VERSION ""

NS_ :

BS_:

BU_: IVI ZCU_F

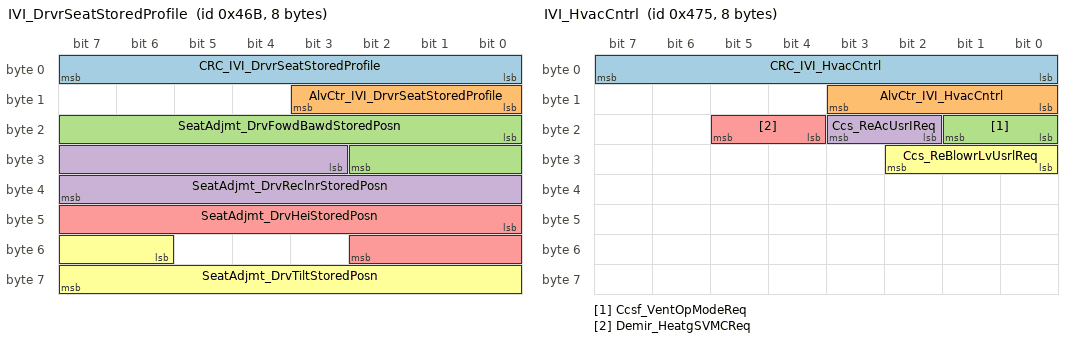
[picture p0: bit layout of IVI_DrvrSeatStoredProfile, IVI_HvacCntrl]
BO_ 1131 IVI_DrvrSeatStoredProfile: 8 IVI
 SG_ CRC_IVI_DrvrSeatStoredProfile : 0|8@1+ (1,0) [0|255] ""  ZCU_F
 SG_ AlvCtr_IVI_DrvrSeatStoredProfile : 8|4@1+ (1,0) [0|14] ""  ZCU_F
 SG_ SeatAdjmt_DrvFowdBawdStoredPosn : 16|11@1+ (1,0) [0|1400] "Count"  ZCU_F
 SG_ SeatAdjmt_DrvReclnrStoredPosn : 27|13@1+ (1,0) [0|5000] "Count"  ZCU_F
 SG_ SeatAdjmt_DrvHeiStoredPosn : 40|11@1+ (1,0) [0|1600] "Count"  ZCU_F
 SG_ SeatAdjmt_DrvTiltStoredPosn : 54|10@1+ (1,0) [0|1000] "Count"  ZCU_F

BO_ 1140 TBOX_DrvrId_Info: 16 ZCU_F
 SG_ DriverId_Byte1 : 0|8@1+ (1,0) [0|255] ""  IVI
 SG_ DriverId_Byte2 : 8|8@1+ (1,0) [0|255] ""  IVI
 SG_ DriverId_Byte3 : 16|8@1+ (1,0) [0|255] ""  IVI
 SG_ DriverId_Byte4 : 24|8@1+ (1,0) [0|255] ""  IVI
 SG_ DriverId_Byte5 : 32|8@1+ (1,0) [0|255] ""  IVI
 SG_ DriverId_Byte6 : 40|8@1+ (1,0) [0|255] ""  IVI
 SG_ DriverId_Byte7 : 48|8@1+ (1,0) [0|255] ""  IVI
 SG_ DriverId_Byte8 : 56|8@1+ (1,0) [0|255] ""  IVI
 SG_ DriverId_Byte9 : 64|8@1+ (1,0) [0|255] ""  IVI
 SG_ DriverId_Byte10 : 72|8@1+ (1,0) [0|255] ""  IVI
 SG_ DriverId_Byte11 : 80|8@1+ (1,0) [0|255] ""  IVI
 SG_ DriverId_Byte12 : 88|8@1+ (1,0) [0|255] ""  IVI
 SG_ DriverId_Byte13 : 96|8@1+ (1,0) [0|255] ""  IVI
 SG_ DriverId_Byte14 : 104|8@1+ (1,0) [0|255] ""  IVI
 SG_ DriverId_Byte15 : 112|8@1+ (1,0) [0|255] ""  IVI
 SG_ DriverId_Byte16 : 120|8@1+ (1,0) [0|255] ""  IVI

BO_ 1141 IVI_HvacCntrl: 8 IVI
 SG_ CRC_IVI_HvacCntrl : 0|8@1+ (1,0) [0|255] ""  ZCU_F
 SG_ AlvCtr_IVI_HvacCntrl : 8|4@1+ (1,0) [0|14] ""  ZCU_F
 SG_ Ccsf_VentOpModeReq : 16|2@1+ (1,0) [0|3] ""  ZCU_F
 SG_ Ccs_ReAcUsrIReq : 18|2@1+ (1,0) [0|3] ""  ZCU_F
 SG_ Demir_HeatgSVMCReq : 20|2@1+ (1,0) [0|3] ""  ZCU_F
 SG_ Ccs_ReBlowrLvUsrlReq : 24|3@1+ (1,0) [0|7] ""  ZCU_F

BO_ 1147 IVI_HvacSwt_Req: 8 IVI
 SG_ Ccs_AcMinTUsrBtn : 0|2@1+ (1,0) [0|3] ""  ZCU_F
 SG_ Ccs_AcMaxTUsrBtn : 2|2@1+ (1,0) [0|3] ""  ZCU_F
 SG_ Ccs_RclOnOffReq : 4|2@1+ (1,0) [0|3] ""  ZCU_F
 SG_ Ccs_FrntAcUsrReq : 6|2@1+ (1,0) [0|3] ""  ZCU_F
 SG_ Ccs_ReLeTUsrSetReq : 8|4@1+ (1,16) [16|28] "°C"  ZCU_F
 SG_ Ccs_ReRiTUsrISetVal : 12|4@1+ (1,16) [16|28] "°C"  ZCU_F
 SG_ Ccs_SyncTReq : 16|2@1+ (1,0) [0|3] ""  ZCU_F
 SG_ Ccs_AcEcoModeBtnUsrReq : 18|2@1+ (1,0) [0|3] ""  ZCU_F
 SG_ Ccs_FrntAcAutoModUsrReq : 20|2@1+ (1,0) [0|3] ""  ZCU_F
 SG_ Ccs_IoniserUsrReq : 22|2@1+ (1,0) [0|3] ""  ZCU_F
 SG_ Ccs_FrgrncAcvnUsrReq : 24|2@1+ (1,0) [0|3] ""  ZCU_F
 SG_ Ccs_DemistDefrstUsrReq : 26|2@1+ (1,0) [0|3] ""  ZCU_F
 SG_ Ccs_FrntLeTUsrSetVal : 28|4@1+ (1,16) [16|28] "°C"  ZCU_F
 SG_ Ccs_FrgrncIntenUsrReq : 32|4@1+ (10,0) [0|100] ""  ZCU_F
 SG_ Ccs_FrntBlowrLvlUsrReq : 40|3@1+ (1,0) [0|7] ""  ZCU_F
 SG_ Ccs_AirModeSelnUsrReq : 43|3@1+ (1,0) [0|7] ""  ZCU_F
 SG_ Ccs_FrntRiTUsrSetVal : 48|4@1+ (1,16) [16|28] "°C"  ZCU_F
 SG_ Ccs_ClimPrsetUsrReq : 52|3@1+ (1,0) [0|7] ""  ZCU_F
 SG_ Ccs_FrgrncSlenUsrReq : 56|3@1+ (1,0) [0|7] ""  ZCU_F
 SG_ Ccs_ClimPrflSelnUsrReq : 59|3@1+ (1,0) [0|7] ""  ZCU_F

BO_ 1157 IVI_UsrBodyCntrl_Req: 32 IVI
 SG_ CRC_IVI_UsrBodyCntrl_Req : 0|16@1+ (1,0) [0|65535] ""  ZCU_F
 SG_ AlvCtr_IVI_UsrBodyCntrl_Req : 16|8@1+ (1,0) [0|255] ""  ZCU_F
 SG_ ChrgrPort_ChrgPortLckUnlckUsrReq : 24|2@1+ (1,0) [0|3] ""  ZCU_F
 SG_ Demir_FoldUnfoldSVMCReq : 26|2@1+ (1,0) [0|3] ""  ZCU_F
 SG_ Demir_FoldUnfoldUsrReq : 28|2@1+ (1,0) [0|3] ""  ZCU_F
 SG_ Demir_HeatgSVMC_Ena : 30|2@1+ (1,0) [0|3] ""  ZCU_F
 SG_ Acttg_TailGateUsrAgReq : 32|7@1+ (1,0) [0|100] "%"  ZCU_F
 SG_ Acttg_TailGateUsrReq : 40|2@1+ (1,0) [0|3] ""  ZCU_F
 SG_ Ssadl_AutoSpdLockVal : 42|6@1+ (1,0) [0|50] "kmph"  ZCU_F
 SG_ Ssadl_AutoSpdLockOnOffTypSts : 48|2@1+ (1,0) [0|3] ""  ZCU_F
 SG_ Relamp_ReFogLiReq : 50|2@1+ (1,0) [0|3] ""  ZCU_F
 SG_ Hdlamp_LampReq : 52|2@1+ (1,0) [0|3] ""  ZCU_F
 SG_ Hdlamp_AutoModeCfgReq : 54|2@1+ (1,0) [0|3] ""  ZCU_F
 SG_ Hdlamp_FollowMeCfg : 56|3@1+ (1,0) [0|7] ""  ZCU_F
 SG_ Wipr_FrntWiprReq : 59|3@1+ (1,0) [0|7] ""  ZCU_F
 SG_ Wipr_FrntOperParkReq : 62|2@1+ (1,0) [0|3] ""  ZCU_F
 SG_ Wipr_FrntWiprSrvPosReq : 64|2@1+ (1,0) [0|3] ""  ZCU_F

BO_ 1163 IVI_UsrChassisCntrl_Req: 32 IVI
 SG_ CRC_IVI_UsrChassisCntrl_Req : 0|16@1+ (1,0) [0|65535] ""  ZCU_F
 SG_ AlvCtr_IVI_UsrChassisCntrl_Req : 16|8@1+ (1,0) [0|255] ""  ZCU_F
 SG_ Hdc_SwtSts : 24|2@1+ (1,0) [0|3] ""  ZCU_F
 SG_ EscTcs_SwtSts : 26|2@1+ (1,0) [0|3] ""  ZCU_F
 SG_ IVI_IngrsModeCmd : 28|2@1+ (1,0) [0|3] ""  ZCU_F
 SG_ AVH_Swt_Sts : 30|2@1+ (1,0) [0|3] ""  ZCU_F
 SG_ IVI_SuspHeiAdjReq : 32|3@1+ (1,0) [0|7] ""  ZCU_F
 SG_ IVI_SrvModCmd : 35|2@1+ (1,0) [0|3] ""  ZCU_F

BO_ 1173 IVI_UsrSeatAdjComfrt_Req: 8 IVI
 SG_ CRC_IVI_UsrSeatAdjComfrt_Req : 0|8@1+ (1,0) [0|255] ""  ZCU_F
 SG_ AlvCtr_IVI_UsrSeatAdjComfrt_Req : 8|4@1+ (1,0) [0|14] ""  ZCU_F
 SG_ SeatAdjmt_DrvFowdBawdReq : 16|2@1+ (1,0) [0|3] ""  ZCU_F
 SG_ SeatAdjmt_DrvHeiUpDwnReq : 18|2@1+ (1,0) [0|3] ""  ZCU_F
 SG_ SeatAdjmt_DrvLumInOutReq : 20|2@1+ (1,0) [0|3] ""  ZCU_F
 SG_ SeatAdjmt_DrvLumUpDwnReq : 22|2@1+ (1,0) [0|3] ""  ZCU_F
 SG_ SeatAdjmt_DrvReclUpDownReq : 24|2@1+ (1,0) [0|3] ""  ZCU_F
 SG_ SeatCfmt_DrvMassgIntenSelnReq : 26|3@1+ (1,0) [0|7] ""  ZCU_F
 SG_ SeatCfmt_DrvMassgPatSelnReq : 29|3@1+ (1,0) [0|7] ""  ZCU_F
 SG_ SeatAdjmt_PassFowdBawdReq : 32|2@1+ (1,0) [0|3] ""  ZCU_F
 SG_ SeatAdjmt_PassHeiUpDwnReq : 34|2@1+ (1,0) [0|3] ""  ZCU_F
 SG_ SeatAdjmt_PassLumInOutReq : 36|2@1+ (1,0) [0|3] ""  ZCU_F
 SG_ SeatAdjmt_PassLumUpDwnReq : 38|2@1+ (1,0) [0|3] ""  ZCU_F
 SG_ SeatAdjmt_PassReclUpDownReq : 40|2@1+ (1,0) [0|3] ""  ZCU_F
 SG_ SeatAdjmt_PassTiltUpDwnReq : 42|2@1+ (1,0) [0|3] ""  ZCU_F
 SG_ SeatAdjmt_DrvTiltUpDwnReq : 44|2@1+ (1,0) [0|3] ""  ZCU_F
 SG_ SeatCfmt_PassMassgIntenSelnReq : 48|3@1+ (1,0) [0|7] ""  ZCU_F
 SG_ SeatCfmt_PassMassgPatSelnReq : 51|3@1+ (1,0) [0|7] ""  ZCU_F
 SG_ SeatCfmt_ReLeVentnSpdReq : 56|3@1+ (1,0) [0|7] ""  ZCU_F
 SG_ SeatCfmt_ReRiVentnSpdReq : 59|3@1+ (1,0) [0|7] ""  ZCU_F

BO_ 1179 IVI_Vehicle_Mode_Ctrl: 32 IVI
 SG_ CRC_IVI_Vehicle_Mode_Ctrl : 0|16@1+ (1,0) [0|65535] ""  ZCU_F
 SG_ AlvCtr_IVI_Vehicle_Mode_Ctrl : 16|8@1+ (1,0) [0|255] ""  ZCU_F
 SG_ Klss_UsrVehPwrDnReq : 24|2@1+ (1,0) [0|3] ""  ZCU_F
 SG_ HMI_KeepAlive : 26|2@1+ (1,0) [0|3] ""  ZCU_F
 SG_ Lvm_LongParkMode_Req : 28|2@1+ (1,0) [0|3] ""  ZCU_F
 SG_ Lvm_StorageMode_Req : 30|2@1+ (1,0) [0|3] ""  ZCU_F
 SG_ Drvmc_Mode_Req : 32|3@1+ (1,0) [0|7] ""  ZCU_F
 SG_ Eshift_TagtGear_Req : 35|3@1+ (1,0) [0|7] ""  ZCU_F

BO_ 1411 TBOX_Warning: 32 ZCU_F
 SG_ CRC_TBOX_Warning : 0|16@1+ (1,0) [0|65535] ""  IVI
 SG_ AlvCtr_TBOX_Warning : 16|8@1+ (1,0) [0|255] ""  IVI
 SG_ Kle_NfcCcCardVldtn_St_Warn : 24|2@1+ (1,0) [0|3] ""  IVI

BO_ 1412 VCU_Warning: 32 ZCU_F
 SG_ CRC_VCU_Warning : 0|16@1+ (1,0) [0|65535] ""  IVI
 SG_ AlvCtr_VCU_Warning : 16|8@1+ (1,0) [0|255] ""  IVI
 SG_ Acchg_ChgGunUnlckWarn : 24|2@1+ (1,0) [0|3] ""  IVI
 SG_ Hvsco_HV_SysWarn : 26|2@1+ (1,0) [0|3] ""  IVI
 SG_ Thmgt_CooltOverTWarn : 28|2@1+ (1,0) [0|3] ""  IVI
 SG_ Eshift_PsdBrkToEngeGear : 30|2@1+ (1,0) [0|3] ""  IVI
 SG_ Awd_WhlDrvModeWarn : 32|2@1+ (1,0) [0|3] ""  IVI
 SG_ Drvmc_DrvModeChngRestrWarn : 34|2@1+ (1,0) [0|3] ""  IVI
 SG_ Eshift_HvDcnctNoGearChngWarn : 36|2@1+ (1,0) [0|3] ""  IVI
 SG_ Eshift_GearChng_EPBEngeWarn : 38|2@1+ (1,0) [0|3] ""  IVI
 SG_ Thmgt_CooltLvlLoWarn : 40|2@1+ (1,0) [0|3] ""  IVI
 SG_ Eshift_StopVehToMoveFowdDir : 42|2@1+ (1,0) [0|3] ""  IVI
 SG_ Hvsft_HvsftSts : 44|2@1+ (1,0) [0|3] ""  IVI
 SG_ VCU_LimphmWarn : 46|2@1+ (1,0) [0|3] ""  IVI
 SG_ Eshift_EppFaiWarn : 48|2@1+ (1,0) [0|3] ""  IVI
 SG_ Thmgt_Therm_FltWarn : 50|2@1+ (1,0) [0|3] ""  IVI
 SG_ Acchr_ChgAuthWarn : 52|2@1+ (1,0) [0|3] ""  IVI
 SG_ Eshift_ACT_GearWarn : 54|2@1+ (1,0) [0|3] ""  IVI
 SG_ Eshift_TagtGearVldtnWarn : 56|2@1+ (1,0) [0|3] ""  IVI
 SG_ Hvsft_HvilErrWarn : 58|2@1+ (1,0) [0|3] ""  IVI
 SG_ Eshift_StopVehToMoveRvsDir : 60|2@1+ (1,0) [0|3] ""  IVI
 SG_ VCU_HV_Sys_FltLvl1Warn : 62|2@1+ (1,0) [0|3] ""  IVI
 SG_ VCU_HV_Sys_FltLvl2Warn : 64|2@1+ (1,0) [0|3] ""  IVI
 SG_ VCU_HV_Sys_FltLvl3Warn : 66|2@1+ (1,0) [0|3] ""  IVI
 SG_ Cregb_CoastRgnWarn : 68|2@1+ (1,0) [0|3] ""  IVI

BO_ 1413 ZCUF_Warning: 32 ZCU_F
 SG_ CRC_ZCUF_Warning : 0|16@1+ (1,0) [0|65535] ""  IVI
 SG_ AlvCtr_ZCUF_Warning : 16|8@1+ (1,0) [0|255] ""  IVI
 SG_ CenLock_LockUnlckSts_Warn : 24|2@1+ (1,0) [0|3] ""  IVI
 SG_ Wipr_FrntRiFaild_Warn : 26|2@1+ (1,0) [0|3] ""  IVI
 SG_ SwtCtl_PassSeatHeatingSwFlt_Warn : 28|2@1+ (1,0) [0|3] ""  IVI
 SG_ SwtCtl_VolSwtFlt_Warn : 30|2@1+ (1,0) [0|3] ""  IVI
 SG_ Wipr_FrntLeFaild_Warn : 32|2@1+ (1,0) [0|3] ""  IVI
 SG_ SwttCtl_DrvrStHeatngSwtFlt_Wrn : 34|2@1+ (1,0) [0|3] ""  IVI
 SG_ Relamp_RevLmpWarn : 36|2@1+ (1,0) [0|3] ""  IVI
 SG_ RLML_FogLmp_Warn : 38|2@1+ (1,0) [0|3] ""  IVI
 SG_ SwtCtl_ChdLockSwtFault_Warn : 40|2@1+ (1,0) [0|3] ""  IVI
 SG_ SwttCtl_ReclrnModOnOffSwtFlt_Wrn : 42|2@1+ (1,0) [0|3] ""  IVI
 SG_ RLMR_FogLmp_Warn : 44|2@1+ (1,0) [0|3] ""  IVI
 SG_ Relamp_Chmsl_Warn : 46|2@1+ (1,0) [0|3] ""  IVI
 SG_ SwtCtl_HzrdSwtFlt_Warn : 48|2@1+ (1,0) [0|3] ""  IVI
 SG_ Ssadl_DoorAct_Warn : 50|2@1+ (1,0) [0|3] ""  IVI
 SG_ Ssadl_DoorAjar_Warn : 52|2@1+ (1,0) [0|3] ""  IVI
 SG_ Ccs_SrvWarn : 54|2@1+ (1,0) [0|3] ""  IVI

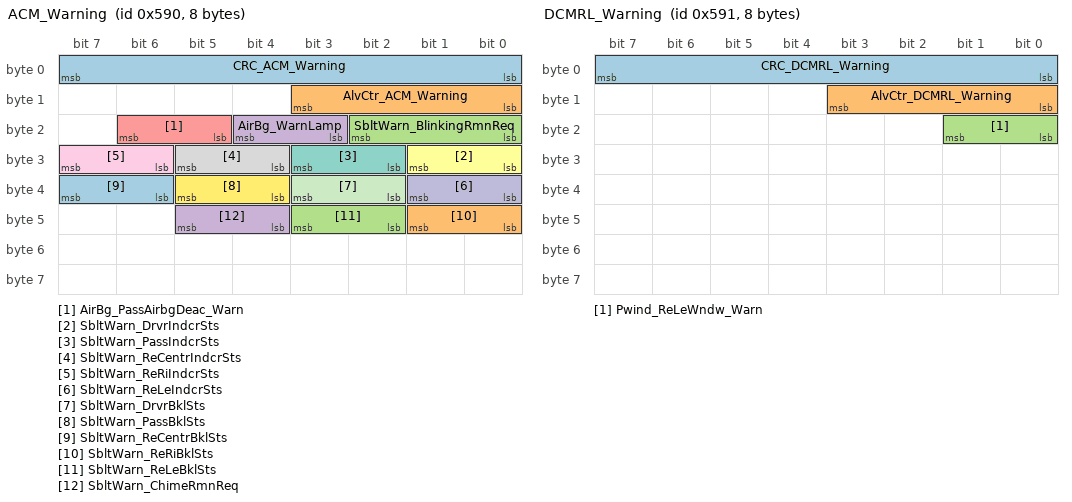
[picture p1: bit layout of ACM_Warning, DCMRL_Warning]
BO_ 1424 ACM_Warning: 8 ZCU_F
 SG_ CRC_ACM_Warning : 0|8@1+ (1,0) [0|255] ""  IVI
 SG_ AlvCtr_ACM_Warning : 8|4@1+ (1,0) [0|14] ""  IVI
 SG_ SbltWarn_BlinkingRmnReq : 16|3@1+ (1,0) [0|7] ""  IVI
 SG_ AirBg_WarnLamp : 19|2@1+ (1,0) [0|3] ""  IVI
 SG_ AirBg_PassAirbgDeac_Warn : 21|2@1+ (1,0) [0|3] ""  IVI
 SG_ SbltWarn_DrvrIndcrSts : 24|2@1+ (1,0) [0|3] ""  IVI
 SG_ SbltWarn_PassIndcrSts : 26|2@1+ (1,0) [0|3] ""  IVI
 SG_ SbltWarn_ReCentrIndcrSts : 28|2@1+ (1,0) [0|3] ""  IVI
 SG_ SbltWarn_ReRiIndcrSts : 30|2@1+ (1,0) [0|3] ""  IVI
 SG_ SbltWarn_ReLeIndcrSts : 32|2@1+ (1,0) [0|3] ""  IVI
 SG_ SbltWarn_DrvrBklSts : 34|2@1+ (1,0) [0|3] ""  IVI
 SG_ SbltWarn_PassBklSts : 36|2@1+ (1,0) [0|3] ""  IVI
 SG_ SbltWarn_ReCentrBklSts : 38|2@1+ (1,0) [0|3] ""  IVI
 SG_ SbltWarn_ReRiBklSts : 40|2@1+ (1,0) [0|3] ""  IVI
 SG_ SbltWarn_ReLeBklSts : 42|2@1+ (1,0) [0|3] ""  IVI
 SG_ SbltWarn_ChimeRmnReq : 44|2@1+ (1,0) [0|3] ""  IVI

BO_ 1425 DCMRL_Warning: 8 ZCU_F
 SG_ CRC_DCMRL_Warning : 0|8@1+ (1,0) [0|255] ""  IVI
 SG_ AlvCtr_DCMRL_Warning : 8|4@1+ (1,0) [0|14] ""  IVI
 SG_ Pwind_ReLeWndw_Warn : 16|2@1+ (1,0) [0|3] ""  IVI

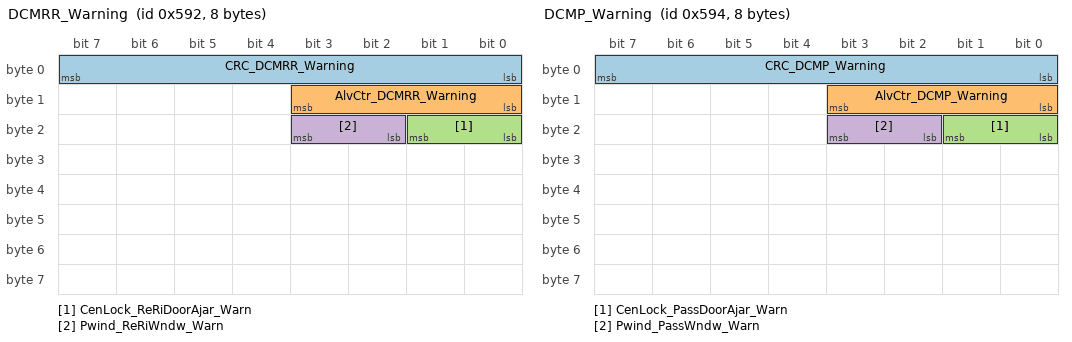
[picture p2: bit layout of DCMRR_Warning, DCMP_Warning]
BO_ 1426 DCMRR_Warning: 8 ZCU_F
 SG_ CRC_DCMRR_Warning : 0|8@1+ (1,0) [0|255] ""  IVI
 SG_ AlvCtr_DCMRR_Warning : 8|4@1+ (1,0) [0|14] ""  IVI
 SG_ CenLock_ReRiDoorAjar_Warn : 16|2@1+ (1,0) [0|3] ""  IVI
 SG_ Pwind_ReRiWndw_Warn : 18|2@1+ (1,0) [0|3] ""  IVI

BO_ 1427 ASU_Warning: 32 ZCU_F
 SG_ CRC_ASU_Warning : 0|16@1+ (1,0) [0|65535] ""  IVI
 SG_ AlvCtr_ASU_Warning : 16|8@1+ (1,0) [0|255] ""  IVI
 SG_ AirSuspUnit_Warn : 24|2@1+ (1,0) [0|3] ""  IVI
 SG_ AirSuspUnit_SrvModeNotActvdWarn : 26|2@1+ (1,0) [0|3] ""  IVI

BO_ 1428 DCMP_Warning: 8 ZCU_F
 SG_ CRC_DCMP_Warning : 0|8@1+ (1,0) [0|255] ""  IVI
 SG_ AlvCtr_DCMP_Warning : 8|4@1+ (1,0) [0|14] ""  IVI
 SG_ CenLock_PassDoorAjar_Warn : 16|2@1+ (1,0) [0|3] ""  IVI
 SG_ Pwind_PassWndw_Warn : 18|2@1+ (1,0) [0|3] ""  IVI

BO_ 1429 BMS_Warning: 32 ZCU_F
 SG_ CRC_BMS_Warning : 0|16@1+ (1,0) [0|65535] ""  IVI
 SG_ AlvCtr_BMS_Warning : 16|8@1+ (1,0) [0|255] ""  IVI
 SG_ Bms_CellUDifErrWarn : 24|2@1+ (1,0) [0|3] ""  IVI
 SG_ Bms_CooltInletTSnsrFltWarn : 26|2@1+ (1,0) [0|3] ""  IVI
 SG_ Bms_CooltOutlTSnsrFltWarn : 28|2@1+ (1,0) [0|3] ""  IVI
 SG_ Bms_DCFCNegRlyErrWarn : 30|2@1+ (1,0) [0|3] ""  IVI
 SG_ Bms_DCFCPosRlyErrWarn : 32|2@1+ (1,0) [0|3] ""  IVI
 SG_ Bms_CtctrDcnctRsnWarn : 34|2@1+ (1,0) [0|3] ""  IVI
 SG_ Bms_ErrLevWarn : 36|2@1+ (1,0) [0|3] ""  IVI
 SG_ Bms_FuseStsErrWarn : 38|2@1+ (1,0) [0|3] ""  IVI
 SG_ Bms_HvilErrWarn : 40|2@1+ (1,0) [0|3] ""  IVI
 SG_ Bms_LoBatWarn : 42|2@1+ (1,0) [0|3] ""  IVI
 SG_ Bms_MainPosRlyErrWarn : 44|2@1+ (1,0) [0|3] ""  IVI
 SG_ Bms_PackHvErrWarn : 46|2@1+ (1,0) [0|3] ""  IVI
 SG_ Bms_PackInsuErrWarn : 48|2@1+ (1,0) [0|3] ""  IVI
 SG_ Bms_PackLvErrWarn : 50|2@1+ (1,0) [0|3] ""  IVI
 SG_ Bms_PackOvcurErrWarn : 52|2@1+ (1,0) [0|3] ""  IVI
 SG_ Bms_PackTStsWarn : 54|2@1+ (1,0) [0|3] ""  IVI
 SG_ Bms_PreChRlyErrWarn : 56|2@1+ (1,0) [0|3] ""  IVI
 SG_ Bms_CellOverTErrWarn : 58|2@1+ (1,0) [0|3] ""  IVI
 SG_ Bms_CellUnderTErrWarn : 60|2@1+ (1,0) [0|3] ""  IVI
 SG_ Bms_RvsIDetChgFltWarn : 62|2@1+ (1,0) [0|3] ""  IVI
 SG_ Bms_ScIFltWarn : 64|2@1+ (1,0) [0|3] ""  IVI
 SG_ Bms_SocChngFastFltWarn : 66|2@1+ (1,0) [0|3] ""  IVI
 SG_ Bms_SrvDueDetnWarn : 68|2@1+ (1,0) [0|3] ""  IVI
 SG_ Bms_ThermRunawayWarn : 70|2@1+ (1,0) [0|3] ""  IVI
 SG_ Bms_TotNegRlyErrWarn : 72|2@1+ (1,0) [0|3] ""  IVI
 SG_ Bms_BatBalErrWarn : 74|2@1+ (1,0) [0|3] ""  IVI
 SG_ Bms_BatReplWarn : 76|2@1+ (1,0) [0|3] ""  IVI
 SG_ Bms_CellHvErrWarn : 78|2@1+ (1,0) [0|3] ""  IVI
 SG_ Bms_CellLvErrWarn : 80|2@1+ (1,0) [0|3] ""  IVI

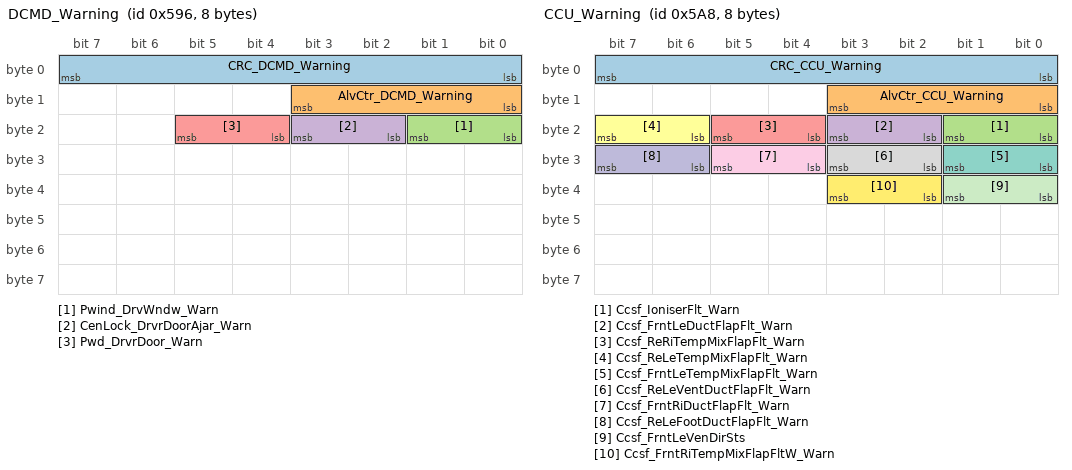
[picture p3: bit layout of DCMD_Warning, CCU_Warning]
BO_ 1430 DCMD_Warning: 8 ZCU_F
 SG_ CRC_DCMD_Warning : 0|8@1+ (1,0) [0|255] ""  IVI
 SG_ AlvCtr_DCMD_Warning : 8|4@1+ (1,0) [0|14] ""  IVI
 SG_ Pwind_DrvWndw_Warn : 16|2@1+ (1,0) [0|3] ""  IVI
 SG_ CenLock_DrvrDoorAjar_Warn : 18|2@1+ (1,0) [0|3] ""  IVI
 SG_ Pwd_DrvrDoor_Warn : 20|2@1+ (1,0) [0|3] ""  IVI

BO_ 1432 EBCM_Warning: 32 ZCU_F
 SG_ CRC_EBCM_Warning : 0|16@1+ (1,0) [0|65535] ""  IVI
 SG_ AlvCtr_EBCM_Warning : 16|8@1+ (1,0) [0|255] ""  IVI
 SG_ Ecpbk_SwtFlt : 24|2@1+ (1,0) [0|3] ""  IVI
 SG_ Ecpbk_InclndVehParkWarn : 26|2@1+ (1,0) [0|3] ""  IVI
 SG_ Ecpbk_BrkFNotEnWarn : 28|2@1+ (1,0) [0|3] ""  IVI
 SG_ Brb_RgnWarn : 30|2@1+ (1,0) [0|3] ""  IVI
 SG_ Ecpbk_NotAppldDoorOpenWarn : 32|2@1+ (1,0) [0|3] ""  IVI
 SG_ Ecpbk_RollrBenchModeWarn : 34|2@1+ (1,0) [0|3] ""  IVI
 SG_ Ecpbk_AutoRelsWarn : 36|2@1+ (1,0) [0|3] ""  IVI
 SG_ Ecpbk_RlsdMntnModeWarn : 38|2@1+ (1,0) [0|3] ""  IVI
 SG_ Ecpbk_RlsdTwModeWarn : 40|2@1+ (1,0) [0|3] ""  IVI
 SG_ Ecpbk_AutoAppldWarn : 42|2@1+ (1,0) [0|3] ""  IVI
 SG_ Drvac_HillStrtAssiFltWarn : 44|2@1+ (1,0) [0|3] ""  IVI
 SG_ Ebd_SysWarn : 46|2@1+ (1,0) [0|3] ""  IVI
 SG_ Drvac_CorneringBrkCtlFltWarn : 48|2@1+ (1,0) [0|3] ""  IVI
 SG_ Drvac_HdcWarn : 50|2@1+ (1,0) [0|3] ""  IVI
 SG_ Drvac_FldLvlIndcrBrkFldWarn : 52|2@1+ (1,0) [0|3] ""  IVI
 SG_ Drvac_TcsWarn : 54|2@1+ (1,0) [0|3] ""  IVI
 SG_ Ecpbk_PsdBrkPedlToRelsEpbWarn : 56|2@1+ (1,0) [0|3] ""  IVI
 SG_ Ecpbk_WarnLampSt : 58|2@1+ (1,0) [0|3] ""  IVI
 SG_ Ecpbk_ParkBrkFltWarn : 60|2@1+ (1,0) [0|3] ""  IVI
 SG_ Ecpbk_DegradedModeToBeRlsdWarn : 62|2@1+ (1,0) [0|3] ""  IVI
 SG_ Ecpbk_DegradedModeRlsdWarn : 64|2@1+ (1,0) [0|3] ""  IVI
 SG_ Abs_FltWarn : 66|2@1+ (1,0) [0|3] ""  IVI

BO_ 1434 OBC_Warning: 32 ZCU_F
 SG_ CRC_OBC_Warning : 0|16@1+ (1,0) [0|65535] ""  IVI
 SG_ AlvCtr_OBC_Warning : 16|8@1+ (1,0) [0|255] ""  IVI
 SG_ Acchg_ObcErrWarn : 24|2@1+ (1,0) [0|3] ""  IVI

BO_ 1436 EPS_RWA1_Warning: 32 ZCU_F
 SG_ CRC_EPS_RWA1_Warning : 0|16@1+ (1,0) [0|65535] ""  IVI
 SG_ AlvCtr_EPS_RWA1_Warning : 16|8@1+ (1,0) [0|255] ""  IVI
 SG_ Stbwr_RdndtModeWarn : 24|2@1+ (1,0) [0|3] ""  IVI

BO_ 1437 EPS_SFA1_Warning: 32 ZCU_F
 SG_ CRC_EPS_SFA1_Warning : 0|16@1+ (1,0) [0|65535] ""  IVI
 SG_ AlvCtr_EPS_SFA1_Warning : 16|8@1+ (1,0) [0|255] ""  IVI
 SG_ Stbwr_HptcWarnSts : 24|2@1+ (1,0) [0|3] ""  IVI
 SG_ Stbwr_SfaCluWarnLamp : 26|2@1+ (1,0) [0|3] ""  IVI
 SG_ Stbwr_SteerAlgnmtWarn : 28|2@1+ (1,0) [0|3] ""  IVI

BO_ 1438 EPS_RWA2_Warning: 32 ZCU_F
 SG_ CRC_EPS_RWA2_Warning : 0|16@1+ (1,0) [0|65535] ""  IVI
 SG_ AlvCtr_EPS_RWA2_Warning : 16|8@1+ (1,0) [0|255] ""  IVI
 SG_ Stbwr_RdndtModeWarn_R : 24|2@1+ (1,0) [0|3] ""  IVI

BO_ 1439 EPS_SFA2_Warning: 32 ZCU_F
 SG_ CRC_EPS_SFA2_Warning : 0|16@1+ (1,0) [0|65535] ""  IVI
 SG_ AlvCtr_EPS_SFA2_Warning : 16|8@1+ (1,0) [0|255] ""  IVI
 SG_ Stbwr_HptcWarnSts_R : 24|2@1+ (1,0) [0|3] ""  IVI
 SG_ Stbwr_SfaCluWarnLamp_R : 26|2@1+ (1,0) [0|3] ""  IVI
 SG_ Stbwr_SteerAlgnmtWarn_R : 28|2@1+ (1,0) [0|3] ""  IVI

BO_ 1445 HDLML_Warning: 32 ZCU_F
 SG_ CRC_HDLML_Warning : 0|16@1+ (1,0) [0|65535] ""  IVI
 SG_ AlvCtr_HDLML_Warning : 16|8@1+ (1,0) [0|255] ""  IVI
 SG_ Hdlamp_LeLoBeamLampWarn : 24|2@1+ (1,0) [0|3] ""  IVI
 SG_ Hdlamp_LeHiBeamLampWarn : 26|2@1+ (1,0) [0|3] ""  IVI

BO_ 1446 HDLMR_Warning: 32 ZCU_F
 SG_ CRC_HDLMR_Warning : 0|16@1+ (1,0) [0|65535] ""  IVI
 SG_ AlvCtr_HDLMR_Warning : 16|8@1+ (1,0) [0|255] ""  IVI
 SG_ Hdlamp_RiLoBeamLampWarn : 24|2@1+ (1,0) [0|3] ""  IVI
 SG_ Hdlamp_RiHiBeamLamp_Warn : 26|2@1+ (1,0) [0|3] ""  IVI

BO_ 1447 SBM_Warning: 32 ZCU_F
 SG_ CRC_Sbm_Warning : 0|16@1+ (1,0) [0|65535] ""  IVI
 SG_ AlvCtr_SBM_Warning : 16|8@1+ (1,0) [0|255] ""  IVI
 SG_ Sbm_CriticalSoCAlert_Warn : 24|2@1+ (1,0) [0|3] ""  IVI
 SG_ Sbm_HealthStWarn : 26|2@1+ (1,0) [0|3] ""  IVI
 SG_ Sbm_LvBatTSnsrFltSts_Warn : 28|2@1+ (1,0) [0|3] ""  IVI

BO_ 1448 CCU_Warning: 8 ZCU_F
 SG_ CRC_CCU_Warning : 0|8@1+ (1,0) [0|255] ""  IVI
 SG_ AlvCtr_CCU_Warning : 8|4@1+ (1,0) [0|14] ""  IVI
 SG_ Ccsf_IoniserFlt_Warn : 16|2@1+ (1,0) [0|3] ""  IVI
 SG_ Ccsf_FrntLeDuctFlapFlt_Warn : 18|2@1+ (1,0) [0|3] ""  IVI
 SG_ Ccsf_ReRiTempMixFlapFlt_Warn : 20|2@1+ (1,0) [0|3] ""  IVI
 SG_ Ccsf_ReLeTempMixFlapFlt_Warn : 22|2@1+ (1,0) [0|3] ""  IVI
 SG_ Ccsf_FrntLeTempMixFlapFlt_Warn : 24|2@1+ (1,0) [0|3] ""  IVI
 SG_ Ccsf_ReLeVentDuctFlapFlt_Warn : 26|2@1+ (1,0) [0|3] ""  IVI
 SG_ Ccsf_FrntRiDuctFlapFlt_Warn : 28|2@1+ (1,0) [0|3] ""  IVI
 SG_ Ccsf_ReLeFootDuctFlapFlt_Warn : 30|2@1+ (1,0) [0|3] ""  IVI
 SG_ Ccsf_FrntLeVenDirSts : 32|2@1+ (1,0) [0|3] ""  IVI
 SG_ Ccsf_FrntRiTempMixFlapFltW_Warn : 34|2@1+ (1,0) [0|3] ""  IVI

BO_ 1452 MCU_F_Warning: 32 ZCU_F
 SG_ CRC_MCU_F_Warning : 0|16@1+ (1,0) [0|65535] ""  IVI
 SG_ AlvCtr_MCU_F_Warning : 16|8@1+ (1,0) [0|255] ""  IVI
 SG_ Eds_FrntDeratWarn : 24|2@1+ (1,0) [0|3] ""  IVI
 SG_ Eds_FrntErWarn : 26|2@1+ (1,0) [0|3] ""  IVI
 SG_ Eds_FrntParkLockErrWarn : 28|2@1+ (1,0) [0|3] ""  IVI

BO_ 1453 MCU_R_Warning: 32 ZCU_F
 SG_ CRC_MCU_R_Warning : 0|16@1+ (1,0) [0|65535] ""  IVI
 SG_ AlvCtr_MCU_R_Warning : 16|8@1+ (1,0) [0|255] ""  IVI
 SG_ Eds_ReParkLockErrWarn : 24|2@1+ (1,0) [0|3] ""  IVI
 SG_ Eds_ReErrWarn : 26|2@1+ (1,0) [0|3] ""  IVI
 SG_ Eds_ReDeratWarn : 28|2@1+ (1,0) [0|3] ""  IVI

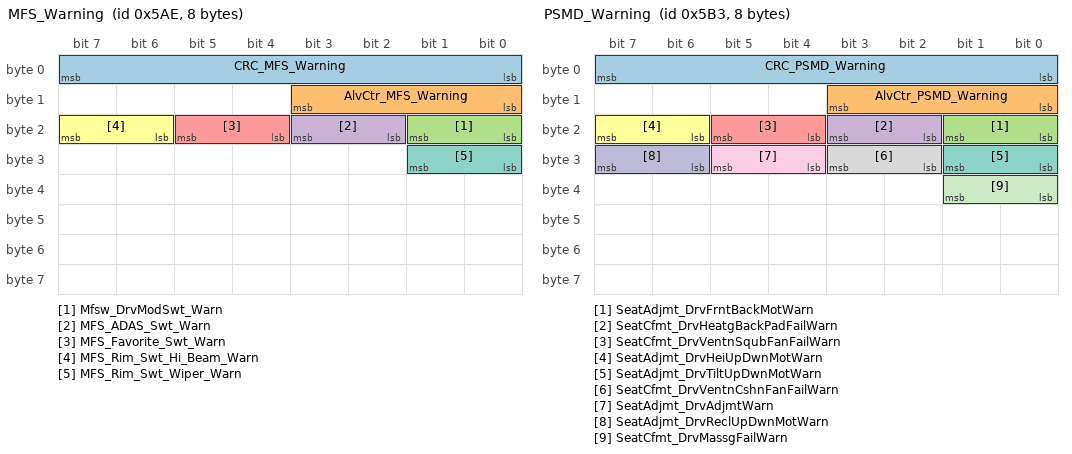
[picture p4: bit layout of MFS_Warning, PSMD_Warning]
BO_ 1454 MFS_Warning: 8 ZCU_F
 SG_ CRC_MFS_Warning : 0|8@1+ (1,0) [0|255] ""  IVI
 SG_ AlvCtr_MFS_Warning : 8|4@1+ (1,0) [0|14] ""  IVI
 SG_ Mfsw_DrvModSwt_Warn : 16|2@1+ (1,0) [0|3] ""  IVI
 SG_ MFS_ADAS_Swt_Warn : 18|2@1+ (1,0) [0|3] ""  IVI
 SG_ MFS_Favorite_Swt_Warn : 20|2@1+ (1,0) [0|3] ""  IVI
 SG_ MFS_Rim_Swt_Hi_Beam_Warn : 22|2@1+ (1,0) [0|3] ""  IVI
 SG_ MFS_Rim_Swt_Wiper_Warn : 24|2@1+ (1,0) [0|3] ""  IVI

BO_ 1457 DCDC_Warning: 32 ZCU_F
 SG_ CRC_DCDC_Warning : 0|16@1+ (1,0) [0|65535] ""  IVI
 SG_ AlvCtr_DCDC_Warning : 16|8@1+ (1,0) [0|255] ""  IVI
 SG_ Hvsco_DcdcOperWarn : 24|2@1+ (1,0) [0|3] ""  IVI

BO_ 1459 PSMD_Warning: 8 ZCU_F
 SG_ CRC_PSMD_Warning : 0|8@1+ (1,0) [0|255] ""  IVI
 SG_ AlvCtr_PSMD_Warning : 8|4@1+ (1,0) [0|14] ""  IVI
 SG_ SeatAdjmt_DrvFrntBackMotWarn : 16|2@1+ (1,0) [0|3] ""  IVI
 SG_ SeatCfmt_DrvHeatgBackPadFailWarn : 18|2@1+ (1,0) [0|3] ""  IVI
 SG_ SeatCfmt_DrvVentnSqubFanFailWarn : 20|2@1+ (1,0) [0|3] ""  IVI
 SG_ SeatAdjmt_DrvHeiUpDwnMotWarn : 22|2@1+ (1,0) [0|3] ""  IVI
 SG_ SeatAdjmt_DrvTiltUpDwnMotWarn : 24|2@1+ (1,0) [0|3] ""  IVI
 SG_ SeatCfmt_DrvVentnCshnFanFailWarn : 26|2@1+ (1,0) [0|3] ""  IVI
 SG_ SeatAdjmt_DrvAdjmtWarn : 28|2@1+ (1,0) [0|3] ""  IVI
 SG_ SeatAdjmt_DrvReclUpDwnMotWarn : 30|2@1+ (1,0) [0|3] ""  IVI
 SG_ SeatCfmt_DrvMassgFailWarn : 32|2@1+ (1,0) [0|3] ""  IVI

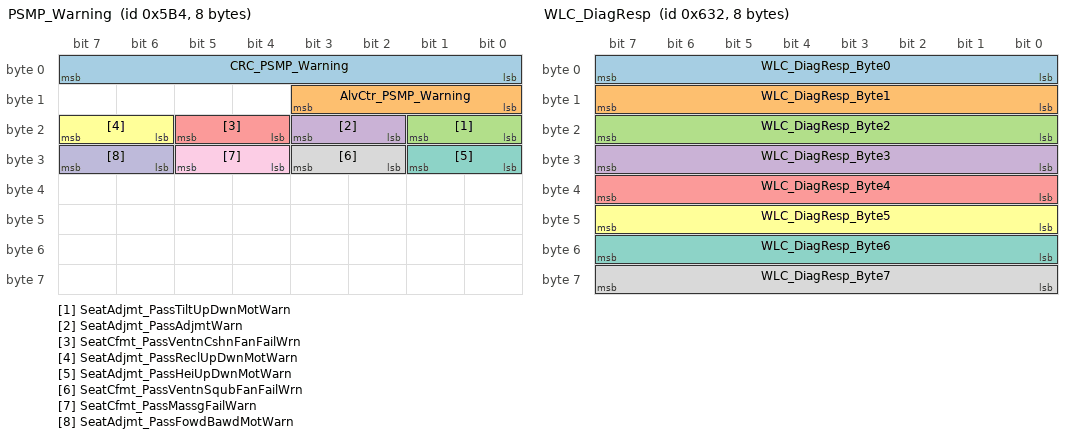
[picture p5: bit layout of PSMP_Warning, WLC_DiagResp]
BO_ 1460 PSMP_Warning: 8 ZCU_F
 SG_ CRC_PSMP_Warning : 0|8@1+ (1,0) [0|255] ""  IVI
 SG_ AlvCtr_PSMP_Warning : 8|4@1+ (1,0) [0|14] ""  IVI
 SG_ SeatAdjmt_PassTiltUpDwnMotWarn : 16|2@1+ (1,0) [0|3] ""  IVI
 SG_ SeatAdjmt_PassAdjmtWarn : 18|2@1+ (1,0) [0|3] ""  IVI
 SG_ SeatCfmt_PassVentnCshnFanFailWrn : 20|2@1+ (1,0) [0|3] ""  IVI
 SG_ SeatAdjmt_PassReclUpDwnMotWarn : 22|2@1+ (1,0) [0|3] ""  IVI
 SG_ SeatAdjmt_PassHeiUpDwnMotWarn : 24|2@1+ (1,0) [0|3] ""  IVI
 SG_ SeatCfmt_PassVentnSqubFanFailWrn : 26|2@1+ (1,0) [0|3] ""  IVI
 SG_ SeatCfmt_PassMassgFailWarn : 28|2@1+ (1,0) [0|3] ""  IVI
 SG_ SeatAdjmt_PassFowdBawdMotWarn : 30|2@1+ (1,0) [0|3] ""  IVI

BO_ 1463 RWSM_Warning: 32 ZCU_F
 SG_ CRC_RWSM_Warning : 0|16@1+ (1,0) [0|65535] ""  IVI
 SG_ AlvCtr_RWSM_Warning : 16|8@1+ (1,0) [0|255] ""  IVI
 SG_ ReWhlSteer_WarnLamp : 24|3@1+ (1,0) [0|7] ""  IVI

BO_ 1464 ZCUR_Warning: 32 ZCU_F
 SG_ CRC_ZCUR_Warning : 0|16@1+ (1,0) [0|65535] ""  IVI
 SG_ AlvCtr_ZCUR_Warning : 16|8@1+ (1,0) [0|255] ""  IVI
 SG_ SeatCfmt_ReLeVentnCshnFanFailWrn : 24|2@1+ (1,0) [0|3] ""  IVI
 SG_ SeatCfmt_ReLeVentnSqubFanFailWrn : 26|2@1+ (1,0) [0|3] ""  IVI
 SG_ SeatCfmt_ReRiVentnCshnFanFailWrn : 28|2@1+ (1,0) [0|3] ""  IVI
 SG_ SeatCfmt_ReRiVentnSqubFanFailWrn : 30|2@1+ (1,0) [0|3] ""  IVI
 SG_ Acttg_TailGate_Warn : 32|2@1+ (1,0) [0|3] ""  IVI
 SG_ ChrgrPort_IlmnLampW_Warn : 34|2@1+ (1,0) [0|3] ""  IVI

BO_ 1472 TLML_Warning: 32 ZCU_F
 SG_ CRC_TLML_Warning : 0|16@1+ (1,0) [0|65535] ""  IVI
 SG_ AlvCtr_TLML_Warning : 16|8@1+ (1,0) [0|255] ""  IVI
 SG_ Relamp_ReLeTLGTurnIndcr_Warn : 24|2@1+ (1,0) [0|3] ""  IVI
 SG_ Relamp_ReLeTLGPosnLamp_Warn : 26|2@1+ (1,0) [0|3] ""  IVI
 SG_ Relamp_LeTLGBrkLamp_Warn : 28|2@1+ (1,0) [0|3] ""  IVI

BO_ 1473 TLMR_Warning: 32 ZCU_F
 SG_ CRC_TLMR_Warning : 0|16@1+ (1,0) [0|65535] ""  IVI
 SG_ AlvCtr_TLMR_Warning : 16|8@1+ (1,0) [0|255] ""  IVI
 SG_ Relamp_RiTLGBrkLamp_Warn : 24|2@1+ (1,0) [0|3] ""  IVI
 SG_ Relamp_ReRiTLGTurnIndcr_Warn : 26|2@1+ (1,0) [0|3] ""  IVI
 SG_ Relamp_ReRiTLGPosnLamp_Warn : 28|2@1+ (1,0) [0|3] ""  IVI

BO_ 1474 RLML_Warning: 32 ZCU_F
 SG_ CRC_RLML_Warning : 0|16@1+ (1,0) [0|65535] ""  IVI
 SG_ AlvCtr_RLML_Warning : 16|8@1+ (1,0) [0|255] ""  IVI
 SG_ Relamp_LeBodyBrkLamp_Warn : 24|2@1+ (1,0) [0|3] ""  IVI
 SG_ Relamp_ReLeBodyTurnIndcr_Warn : 26|2@1+ (1,0) [0|3] ""  IVI

BO_ 1475 RLMR_Warning: 32 ZCU_F
 SG_ CRC_RLMR_Warning : 0|16@1+ (1,0) [0|65535] ""  IVI
 SG_ AlvCtr_RLMR_Warning : 16|8@1+ (1,0) [0|255] ""  IVI
 SG_ Relamp_ReRiBodyTurnIndcr_Warn : 24|2@1+ (1,0) [0|3] ""  IVI
 SG_ Relamp_RiBodyBrkLamp_Warn : 26|2@1+ (1,0) [0|3] ""  IVI

BO_ 1481 SLMFC_Warning: 32 ZCU_F
 SG_ CRC_SLMFC_Warning : 0|16@1+ (1,0) [0|65535] ""  IVI
 SG_ AlvCtr_SLMFC_Warning : 16|8@1+ (1,0) [0|255] ""  IVI
 SG_ Hdlamp_FrntCentr_LeSignLamp_Warn : 24|2@1+ (1,0) [0|3] ""  IVI
 SG_ Hdlamp_FrntCentr_RiSignLamp_Warn : 26|2@1+ (1,0) [0|3] ""  IVI

BO_ 1482 SLMFL_Warning: 32 ZCU_F
 SG_ CRC_SLMFL_Warning : 0|16@1+ (1,0) [0|65535] ""  IVI
 SG_ AlvCtr_SLMFL_Warning : 16|8@1+ (1,0) [0|255] ""  IVI
 SG_ Hdlamp_FrntLeBodyTurnIndcr_Warn : 24|2@1+ (1,0) [0|3] ""  IVI
 SG_ Hdlamp_LeDRLLamp_Warn : 26|2@1+ (1,0) [0|3] ""  IVI
 SG_ Hdlamp_LeFrntPosnLamp_Warn : 28|2@1+ (1,0) [0|3] ""  IVI

BO_ 1483 SLMFR_Warning: 32 ZCU_F
 SG_ CRC_SLMFR_Warning : 0|16@1+ (1,0) [0|65535] ""  IVI
 SG_ AlvCtr_SLMFR_Warning : 16|8@1+ (1,0) [0|255] ""  IVI
 SG_ Hdlamp_FrntRiBodyTurnIndcr_Warn : 24|2@1+ (1,0) [0|3] ""  IVI
 SG_ Hdlamp_RiDRLLamp_Warn : 26|2@1+ (1,0) [0|3] ""  IVI
 SG_ Hdlamp_RiFrntPosnLamp_Warn : 28|2@1+ (1,0) [0|3] ""  IVI

BO_ 1484 SLMRC_Warning: 32 ZCU_F
 SG_ CRC_SLMRC_Warning : 0|16@1+ (1,0) [0|65535] ""  IVI
 SG_ AlvCtr_SLMRC_Warning : 16|8@1+ (1,0) [0|255] ""  IVI
 SG_ Relamp_Centr_RiSignLampSts : 24|2@1+ (1,0) [0|3] ""  IVI
 SG_ Relamp_Centr_LeSignLampSts : 26|2@1+ (1,0) [0|3] ""  IVI

BO_ 1538 IVI_DiagResp: 64 IVI
 SG_ IVI_DiagResp_Byte0 : 0|8@1+ (1,0) [0|255] ""  ZCU_F
 SG_ IVI_DiagResp_Byte1 : 8|8@1+ (1,0) [0|255] ""  ZCU_F
 SG_ IVI_DiagResp_Byte2 : 16|8@1+ (1,0) [0|255] ""  ZCU_F
 SG_ IVI_DiagResp_Byte3 : 24|8@1+ (1,0) [0|255] ""  ZCU_F
 SG_ IVI_DiagResp_Byte4 : 32|8@1+ (1,0) [0|255] ""  ZCU_F
 SG_ IVI_DiagResp_Byte5 : 40|8@1+ (1,0) [0|255] ""  ZCU_F
 SG_ IVI_DiagResp_Byte6 : 48|8@1+ (1,0) [0|255] ""  ZCU_F
 SG_ IVI_DiagResp_Byte7 : 56|8@1+ (1,0) [0|255] ""  ZCU_F
 SG_ IVI_DiagResp_Byte8 : 64|8@1+ (1,0) [0|255] ""  ZCU_F
 SG_ IVI_DiagResp_Byte9 : 72|8@1+ (1,0) [0|255] ""  ZCU_F
 SG_ IVI_DiagResp_Byte10 : 80|8@1+ (1,0) [0|255] ""  ZCU_F
 SG_ IVI_DiagResp_Byte11 : 88|8@1+ (1,0) [0|255] ""  ZCU_F
 SG_ IVI_DiagResp_Byte12 : 96|8@1+ (1,0) [0|255] ""  ZCU_F
 SG_ IVI_DiagResp_Byte13 : 104|8@1+ (1,0) [0|255] ""  ZCU_F
 SG_ IVI_DiagResp_Byte14 : 112|8@1+ (1,0) [0|255] ""  ZCU_F
 SG_ IVI_DiagResp_Byte15 : 120|8@1+ (1,0) [0|255] ""  ZCU_F
 SG_ IVI_DiagResp_Byte16 : 128|8@1+ (1,0) [0|255] ""  ZCU_F
 SG_ IVI_DiagResp_Byte17 : 136|8@1+ (1,0) [0|255] ""  ZCU_F
 SG_ IVI_DiagResp_Byte18 : 144|8@1+ (1,0) [0|255] ""  ZCU_F
 SG_ IVI_DiagResp_Byte19 : 152|8@1+ (1,0) [0|255] ""  ZCU_F
 SG_ IVI_DiagResp_Byte20 : 160|8@1+ (1,0) [0|255] ""  ZCU_F
 SG_ IVI_DiagResp_Byte21 : 168|8@1+ (1,0) [0|255] ""  ZCU_F
 SG_ IVI_DiagResp_Byte22 : 176|8@1+ (1,0) [0|255] ""  ZCU_F
 SG_ IVI_DiagResp_Byte23 : 184|8@1+ (1,0) [0|255] ""  ZCU_F
 SG_ IVI_DiagResp_Byte24 : 192|8@1+ (1,0) [0|255] ""  ZCU_F
 SG_ IVI_DiagResp_Byte25 : 200|8@1+ (1,0) [0|255] ""  ZCU_F
 SG_ IVI_DiagResp_Byte26 : 208|8@1+ (1,0) [0|255] ""  ZCU_F
 SG_ IVI_DiagResp_Byte27 : 216|8@1+ (1,0) [0|255] ""  ZCU_F
 SG_ IVI_DiagResp_Byte28 : 224|8@1+ (1,0) [0|255] ""  ZCU_F
 SG_ IVI_DiagResp_Byte29 : 232|8@1+ (1,0) [0|255] ""  ZCU_F
 SG_ IVI_DiagResp_Byte30 : 240|8@1+ (1,0) [0|255] ""  ZCU_F
 SG_ IVI_DiagResp_Byte31 : 248|8@1+ (1,0) [0|255] ""  ZCU_F
 SG_ IVI_DiagResp_Byte32 : 256|8@1+ (1,0) [0|255] ""  ZCU_F
 SG_ IVI_DiagResp_Byte33 : 264|8@1+ (1,0) [0|255] ""  ZCU_F
 SG_ IVI_DiagResp_Byte34 : 272|8@1+ (1,0) [0|255] ""  ZCU_F
 SG_ IVI_DiagResp_Byte35 : 280|8@1+ (1,0) [0|255] ""  ZCU_F
 SG_ IVI_DiagResp_Byte36 : 288|8@1+ (1,0) [0|255] ""  ZCU_F
 SG_ IVI_DiagResp_Byte37 : 296|8@1+ (1,0) [0|255] ""  ZCU_F
 SG_ IVI_DiagResp_Byte38 : 304|8@1+ (1,0) [0|255] ""  ZCU_F
 SG_ IVI_DiagResp_Byte39 : 312|8@1+ (1,0) [0|255] ""  ZCU_F
 SG_ IVI_DiagResp_Byte40 : 320|8@1+ (1,0) [0|255] ""  ZCU_F
 SG_ IVI_DiagResp_Byte41 : 328|8@1+ (1,0) [0|255] ""  ZCU_F
 SG_ IVI_DiagResp_Byte42 : 336|8@1+ (1,0) [0|255] ""  ZCU_F
 SG_ IVI_DiagResp_Byte43 : 344|8@1+ (1,0) [0|255] ""  ZCU_F
 SG_ IVI_DiagResp_Byte44 : 352|8@1+ (1,0) [0|255] ""  ZCU_F
 SG_ IVI_DiagResp_Byte45 : 360|8@1+ (1,0) [0|255] ""  ZCU_F
 SG_ IVI_DiagResp_Byte46 : 368|8@1+ (1,0) [0|255] ""  ZCU_F
 SG_ IVI_DiagResp_Byte47 : 376|8@1+ (1,0) [0|255] ""  ZCU_F
 SG_ IVI_DiagResp_Byte48 : 384|8@1+ (1,0) [0|255] ""  ZCU_F
 SG_ IVI_DiagResp_Byte49 : 392|8@1+ (1,0) [0|255] ""  ZCU_F
 SG_ IVI_DiagResp_Byte50 : 400|8@1+ (1,0) [0|255] ""  ZCU_F
 SG_ IVI_DiagResp_Byte51 : 408|8@1+ (1,0) [0|255] ""  ZCU_F
 SG_ IVI_DiagResp_Byte52 : 416|8@1+ (1,0) [0|255] ""  ZCU_F
 SG_ IVI_DiagResp_Byte53 : 424|8@1+ (1,0) [0|255] ""  ZCU_F
 SG_ IVI_DiagResp_Byte54 : 432|8@1+ (1,0) [0|255] ""  ZCU_F
 SG_ IVI_DiagResp_Byte55 : 440|8@1+ (1,0) [0|255] ""  ZCU_F
 SG_ IVI_DiagResp_Byte56 : 448|8@1+ (1,0) [0|255] ""  ZCU_F
 SG_ IVI_DiagResp_Byte57 : 456|8@1+ (1,0) [0|255] ""  ZCU_F
 SG_ IVI_DiagResp_Byte58 : 464|8@1+ (1,0) [0|255] ""  ZCU_F
 SG_ IVI_DiagResp_Byte59 : 472|8@1+ (1,0) [0|255] ""  ZCU_F
 SG_ IVI_DiagResp_Byte60 : 480|8@1+ (1,0) [0|255] ""  ZCU_F
 SG_ IVI_DiagResp_Byte61 : 488|8@1+ (1,0) [0|255] ""  ZCU_F
 SG_ IVI_DiagResp_Byte62 : 496|8@1+ (1,0) [0|255] ""  ZCU_F
 SG_ IVI_DiagResp_Byte63 : 504|8@1+ (1,0) [0|255] ""  ZCU_F

BO_ 1586 WLC_DiagResp: 8 IVI
 SG_ WLC_DiagResp_Byte0 : 0|8@1+ (1,0) [0|255] ""  ZCU_F
 SG_ WLC_DiagResp_Byte1 : 8|8@1+ (1,0) [0|255] ""  ZCU_F
 SG_ WLC_DiagResp_Byte2 : 16|8@1+ (1,0) [0|255] ""  ZCU_F
 SG_ WLC_DiagResp_Byte3 : 24|8@1+ (1,0) [0|255] ""  ZCU_F
 SG_ WLC_DiagResp_Byte4 : 32|8@1+ (1,0) [0|255] ""  ZCU_F
 SG_ WLC_DiagResp_Byte5 : 40|8@1+ (1,0) [0|255] ""  ZCU_F
 SG_ WLC_DiagResp_Byte6 : 48|8@1+ (1,0) [0|255] ""  ZCU_F
 SG_ WLC_DiagResp_Byte7 : 56|8@1+ (1,0) [0|255] ""  ZCU_F

BO_ 1666 IVI_DiagReq: 64 ZCU_F
 SG_ IVI_DiagReq_Byte0 : 0|8@1+ (1,0) [0|255] ""  IVI
 SG_ IVI_DiagReq_Byte1 : 8|8@1+ (1,0) [0|255] ""  IVI
 SG_ IVI_DiagReq_Byte2 : 16|8@1+ (1,0) [0|255] ""  IVI
 SG_ IVI_DiagReq_Byte3 : 24|8@1+ (1,0) [0|255] ""  IVI
 SG_ IVI_DiagReq_Byte4 : 32|8@1+ (1,0) [0|255] ""  IVI
 SG_ IVI_DiagReq_Byte5 : 40|8@1+ (1,0) [0|255] ""  IVI
 SG_ IVI_DiagReq_Byte6 : 48|8@1+ (1,0) [0|255] ""  IVI
 SG_ IVI_DiagReq_Byte7 : 56|8@1+ (1,0) [0|255] ""  IVI
 SG_ IVI_DiagReq_Byte8 : 64|8@1+ (1,0) [0|255] ""  IVI
 SG_ IVI_DiagReq_Byte9 : 72|8@1+ (1,0) [0|255] ""  IVI
 SG_ IVI_DiagReq_Byte10 : 80|8@1+ (1,0) [0|255] ""  IVI
 SG_ IVI_DiagReq_Byte11 : 88|8@1+ (1,0) [0|255] ""  IVI
 SG_ IVI_DiagReq_Byte12 : 96|8@1+ (1,0) [0|255] ""  IVI
 SG_ IVI_DiagReq_Byte13 : 104|8@1+ (1,0) [0|255] ""  IVI
 SG_ IVI_DiagReq_Byte14 : 112|8@1+ (1,0) [0|255] ""  IVI
 SG_ IVI_DiagReq_Byte15 : 120|8@1+ (1,0) [0|255] ""  IVI
 SG_ IVI_DiagReq_Byte16 : 128|8@1+ (1,0) [0|255] ""  IVI
 SG_ IVI_DiagReq_Byte17 : 136|8@1+ (1,0) [0|255] ""  IVI
 SG_ IVI_DiagReq_Byte18 : 144|8@1+ (1,0) [0|255] ""  IVI
 SG_ IVI_DiagReq_Byte19 : 152|8@1+ (1,0) [0|255] ""  IVI
 SG_ IVI_DiagReq_Byte20 : 160|8@1+ (1,0) [0|255] ""  IVI
 SG_ IVI_DiagReq_Byte21 : 168|8@1+ (1,0) [0|255] ""  IVI
 SG_ IVI_DiagReq_Byte22 : 176|8@1+ (1,0) [0|255] ""  IVI
 SG_ IVI_DiagReq_Byte23 : 184|8@1+ (1,0) [0|255] ""  IVI
 SG_ IVI_DiagReq_Byte24 : 192|8@1+ (1,0) [0|255] ""  IVI
 SG_ IVI_DiagReq_Byte25 : 200|8@1+ (1,0) [0|255] ""  IVI
 SG_ IVI_DiagReq_Byte26 : 208|8@1+ (1,0) [0|255] ""  IVI
 SG_ IVI_DiagReq_Byte27 : 216|8@1+ (1,0) [0|255] ""  IVI
 SG_ IVI_DiagReq_Byte28 : 224|8@1+ (1,0) [0|255] ""  IVI
 SG_ IVI_DiagReq_Byte29 : 232|8@1+ (1,0) [0|255] ""  IVI
 SG_ IVI_DiagReq_Byte30 : 240|8@1+ (1,0) [0|255] ""  IVI
 SG_ IVI_DiagReq_Byte31 : 248|8@1+ (1,0) [0|255] ""  IVI
 SG_ IVI_DiagReq_Byte32 : 256|8@1+ (1,0) [0|255] ""  IVI
 SG_ IVI_DiagReq_Byte33 : 264|8@1+ (1,0) [0|255] ""  IVI
 SG_ IVI_DiagReq_Byte34 : 272|8@1+ (1,0) [0|255] ""  IVI
 SG_ IVI_DiagReq_Byte35 : 280|8@1+ (1,0) [0|255] ""  IVI
 SG_ IVI_DiagReq_Byte36 : 288|8@1+ (1,0) [0|255] ""  IVI
 SG_ IVI_DiagReq_Byte37 : 296|8@1+ (1,0) [0|255] ""  IVI
 SG_ IVI_DiagReq_Byte38 : 304|8@1+ (1,0) [0|255] ""  IVI
 SG_ IVI_DiagReq_Byte39 : 312|8@1+ (1,0) [0|255] ""  IVI
 SG_ IVI_DiagReq_Byte40 : 320|8@1+ (1,0) [0|255] ""  IVI
 SG_ IVI_DiagReq_Byte41 : 328|8@1+ (1,0) [0|255] ""  IVI
 SG_ IVI_DiagReq_Byte42 : 336|8@1+ (1,0) [0|255] ""  IVI
 SG_ IVI_DiagReq_Byte43 : 344|8@1+ (1,0) [0|255] ""  IVI
 SG_ IVI_DiagReq_Byte44 : 352|8@1+ (1,0) [0|255] ""  IVI
 SG_ IVI_DiagReq_Byte45 : 360|8@1+ (1,0) [0|255] ""  IVI
 SG_ IVI_DiagReq_Byte46 : 368|8@1+ (1,0) [0|255] ""  IVI
 SG_ IVI_DiagReq_Byte47 : 376|8@1+ (1,0) [0|255] ""  IVI
 SG_ IVI_DiagReq_Byte48 : 384|8@1+ (1,0) [0|255] ""  IVI
 SG_ IVI_DiagReq_Byte49 : 392|8@1+ (1,0) [0|255] ""  IVI
 SG_ IVI_DiagReq_Byte50 : 400|8@1+ (1,0) [0|255] ""  IVI
 SG_ IVI_DiagReq_Byte51 : 408|8@1+ (1,0) [0|255] ""  IVI
 SG_ IVI_DiagReq_Byte52 : 416|8@1+ (1,0) [0|255] ""  IVI
 SG_ IVI_DiagReq_Byte53 : 424|8@1+ (1,0) [0|255] ""  IVI
 SG_ IVI_DiagReq_Byte54 : 432|8@1+ (1,0) [0|255] ""  IVI
 SG_ IVI_DiagReq_Byte55 : 440|8@1+ (1,0) [0|255] ""  IVI
 SG_ IVI_DiagReq_Byte56 : 448|8@1+ (1,0) [0|255] ""  IVI
 SG_ IVI_DiagReq_Byte57 : 456|8@1+ (1,0) [0|255] ""  IVI
 SG_ IVI_DiagReq_Byte58 : 464|8@1+ (1,0) [0|255] ""  IVI
 SG_ IVI_DiagReq_Byte59 : 472|8@1+ (1,0) [0|255] ""  IVI
 SG_ IVI_DiagReq_Byte60 : 480|8@1+ (1,0) [0|255] ""  IVI
 SG_ IVI_DiagReq_Byte61 : 488|8@1+ (1,0) [0|255] ""  IVI
 SG_ IVI_DiagReq_Byte62 : 496|8@1+ (1,0) [0|255] ""  IVI
 SG_ IVI_DiagReq_Byte63 : 504|8@1+ (1,0) [0|255] ""  IVI

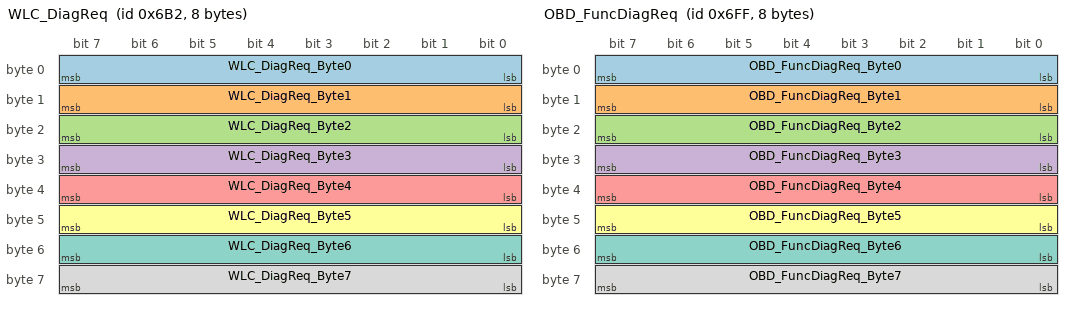
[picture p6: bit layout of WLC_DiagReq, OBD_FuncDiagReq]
BO_ 1714 WLC_DiagReq: 8 ZCU_F
 SG_ WLC_DiagReq_Byte0 : 0|8@1+ (1,0) [0|255] ""  IVI
 SG_ WLC_DiagReq_Byte1 : 8|8@1+ (1,0) [0|255] ""  IVI
 SG_ WLC_DiagReq_Byte2 : 16|8@1+ (1,0) [0|255] ""  IVI
 SG_ WLC_DiagReq_Byte3 : 24|8@1+ (1,0) [0|255] ""  IVI
 SG_ WLC_DiagReq_Byte4 : 32|8@1+ (1,0) [0|255] ""  IVI
 SG_ WLC_DiagReq_Byte5 : 40|8@1+ (1,0) [0|255] ""  IVI
 SG_ WLC_DiagReq_Byte6 : 48|8@1+ (1,0) [0|255] ""  IVI
 SG_ WLC_DiagReq_Byte7 : 56|8@1+ (1,0) [0|255] ""  IVI

BO_ 1791 OBD_FuncDiagReq: 8 ZCU_F
 SG_ OBD_FuncDiagReq_Byte0 : 0|8@1+ (1,0) [0|255] ""  IVI
 SG_ OBD_FuncDiagReq_Byte1 : 8|8@1+ (1,0) [0|255] ""  IVI
 SG_ OBD_FuncDiagReq_Byte2 : 16|8@1+ (1,0) [0|255] ""  IVI
 SG_ OBD_FuncDiagReq_Byte3 : 24|8@1+ (1,0) [0|255] ""  IVI
 SG_ OBD_FuncDiagReq_Byte4 : 32|8@1+ (1,0) [0|255] ""  IVI
 SG_ OBD_FuncDiagReq_Byte5 : 40|8@1+ (1,0) [0|255] ""  IVI
 SG_ OBD_FuncDiagReq_Byte6 : 48|8@1+ (1,0) [0|255] ""  IVI
 SG_ OBD_FuncDiagReq_Byte7 : 56|8@1+ (1,0) [0|255] ""  IVI

CM_ BO_ 1131 "In Vehicle Infotainment Driver seat stored Profile";
CM_ SG_ 1131 CRC_IVI_DrvrSeatStoredProfile "Cyclic Redundancy Check Profile 1c";
CM_ SG_ 1131 AlvCtr_IVI_DrvrSeatStoredProfile "Alive Counter Profile 1c";
CM_ SG_ 1131 SeatAdjmt_DrvFowdBawdStoredPosn "Driver seat forward backward motor position stored in driver user profile";
CM_ SG_ 1131 SeatAdjmt_DrvReclnrStoredPosn "Driver seat recliner motor position stored in driver user profile";
CM_ SG_ 1131 SeatAdjmt_DrvHeiStoredPosn "Driver seat height motor position stored in driver user profile";
CM_ SG_ 1131 SeatAdjmt_DrvTiltStoredPosn "Driver seat tilt motor position stored in driver user profile";
CM_ BO_ 1140 "Driver ID Information";
CM_ SG_ 1140 DriverId_Byte1 "Byte 1 of Driver ID";
CM_ SG_ 1140 DriverId_Byte2 "Byte 2 of Driver ID";
CM_ SG_ 1140 DriverId_Byte3 "Byte 3 of Driver ID";
CM_ SG_ 1140 DriverId_Byte4 "Byte 4 of Driver ID";
CM_ SG_ 1140 DriverId_Byte5 "Byte 5 of Driver ID";
CM_ SG_ 1140 DriverId_Byte6 "Byte 6 of Driver ID";
CM_ SG_ 1140 DriverId_Byte7 "Byte 7 of Driver ID";
CM_ SG_ 1140 DriverId_Byte8 "Byte 8 of Driver ID";
CM_ SG_ 1140 DriverId_Byte9 "Byte 9 of Driver ID";
CM_ SG_ 1140 DriverId_Byte10 "Byte 10 of Driver ID";
CM_ SG_ 1140 DriverId_Byte11 "Byte 11 of Driver ID";
CM_ SG_ 1140 DriverId_Byte12 "Byte 12 of Driver ID";
CM_ SG_ 1140 DriverId_Byte13 "Byte 13 of Driver ID";
CM_ SG_ 1140 DriverId_Byte14 "Byte 14 of Driver ID";
CM_ SG_ 1140 DriverId_Byte15 "Byte 15 of Driver ID";
CM_ SG_ 1140 DriverId_Byte16 "Byte 16 of Driver ID";
CM_ BO_ 1141 "In Vehicle Infotainment HVAC Control";
CM_ SG_ 1141 CRC_IVI_HvacCntrl "Cyclic Redundancy Check Profile 1c";
CM_ SG_ 1141 AlvCtr_IVI_HvacCntrl "Alive Counter Profile 1c";
CM_ SG_ 1141 Ccsf_VentOpModeReq "Vent Motor Operation Mode Request";
CM_ SG_ 1141 Ccs_ReAcUsrIReq "Rear AC (Halo) OnOff request Via IVI";
CM_ SG_ 1141 Demir_HeatgSVMCReq "Request to enable/disable Heating of Digital Exterior Mirror Mounts";
CM_ SG_ 1141 Ccs_ReBlowrLvUsrlReq "Blower Speed increase/decrease Request via IVI ";
CM_ BO_ 1147 "In Vehicle Infotainment HVAC Switch Request";
CM_ SG_ 1147 Ccs_AcMinTUsrBtn "Minimum temperature or maximum AC mode button";
CM_ SG_ 1147 Ccs_AcMaxTUsrBtn "Maximum temperature or max heater mode button";
CM_ SG_ 1147 Ccs_RclOnOffReq "Fresh Air - Recirculation Mode ON/OFF  Request via IVI";
CM_ SG_ 1147 Ccs_FrntAcUsrReq "Front AC ON/OFF request via IVI";
CM_ SG_ 1147 Ccs_ReLeTUsrSetReq "Rear LH temperature request via IVI";
CM_ SG_ 1147 Ccs_ReRiTUsrISetVal "Rear RH temperature request via IVI";
CM_ SG_ 1147 Ccs_SyncTReq "Sync driver passenger HVAC Temperature via IVI";
CM_ SG_ 1147 Ccs_AcEcoModeBtnUsrReq "ECO button press status";
CM_ SG_ 1147 Ccs_FrntAcAutoModUsrReq "AC auto mode ON/OFF request via IVI";
CM_ SG_ 1147 Ccs_IoniserUsrReq "Air Ionizer ON/OFF request";
CM_ SG_ 1147 Ccs_FrgrncAcvnUsrReq "Fragrance system ON/OFF request";
CM_ SG_ 1147 Ccs_DemistDefrstUsrReq "Demist on/off command via IVI";
CM_ SG_ 1147 Ccs_FrntLeTUsrSetVal "Front Left zone temperature request via IVI";
CM_ SG_ 1147 Ccs_FrgrncIntenUsrReq "Fragrance intensity selection request";
CM_ SG_ 1147 Ccs_FrntBlowrLvlUsrReq "Front blower Speed increase/decrease Request via IVI ";
CM_ SG_ 1147 Ccs_AirModeSelnUsrReq "Select Air control mode via IVI";
CM_ SG_ 1147 Ccs_FrntRiTUsrSetVal "Front Right zone temperature request via IVI";
CM_ SG_ 1147 Ccs_ClimPrsetUsrReq "Selected Climate Preset";
CM_ SG_ 1147 Ccs_FrgrncSlenUsrReq "Fragrance selection request";
CM_ SG_ 1147 Ccs_ClimPrflSelnUsrReq "Selected user profile";
CM_ BO_ 1157 "In Vehicle Infotainment User Body Control Request";
CM_ SG_ 1157 CRC_IVI_UsrBodyCntrl_Req "Cyclic Redundancy Check Profile 5";
CM_ SG_ 1157 AlvCtr_IVI_UsrBodyCntrl_Req "Alive Counter Profile 5";
CM_ SG_ 1157 ChrgrPort_ChrgPortLckUnlckUsrReq "Charge port unlock Command through IVI";
CM_ SG_ 1157 Demir_FoldUnfoldSVMCReq "Request to Fold or Unfold Digital Exterior Mirror Mounts";
CM_ SG_ 1157 Demir_FoldUnfoldUsrReq "Request to Fold or Unfold Digital Exterior Mirror through user request";
CM_ SG_ 1157 Demir_HeatgSVMC_Ena "Request to enable/disable Heating of Digital Exterior Mirror Mounts through user request";
CM_ SG_ 1157 Acttg_TailGateUsrAgReq "Tailgate angle adjustment by user via IVI";
CM_ SG_ 1157 Acttg_TailGateUsrReq "Tailgate Open request by user through IVI (Voice command)";
CM_ SG_ 1157 Ssadl_AutoSpdLockVal "Set speed value by user for Auto speed door lock value from IVI";
CM_ SG_ 1157 Ssadl_AutoSpdLockOnOffTypSts "Auto speed lock unlock enable/Disable by user via IVI";
CM_ SG_ 1157 Relamp_ReFogLiReq "Rear fog lamp on off request Via IVI";
CM_ SG_ 1157 Hdlamp_LampReq "Headlamp OnOff request by user via IVI";
CM_ SG_ 1157 Hdlamp_AutoModeCfgReq "HDLM Auto mode feature enable disable  cconfigration from IVI";
CM_ SG_ 1157 Hdlamp_FollowMeCfg "HDLM  Follow me  feature enable disable  configration from IVI";
CM_ SG_ 1157 Wipr_FrntWiprReq "Front wiper mode selection through IVI (OFF/AUTO/LOW/HIGH)";
CM_ SG_ 1157 Wipr_FrntOperParkReq "Right side wiper motor operating park position request
";
CM_ SG_ 1157 Wipr_FrntWiprSrvPosReq "Front wiper service position request by user";
CM_ BO_ 1163 "IVI User Request and various Mode status";
CM_ SG_ 1163 CRC_IVI_UsrChassisCntrl_Req "Cyclic Redundancy Check Profile 5";
CM_ SG_ 1163 AlvCtr_IVI_UsrChassisCntrl_Req "Alive Counter Profile 5";
CM_ SG_ 1163 Hdc_SwtSts "Status of HDC system";
CM_ SG_ 1163 EscTcs_SwtSts "ESC (Electronic stability control)TCS (Traction Control System) switch demand from driver";
CM_ SG_ 1163 IVI_IngrsModeCmd "In-Egress mode Enable/Disable status";
CM_ SG_ 1163 AVH_Swt_Sts "AVH (Automatic Vehicle Hold) switch position depend on driver demand.";
CM_ SG_ 1163 IVI_SuspHeiAdjReq "Suspension Height Adjustment Request";
CM_ SG_ 1163 IVI_SrvModCmd "Service Mode Command";
CM_ BO_ 1173 "In Vehicle Infotainment User Seat Adjustment Comfort Request";
CM_ SG_ 1173 CRC_IVI_UsrSeatAdjComfrt_Req "Cyclic Redundancy Check Profile 1c";
CM_ SG_ 1173 AlvCtr_IVI_UsrSeatAdjComfrt_Req "Alive Counter Profile 1c";
CM_ SG_ 1173 SeatAdjmt_DrvFowdBawdReq "Driver seat forward backward movement request Via IVI";
CM_ SG_ 1173 SeatAdjmt_DrvHeiUpDwnReq "Driver seat height up/down request Via IVI";
CM_ SG_ 1173 SeatAdjmt_DrvLumInOutReq "Driver seat lumbar in/out request Via IVI";
CM_ SG_ 1173 SeatAdjmt_DrvLumUpDwnReq "Driver seat lumbar up/down request Via IVI";
CM_ SG_ 1173 SeatAdjmt_DrvReclUpDownReq "Driver seat reclininer up/down request Via IVI";
CM_ SG_ 1173 SeatCfmt_DrvMassgIntenSelnReq "Driver seat massage intensity selection request via IVI";
CM_ SG_ 1173 SeatCfmt_DrvMassgPatSelnReq "Driver seat massage pattern selection request via IVI";
CM_ SG_ 1173 SeatAdjmt_PassFowdBawdReq "Passenger seat forward backward movement request Via IVI";
CM_ SG_ 1173 SeatAdjmt_PassHeiUpDwnReq "Passenger seat height up/down request Via IVI";
CM_ SG_ 1173 SeatAdjmt_PassLumInOutReq "Passenger seat lumbar in/out request Via IVI";
CM_ SG_ 1173 SeatAdjmt_PassLumUpDwnReq "Passenger seat Lumbar Up Down Request";
CM_ SG_ 1173 SeatAdjmt_PassReclUpDownReq "Passenger seat tilt up/down request Via IVI";
CM_ SG_ 1173 SeatAdjmt_PassTiltUpDwnReq "Passenger seat tilt up/down request Via IVI";
CM_ SG_ 1173 SeatAdjmt_DrvTiltUpDwnReq "Driver seat tilt up/down request Via IVI";
CM_ SG_ 1173 SeatCfmt_PassMassgIntenSelnReq "Passenger seat massage intensity selection request via IVI";
CM_ SG_ 1173 SeatCfmt_PassMassgPatSelnReq "Passenger seat massage pattern selection request via IVI";
CM_ SG_ 1173 SeatCfmt_ReLeVentnSpdReq "Rear LH seat ventilation speed request via IVI";
CM_ SG_ 1173 SeatCfmt_ReRiVentnSpdReq "Rear RH seat ventilation speed request via IVI";
CM_ BO_ 1179 "In Vehicle Infotainment Mode Control";
CM_ SG_ 1179 CRC_IVI_Vehicle_Mode_Ctrl "Cyclic Redundancy Check Profile 5";
CM_ SG_ 1179 AlvCtr_IVI_Vehicle_Mode_Ctrl "Alive Counter Profile 5";
CM_ SG_ 1179 Klss_UsrVehPwrDnReq "Vehicle Shutdown Request triggered by User via HMI";
CM_ SG_ 1179 HMI_KeepAlive "HMI keep Alive button Status";
CM_ SG_ 1179 Lvm_LongParkMode_Req "Long park mode activation by user";
CM_ SG_ 1179 Lvm_StorageMode_Req "Storage mode activation request via diagnostic";
CM_ SG_ 1179 Drvmc_Mode_Req "Drive mode input from IVI (Rx) (VCU)";
CM_ SG_ 1179 Eshift_TagtGear_Req "Target gear request";
CM_ BO_ 1411 "Telematic Box Warnings";
CM_ SG_ 1411 CRC_TBOX_Warning "Cyclic Redundancy Check Profile 5 ";
CM_ SG_ 1411 AlvCtr_TBOX_Warning "Alive Counter Profile 5";
CM_ SG_ 1411 Kle_NfcCcCardVldtn_St_Warn "Warning related to NFC card validation staus";
CM_ BO_ 1412 "Vehicle Control Unit Warnings
";
CM_ SG_ 1412 CRC_VCU_Warning "Cyclic redundancy check Profile 5";
CM_ SG_ 1412 AlvCtr_VCU_Warning "Alive Counter Profile 5
";
CM_ SG_ 1412 Acchg_ChgGunUnlckWarn "Charge gun not unlock warning while active charging session";
CM_ SG_ 1412 Hvsco_HV_SysWarn "High Voltage system status";
CM_ SG_ 1412 Thmgt_CooltOverTWarn "Coolant Temp exceed limit";
CM_ SG_ 1412 Eshift_PsdBrkToEngeGear "Press Brake to engage gear hint";
CM_ SG_ 1412 Awd_WhlDrvModeWarn "Wheel drive mode rejection warning";
CM_ SG_ 1412 Drvmc_DrvModeChngRestrWarn "Drive Mode change restriction warning  ";
CM_ SG_ 1412 Eshift_HvDcnctNoGearChngWarn "No gear change warning due to HV disconnect";
CM_ SG_ 1412 Eshift_GearChng_EPBEngeWarn "No gear change warning due to EPB engage ";
CM_ SG_ 1412 Thmgt_CooltLvlLoWarn "Cooolant liquid level warning";
CM_ SG_ 1412 Eshift_StopVehToMoveFowdDir "Stop vehicle to move Forward direction warning";
CM_ SG_ 1412 Hvsft_HvsftSts "HV safety Status";
CM_ SG_ 1412 VCU_LimphmWarn "limp home mode enable Status";
CM_ SG_ 1412 Eshift_EppFaiWarn "Epp Failure warning";
CM_ SG_ 1412 Thmgt_Therm_FltWarn "Individual fault status of thermal components";
CM_ SG_ 1412 Acchr_ChgAuthWarn "Charging authetication from VCU";
CM_ SG_ 1412 Eshift_ACT_GearWarn "Actual Gear Status";
CM_ SG_ 1412 Eshift_TagtGearVldtnWarn "Target gear validation status";
CM_ SG_ 1412 Hvsft_HvilErrWarn "High Voltage Interlock Loop Circuit Error";
CM_ SG_ 1412 Eshift_StopVehToMoveRvsDir "Stop vehicle to move reverse direction warning";
CM_ SG_ 1412 VCU_HV_Sys_FltLvl1Warn "Warning Fault level 1 from HV Diagnostics feature";
CM_ SG_ 1412 VCU_HV_Sys_FltLvl2Warn "Warning Fault level 2 from HV Diagnostics feature";
CM_ SG_ 1412 VCU_HV_Sys_FltLvl3Warn "Warning Fault level 3 from HV Diagnostics feature";
CM_ SG_ 1412 Cregb_CoastRgnWarn "Coasting regen Warning";
CM_ BO_ 1413 "Front  Zone Control Unit Warnings";
CM_ SG_ 1413 CRC_ZCUF_Warning "Cyclic Redundancy Check Profile 5 ";
CM_ SG_ 1413 AlvCtr_ZCUF_Warning "Alive Counter Profile 5";
CM_ SG_ 1413 CenLock_LockUnlckSts_Warn "Central lock unlcok request by FZCU Warning";
CM_ SG_ 1413 Wipr_FrntRiFaild_Warn "Front right wiper  Fail Warning";
CM_ SG_ 1413 SwtCtl_PassSeatHeatingSwFlt_Warn "Passenger Seat Heating Warning";
CM_ SG_ 1413 SwtCtl_VolSwtFlt_Warn "Volume +/- from User Fault Warning";
CM_ SG_ 1413 Wipr_FrntLeFaild_Warn "Front Left wiper  Fail Warning";
CM_ SG_ 1413 SwttCtl_DrvrStHeatngSwtFlt_Wrn "Driver Seat ventilation Warning ";
CM_ SG_ 1413 Relamp_RevLmpWarn "Relamp_RevLmpWarn: Warning realted to Rear right reverse lamp Warning";
CM_ SG_ 1413 RLML_FogLmp_Warn "RLML Fog Lamp Warning";
CM_ SG_ 1413 SwtCtl_ChdLockSwtFault_Warn "Child Inhibit switch activation Warning";
CM_ SG_ 1413 SwttCtl_ReclrnModOnOffSwtFlt_Wrn "Recirculation Mode Switch Fault Warning";
CM_ SG_ 1413 RLMR_FogLmp_Warn "RLMR Fog Lamp Warning";
CM_ SG_ 1413 Relamp_Chmsl_Warn "Warning related to CHMSL Light  OnOff Status Warning";
CM_ SG_ 1413 SwtCtl_HzrdSwtFlt_Warn "Hazard Light Switch Fault Warning";
CM_ SG_ 1413 Ssadl_DoorAct_Warn "Warning related to Door Actuator status";
CM_ SG_ 1413 Ssadl_DoorAjar_Warn "Warning related to Door ajar status";
CM_ SG_ 1413 Ccs_SrvWarn "Servicing Required Status";
CM_ BO_ 1424 "Airbag Control Module Warning";
CM_ SG_ 1424 CRC_ACM_Warning "Cyclic Redundancy Check Profile 1c  ";
CM_ SG_ 1424 AlvCtr_ACM_Warning "Alive Counter Profile 1c";
CM_ SG_ 1424 SbltWarn_BlinkingRmnReq "Seat Belt reminder Blinking Request";
CM_ SG_ 1424 AirBg_WarnLamp "Airbag Warning Lamp
";
CM_ SG_ 1424 AirBg_PassAirbgDeac_Warn "passenger airbag deactivation confirmation status";
CM_ SG_ 1424 SbltWarn_DrvrIndcrSts "Driver Seat Belt Indicator Status Grey (Unoccupied) Red (Unbuckled) Green (Buckled";
CM_ SG_ 1424 SbltWarn_PassIndcrSts "Passenger Seat Belt Indicator Status Grey (Unoccupied) Red (Unbuckled) Green (Buckled";
CM_ SG_ 1424 SbltWarn_ReCentrIndcrSts "Rear Center Seat Belt Indicator Status Grey (Unoccupied) Red (Unbuckled) Green (Buckled";
CM_ SG_ 1424 SbltWarn_ReRiIndcrSts "Rear Right Seat Belt Indicator Status Grey (Unoccupied) Red (Unbuckled) Green (Buckled";
CM_ SG_ 1424 SbltWarn_ReLeIndcrSts "Rear Left Seat Belt Indicator Status";
CM_ SG_ 1424 SbltWarn_DrvrBklSts "Seat Buckle Status Driver Side";
CM_ SG_ 1424 SbltWarn_PassBklSts "Seat Buckle Status Passenger Side";
CM_ SG_ 1424 SbltWarn_ReCentrBklSts "Seat Buckle Status Rear Center Side";
CM_ SG_ 1424 SbltWarn_ReRiBklSts "Seat Buckle Status Rear Right Side";
CM_ SG_ 1424 SbltWarn_ReLeBklSts "Seat Buckle Status Rear Left Side";
CM_ SG_ 1424 SbltWarn_ChimeRmnReq "Seat Belt reminder Chime Request";
CM_ BO_ 1425 "Door Control Module Left Warnings";
CM_ SG_ 1425 CRC_DCMRL_Warning "Cyclic Redundancy Check Profile 1c  ";
CM_ SG_ 1425 AlvCtr_DCMRL_Warning "Alive Counter Profile 1c";
CM_ SG_ 1425 Pwind_ReLeWndw_Warn "Rear Left Door Power Window Status Warning";
CM_ BO_ 1426 "Door Control Module Right Warnings";
CM_ SG_ 1426 CRC_DCMRR_Warning "Cyclic Redundancy Check Profile 1c  ";
CM_ SG_ 1426 AlvCtr_DCMRR_Warning "Alive Counter Profile 1c";
CM_ SG_ 1426 CenLock_ReRiDoorAjar_Warn "Rear Right  Door Open/Close Status Warning";
CM_ SG_ 1426 Pwind_ReRiWndw_Warn "Rear Right Door Power Window Status  Warning";
CM_ BO_ 1427 "Air Spring Suspension Unit  Warnings";
CM_ SG_ 1427 CRC_ASU_Warning "Cyclic redundancy check Profile 5";
CM_ SG_ 1427 AlvCtr_ASU_Warning "Alive Counter Profile 5
";
CM_ SG_ 1427 AirSuspUnit_Warn "Air Spring Suspension Unit Warnings";
CM_ SG_ 1427 AirSuspUnit_SrvModeNotActvdWarn "Service mode can not be activated as park bake is not applied warning ";
CM_ BO_ 1428 "Door Control Module Passenger Warnings";
CM_ SG_ 1428 CRC_DCMP_Warning "Cyclic Redundancy Check Profile 1c  ";
CM_ SG_ 1428 AlvCtr_DCMP_Warning "Alive Counter Profile 1c";
CM_ SG_ 1428 CenLock_PassDoorAjar_Warn "Passenger door lock_Unlcok actuator Status Warning";
CM_ SG_ 1428 Pwind_PassWndw_Warn "Passenger Power Window Status Warning";
CM_ BO_ 1429 "Battery Management System Warnings";
CM_ SG_ 1429 CRC_BMS_Warning "Cyclic redundancy check Profile 5";
CM_ SG_ 1429 AlvCtr_BMS_Warning "Alive Counter Profile 5";
CM_ SG_ 1429 Bms_CellUDifErrWarn "Max And Min Cell Voltage Difference is Too Larg";
CM_ SG_ 1429 Bms_CooltInletTSnsrFltWarn "Coolant Inlet Temperature Sensor Fault";
CM_ SG_ 1429 Bms_CooltOutlTSnsrFltWarn "Coolant Outlet Temperature Sensor Fault";
CM_ SG_ 1429 Bms_DCFCNegRlyErrWarn "Main DC fast charge  Negative Relay Error ";
CM_ SG_ 1429 Bms_DCFCPosRlyErrWarn "Main DC fast charge  Position Relay Error ";
CM_ SG_ 1429 Bms_CtctrDcnctRsnWarn "Reason For Contactor Off Request";
CM_ SG_ 1429 Bms_ErrLevWarn "Bms Requesting Vcu To Operate At The Limited Operating Strategy (Los)";
CM_ SG_ 1429 Bms_FuseStsErrWarn "Fuse And Pyro Fuse Blowup Status";
CM_ SG_ 1429 Bms_HvilErrWarn "High Voltage Interlock Loop Circuit Error Warning";
CM_ SG_ 1429 Bms_LoBatWarn "Low Battery Warning";
CM_ SG_ 1429 Bms_MainPosRlyErrWarn "Main Position Relay Error ";
CM_ SG_ 1429 Bms_PackHvErrWarn "Pack Voltage is Higher Than The Permittable Value";
CM_ SG_ 1429 Bms_PackInsuErrWarn "Insulation Check Lines Errors";
CM_ SG_ 1429 Bms_PackLvErrWarn "Pack Voltage is Lower Than The Permittable Value";
CM_ SG_ 1429 Bms_PackOvcurErrWarn "When The Over Current is Detected During Charging And Discharging For The Given Period Of Time, Then The Bms_Packovercurr_Err Will Set";
CM_ SG_ 1429 Bms_PackTStsWarn "Pack Temperature Warning";
CM_ SG_ 1429 Bms_PreChRlyErrWarn "Precharge Relay Error";
CM_ SG_ 1429 Bms_CellOverTErrWarn "Over Temperature Of The Cell is Detecte";
CM_ SG_ 1429 Bms_CellUnderTErrWarn "Under Temperature Of The Cell is Detected";
CM_ SG_ 1429 Bms_RvsIDetChgFltWarn "Reverse current detected while charging";
CM_ SG_ 1429 Bms_ScIFltWarn "Short Circuit Current Fault for HV line";
CM_ SG_ 1429 Bms_SocChngFastFltWarn "SOC Jump alarm";
CM_ SG_ 1429 Bms_SrvDueDetnWarn "HV Battery Pack service detection due information";
CM_ SG_ 1429 Bms_ThermRunawayWarn "Thermal Runaway Warning";
CM_ SG_ 1429 Bms_TotNegRlyErrWarn "Main Negative Relay Error ";
CM_ SG_ 1429 Bms_BatBalErrWarn "Bms Requesting Vcu To Operate At The Limited Operating Strategy (Los)";
CM_ SG_ 1429 Bms_BatReplWarn "Separate Signal To indicate The Battery Replacement information(Battery Replacement Mh";
CM_ SG_ 1429 Bms_CellHvErrWarn "Over Voltage Of The Cell is Detected";
CM_ SG_ 1429 Bms_CellLvErrWarn "Pack Voltage is Lower Than The Permittable Value";
CM_ BO_ 1430 "Door Control Module Driver Warnings";
CM_ SG_ 1430 CRC_DCMD_Warning "Cyclic Redundancy Check Profile 1c  ";
CM_ SG_ 1430 AlvCtr_DCMD_Warning "Alive Counter Profile 1c";
CM_ SG_ 1430 Pwind_DrvWndw_Warn "Driver Power Window Status Warning";
CM_ SG_ 1430 CenLock_DrvrDoorAjar_Warn "Driver Door Open/Close Status Warning";
CM_ SG_ 1430 Pwd_DrvrDoor_Warn "Driver  Gullwing Doors Ajar status  Warning";
CM_ BO_ 1432 "Electronic Brake Control Module  Warnings";
CM_ SG_ 1432 CRC_EBCM_Warning "Cyclic Redundancy Check Profile 1c";
CM_ SG_ 1432 AlvCtr_EBCM_Warning "Alive Counter Profile 1c";
CM_ SG_ 1432 Ecpbk_SwtFlt "EPB Switch fault status ";
CM_ SG_ 1432 Ecpbk_InclndVehParkWarn "Vehicle parked on a steep inclination warning ";
CM_ SG_ 1432 Ecpbk_BrkFNotEnWarn "Brake force not enough warning, Demand clamp force not achieved ";
CM_ SG_ 1432 Brb_RgnWarn "Braking regenration warning";
CM_ SG_ 1432 Ecpbk_NotAppldDoorOpenWarn "EPB not release if driver door is open";
CM_ SG_ 1432 Ecpbk_RollrBenchModeWarn "EPB in Roller bench mode ";
CM_ SG_ 1432 Ecpbk_AutoRelsWarn "EPB shall give warning to Driver with Audio";
CM_ SG_ 1432 Ecpbk_RlsdMntnModeWarn "EPB released warning when vehicle is in maitainance mode";
CM_ SG_ 1432 Ecpbk_RlsdTwModeWarn "EPB released warning when vehicle is in tow mode";
CM_ SG_ 1432 Ecpbk_AutoAppldWarn "EPB auto applied warning under auto vehicle hold function";
CM_ SG_ 1432 Drvac_HillStrtAssiFltWarn "Hill Start Assist system Warning";
CM_ SG_ 1432 Ebd_SysWarn "EBD System Warning
";
CM_ SG_ 1432 Drvac_CorneringBrkCtlFltWarn "Cornering Brake Control Brake Fault Warning
 ";
CM_ SG_ 1432 Drvac_HdcWarn "HDC System Warning";
CM_ SG_ 1432 Drvac_FldLvlIndcrBrkFldWarn "Brake Fluid level Indicator Warning
";
CM_ SG_ 1432 Drvac_TcsWarn "TCS system Warning";
CM_ SG_ 1432 Ecpbk_PsdBrkPedlToRelsEpbWarn "EPB shall provide warning message if driver try to release EPB without pressing brake pedal and provide alert to driver press brake pedal to release EPB.
";
CM_ SG_ 1432 Ecpbk_WarnLampSt "Electric park bake warning lamp state";
CM_ SG_ 1432 Ecpbk_ParkBrkFltWarn "Electric park brake fault warning";
CM_ SG_ 1432 Ecpbk_DegradedModeToBeRlsdWarn "EPB to be released in degraded mode warning
";
CM_ SG_ 1432 Ecpbk_DegradedModeRlsdWarn "EPB cant be released without pressing Brake pedal degraded mode warning
";
CM_ SG_ 1432 Abs_FltWarn "Abs Fault Warning";
CM_ BO_ 1434 "On Board Charger Warnings";
CM_ SG_ 1434 CRC_OBC_Warning "Cyclic Redundancy Check Profile 5 ";
CM_ SG_ 1434 AlvCtr_OBC_Warning "Alive Counter Profile 5";
CM_ SG_ 1434 Acchg_ObcErrWarn "Warning related to OBC error ";
CM_ BO_ 1436 "Electric Power Steering-Road Wheel Actuator 1 Warnings

";
CM_ SG_ 1436 CRC_EPS_RWA1_Warning "Cyclic redundancy check Profile 5";
CM_ SG_ 1436 AlvCtr_EPS_RWA1_Warning "Alive Counter Profile 5";
CM_ SG_ 1436 Stbwr_RdndtModeWarn "RWA, SFA are running in redundant mode ";
CM_ BO_ 1437 "Electric Power Steering-Steering Feedback Actuator 1 Warnings";
CM_ SG_ 1437 CRC_EPS_SFA1_Warning "Cyclic redundancy check Profile 5";
CM_ SG_ 1437 AlvCtr_EPS_SFA1_Warning "Alive Counter Profile 5";
CM_ SG_ 1437 Stbwr_HptcWarnSts "Status of Haptic warning on steering wheel ";
CM_ SG_ 1437 Stbwr_SfaCluWarnLamp "Cluster lamp warning States";
CM_ SG_ 1437 Stbwr_SteerAlgnmtWarn "Warning to user to keep hands off the steering wheel during steering alignment";
CM_ BO_ 1438 "Electric Power Steering-Road Wheel Actuator 2 Warnings";
CM_ SG_ 1438 CRC_EPS_RWA2_Warning "Cyclic redundancy check Profile 5";
CM_ SG_ 1438 AlvCtr_EPS_RWA2_Warning "Alive Counter Profile 5";
CM_ SG_ 1438 Stbwr_RdndtModeWarn_R "RWA, SFA are running in redundant mode ";
CM_ BO_ 1439 "Electric Power Steering-Steering Feedback Actuator 2 Warnings";
CM_ SG_ 1439 CRC_EPS_SFA2_Warning "Cyclic redundancy check Profile 5";
CM_ SG_ 1439 AlvCtr_EPS_SFA2_Warning "Alive Counter Profile 5";
CM_ SG_ 1439 Stbwr_HptcWarnSts_R "Status of Haptic warning on steering wheel ";
CM_ SG_ 1439 Stbwr_SfaCluWarnLamp_R "Cluster lamp warning States";
CM_ SG_ 1439 Stbwr_SteerAlgnmtWarn_R "Warning to user to keep hands off the steering wheel during steering alignment";
CM_ BO_ 1445 "Headlamp Left Module Warnings

";
CM_ SG_ 1445 CRC_HDLML_Warning "Cyclic Redundancy Check Profile 5";
CM_ SG_ 1445 AlvCtr_HDLML_Warning "Alive Counter Profile 5";
CM_ SG_ 1445 Hdlamp_LeLoBeamLampWarn "Low Beam LH On Off Status by HDLM
Fusa signal (ASIL B) Warning
";
CM_ SG_ 1445 Hdlamp_LeHiBeamLampWarn "High Beam LH On Off Status by HDLM
Fusa signal (ASIL B) Warning
";
CM_ BO_ 1446 "Headlamp Right Module Warnings

";
CM_ SG_ 1446 CRC_HDLMR_Warning "Cyclic Redundancy Check Profile 5 ";
CM_ SG_ 1446 AlvCtr_HDLMR_Warning "Alive Counter Profile 5";
CM_ SG_ 1446 Hdlamp_RiLoBeamLampWarn "Low Beam RH On Off Status by HDLM Fusa signal (ASIL B) Warning";
CM_ SG_ 1446 Hdlamp_RiHiBeamLamp_Warn "High  Beam RH On Off Status by HDLM Warning";
CM_ BO_ 1447 "Smart Battery Module Warnings";
CM_ SG_ 1447 CRC_Sbm_Warning "Cyclic Redundancy Check Profile 5 ";
CM_ SG_ 1447 AlvCtr_SBM_Warning "Alive Counter Profile 5";
CM_ SG_ 1447 Sbm_CriticalSoCAlert_Warn "LV Battery critical Soc Alert (<10%) (ASIL B) Warning";
CM_ SG_ 1447 Sbm_HealthStWarn "IBS health Warning (ASIL B)";
CM_ SG_ 1447 Sbm_LvBatTSnsrFltSts_Warn "LV Battery Temperature Sensor Fault Warning";
CM_ BO_ 1448 "Climate Control Unit Warning";
CM_ SG_ 1448 CRC_CCU_Warning "Alive Counter Profile 1c";
CM_ SG_ 1448 AlvCtr_CCU_Warning "Cyclic Redundancy Check Profile 1c  ";
CM_ SG_ 1448 Ccsf_IoniserFlt_Warn "Ionizer fail Warning";
CM_ SG_ 1448 Ccsf_FrntLeDuctFlapFlt_Warn "Front LH flap duct fault Warning
";
CM_ SG_ 1448 Ccsf_ReRiTempMixFlapFlt_Warn "Rear Right Temperature mixer flap fault Warning";
CM_ SG_ 1448 Ccsf_ReLeTempMixFlapFlt_Warn "Rear Right Temperature mixer flap fault Warning";
CM_ SG_ 1448 Ccsf_FrntLeTempMixFlapFlt_Warn "Front Left Temperature mixer flap fault  Warning";
CM_ SG_ 1448 Ccsf_ReLeVentDuctFlapFlt_Warn "Rear Vent LH duct fault Warning";
CM_ SG_ 1448 Ccsf_FrntRiDuctFlapFlt_Warn "Front RH flap duct fault Warning
";
CM_ SG_ 1448 Ccsf_ReLeFootDuctFlapFlt_Warn "Rear Foot LH duct fault Warning";
CM_ SG_ 1448 Ccsf_FrntLeVenDirSts "Vent motor Front Center 1 status ";
CM_ SG_ 1448 Ccsf_FrntRiTempMixFlapFltW_Warn "Front Right Temperature mixer flap Warning";
CM_ BO_ 1452 "Front Motor Control Unit Warnings";
CM_ SG_ 1452 CRC_MCU_F_Warning "Cyclic Redundancy Check Profile 5 ";
CM_ SG_ 1452 AlvCtr_MCU_F_Warning "Alive Counter Profile 5";
CM_ SG_ 1452 Eds_FrntDeratWarn "Warning related to Actual derating status of electric machine system 2. ";
CM_ SG_ 1452 Eds_FrntErWarn "Warning related to Actual error status of electric machine system 2. ";
CM_ SG_ 1452 Eds_FrntParkLockErrWarn "Warning related to Error status of the parking lock on electric machine 2.";
CM_ BO_ 1453 "Rear Motor Control Unit Warnings";
CM_ SG_ 1453 CRC_MCU_R_Warning "Cyclic Redundancy Check Profile 5 ";
CM_ SG_ 1453 AlvCtr_MCU_R_Warning "Alive Counter Profile 5";
CM_ SG_ 1453 Eds_ReParkLockErrWarn "Warning related to Error status of the parking lock on electric machine 1.";
CM_ SG_ 1453 Eds_ReErrWarn "Warning related to Actual error status of electric machine system 1.";
CM_ SG_ 1453 Eds_ReDeratWarn "Warning related to Actual derating status of electric machine system 1. ";
CM_ BO_ 1454 "Multi-Function Switches Warning";
CM_ SG_ 1454 CRC_MFS_Warning "Cyclic Redundancy Check Profile 1c  ";
CM_ SG_ 1454 AlvCtr_MFS_Warning "Alive Counter Profile 1c";
CM_ SG_ 1454 Mfsw_DrvModSwt_Warn "drive mode selection Warning";
CM_ SG_ 1454 MFS_ADAS_Swt_Warn "Warning related to ADAS button on the MFS for display on IVI( center console display)/cluster(digital horizon display) of various ADAS options";
CM_ SG_ 1454 MFS_Favorite_Swt_Warn "Warning related to Favourite switch pressed";
CM_ SG_ 1454 MFS_Rim_Swt_Hi_Beam_Warn "Warning related to High Beam switch Pressed";
CM_ SG_ 1454 MFS_Rim_Swt_Wiper_Warn "Warning related to wash/wipe switch";
CM_ BO_ 1457 "DC to DC Converter Warning";
CM_ SG_ 1457 CRC_DCDC_Warning "Cyclic Redundancy Check Profile 5 ";
CM_ SG_ 1457 AlvCtr_DCDC_Warning "Alive Counter Profile 5";
CM_ SG_ 1457 Hvsco_DcdcOperWarn "DCDC warning";
CM_ BO_ 1459 "Driver Power Seat Module Warnings  ";
CM_ SG_ 1459 CRC_PSMD_Warning "Cyclic Redundancy Check Profile 1c";
CM_ SG_ 1459 AlvCtr_PSMD_Warning "Alive Counter Profile 1c";
CM_ SG_ 1459 SeatAdjmt_DrvFrntBackMotWarn "Driver seat forward backward motor Warning ";
CM_ SG_ 1459 SeatCfmt_DrvHeatgBackPadFailWarn "Driver seat heating back pad failure Warning";
CM_ SG_ 1459 SeatCfmt_DrvVentnSqubFanFailWarn "Driver seat ventilation squab fan failure Warning";
CM_ SG_ 1459 SeatAdjmt_DrvHeiUpDwnMotWarn "Driver seat height motor Warning";
CM_ SG_ 1459 SeatAdjmt_DrvTiltUpDwnMotWarn "Driver seat cushion tilt motor  Warning";
CM_ SG_ 1459 SeatCfmt_DrvVentnCshnFanFailWarn "Driver seat ventilation cushion fan failure warning";
CM_ SG_ 1459 SeatAdjmt_DrvAdjmtWarn "Driver seat user profile recall adjustment status notification to IVI Warning";
CM_ SG_ 1459 SeatAdjmt_DrvReclUpDwnMotWarn "Driver seat recliner motor Warning";
CM_ SG_ 1459 SeatCfmt_DrvMassgFailWarn "Driver seat massage fail warning via PSMD";
CM_ BO_ 1460 "Passenger Power Seat Module Warnings";
CM_ SG_ 1460 CRC_PSMP_Warning "Cyclic Redundancy Check Profile 1c";
CM_ SG_ 1460 AlvCtr_PSMP_Warning "Alive Counter Profile 1c  ";
CM_ SG_ 1460 SeatAdjmt_PassTiltUpDwnMotWarn "Passenger seat cushion tilt motor warning ";
CM_ SG_ 1460 SeatAdjmt_PassAdjmtWarn "Passanger seat user profile recall adjustment warning notification to IVI";
CM_ SG_ 1460 SeatCfmt_PassVentnCshnFanFailWrn "Passanger seat ventilation cushion fan failure warning";
CM_ SG_ 1460 SeatAdjmt_PassReclUpDwnMotWarn "Passenger seat lumbar pump up/down position Warning";
CM_ SG_ 1460 SeatAdjmt_PassHeiUpDwnMotWarn "Passanger  seat height motor  Warning";
CM_ SG_ 1460 SeatCfmt_PassVentnSqubFanFailWrn "Passanger seat ventilation squab fan failure warning";
CM_ SG_ 1460 SeatCfmt_PassMassgFailWarn "Passenger seat massage warning status via PSMP";
CM_ SG_ 1460 SeatAdjmt_PassFowdBawdMotWarn "Passenger seat forward backward motor warning ";
CM_ BO_ 1463 "Rear Wheel Steering Module Warnings";
CM_ SG_ 1463 CRC_RWSM_Warning "Cyclic redundancy check Profile 5";
CM_ SG_ 1463 AlvCtr_RWSM_Warning "Alive Counter Profile 5
";
CM_ SG_ 1463 ReWhlSteer_WarnLamp "Rear wheel steering Warning lamp";
CM_ BO_ 1464 "Rear Zone Control Unit Warnings";
CM_ SG_ 1464 CRC_ZCUR_Warning "Cyclic Redundancy Check Profile 5 ";
CM_ SG_ 1464 AlvCtr_ZCUR_Warning "Alive Counter Profile 5";
CM_ SG_ 1464 SeatCfmt_ReLeVentnCshnFanFailWrn "RearLH seat ventilation seat cushion fan failuare status Warning";
CM_ SG_ 1464 SeatCfmt_ReLeVentnSqubFanFailWrn "RearLH seat ventilation squab fan failuare status Warning";
CM_ SG_ 1464 SeatCfmt_ReRiVentnCshnFanFailWrn "RearRH seat ventilation cushion fan failuare status Warning";
CM_ SG_ 1464 SeatCfmt_ReRiVentnSqubFanFailWrn "RearRH seat ventilation squab fan failuare status Warning";
CM_ SG_ 1464 Acttg_TailGate_Warn "Tailgate Warning ";
CM_ SG_ 1464 ChrgrPort_IlmnLampW_Warn "Illumination Lamp lamp on off Warning ";
CM_ BO_ 1472 "Left Tail Lamp Module Warnings";
CM_ SG_ 1472 CRC_TLML_Warning "Cyclic Redundancy Check Profile 5 ";
CM_ SG_ 1472 AlvCtr_TLML_Warning "Alive Counter Profile 5";
CM_ SG_ 1472 Relamp_ReLeTLGTurnIndcr_Warn "Rear Left  Turn light on off s Warning";
CM_ SG_ 1472 Relamp_ReLeTLGPosnLamp_Warn "Rear Left Position light  Warning";
CM_ SG_ 1472 Relamp_LeTLGBrkLamp_Warn "Left brake lamp OnOff  Warning";
CM_ BO_ 1473 "Right Tail Lamp Module Warnings";
CM_ SG_ 1473 CRC_TLMR_Warning "Cyclic Redundancy Check Profile 5 ";
CM_ SG_ 1473 AlvCtr_TLMR_Warning "Alive Counter Profile 5";
CM_ SG_ 1473 Relamp_RiTLGBrkLamp_Warn "Right brake lamp OnOff  Warning";
CM_ SG_ 1473 Relamp_ReRiTLGTurnIndcr_Warn "Rear Right Turn light on off  Warning";
CM_ SG_ 1473 Relamp_ReRiTLGPosnLamp_Warn "Rear Right Position light  Warning";
CM_ BO_ 1474 "Rear Lamp Module Left Warnings";
CM_ SG_ 1474 CRC_RLML_Warning "Cyclic Redundancy Check Profile 5";
CM_ SG_ 1474 AlvCtr_RLML_Warning "Alive Counter Profile 5

";
CM_ SG_ 1474 Relamp_LeBodyBrkLamp_Warn "Left brake lamp OnOff Warning";
CM_ SG_ 1474 Relamp_ReLeBodyTurnIndcr_Warn "Rear Left Position light Warning";
CM_ BO_ 1475 "Rear Lamp Module Right Warning";
CM_ SG_ 1475 CRC_RLMR_Warning "Cyclic Redundancy check Profilr 5";
CM_ SG_ 1475 AlvCtr_RLMR_Warning "Alive Counter Profile 5";
CM_ SG_ 1475 Relamp_ReRiBodyTurnIndcr_Warn "Warning realted to rear right body turn indicator";
CM_ SG_ 1475 Relamp_RiBodyBrkLamp_Warn "Warning related to rear right brake lamp";
CM_ BO_ 1481 "Front Center Signature Light Module Warnings";
CM_ SG_ 1481 CRC_SLMFC_Warning "Cyclic Redundancy Check Profile 5 ";
CM_ SG_ 1481 AlvCtr_SLMFC_Warning "Alive Counter Profile 5";
CM_ SG_ 1481 Hdlamp_FrntCentr_LeSignLamp_Warn "Status of front left Signature Lamp";
CM_ SG_ 1481 Hdlamp_FrntCentr_RiSignLamp_Warn "Status of front right Signature Lamp";
CM_ BO_ 1482 "Front Left Signature Light Module Warnings";
CM_ SG_ 1482 CRC_SLMFL_Warning "Cyclic Redundancy Check Profile 5 ";
CM_ SG_ 1482 AlvCtr_SLMFL_Warning "Alive Counter Profile 5";
CM_ SG_ 1482 Hdlamp_FrntLeBodyTurnIndcr_Warn "Left side turn indicator On OFF status  Warning";
CM_ SG_ 1482 Hdlamp_LeDRLLamp_Warn "Left DRL  lamp  ON ,OFF Status (Fusa ASIL B) Warning";
CM_ SG_ 1482 Hdlamp_LeFrntPosnLamp_Warn "Left Position light status combination of  Front and rear  Warning";
CM_ BO_ 1483 "Front Right Signature Light Module Warnings";
CM_ SG_ 1483 CRC_SLMFR_Warning "Cyclic Redundancy Check Profile 5 ";
CM_ SG_ 1483 AlvCtr_SLMFR_Warning "Alive Counter Profile 5";
CM_ SG_ 1483 Hdlamp_FrntRiBodyTurnIndcr_Warn "Right side turn indicator On OFF status for IVI display and audible warning ";
CM_ SG_ 1483 Hdlamp_RiDRLLamp_Warn "Right DRL lamp ON ,OFF  (Fusa ASIL B)  Warning";
CM_ SG_ 1483 Hdlamp_RiFrntPosnLamp_Warn "Right Position light warning combination of Front and rear";
CM_ BO_ 1484 "Right Center Signature Light Module Warnings";
CM_ SG_ 1484 CRC_SLMRC_Warning "Cyclic Redundancy Check Profile 5 ";
CM_ SG_ 1484 AlvCtr_SLMRC_Warning "Alive Counter Profile 5";
CM_ SG_ 1484 Relamp_Centr_RiSignLampSts "Status of Rear right Signature Lamp";
CM_ SG_ 1484 Relamp_Centr_LeSignLampSts "Status of Rear left Signature Lamp";
CM_ BO_ 1538 "In Vehicle Infotainment Diagnostic Response";
CM_ SG_ 1538 IVI_DiagResp_Byte0 "Diagnostic Signal Data Response Byte0";
CM_ SG_ 1538 IVI_DiagResp_Byte1 "Diagnostic Signal Data Response Byte1";
CM_ SG_ 1538 IVI_DiagResp_Byte2 "Diagnostic Signal Data Response Byte2";
CM_ SG_ 1538 IVI_DiagResp_Byte3 "Diagnostic Signal Data Response Byte3";
CM_ SG_ 1538 IVI_DiagResp_Byte4 "Diagnostic Signal Data Response Byte4";
CM_ SG_ 1538 IVI_DiagResp_Byte5 "Diagnostic Signal Data Response Byte5";
CM_ SG_ 1538 IVI_DiagResp_Byte6 "Diagnostic Signal Data Response Byte6";
CM_ SG_ 1538 IVI_DiagResp_Byte7 "Diagnostic Signal Data Response Byte7";
CM_ SG_ 1538 IVI_DiagResp_Byte8 "Diagnostic Signal Data Response Byte8";
CM_ SG_ 1538 IVI_DiagResp_Byte9 "Diagnostic Signal Data Response Byte9";
CM_ SG_ 1538 IVI_DiagResp_Byte10 "Diagnostic Signal Data Response Byte10";
CM_ SG_ 1538 IVI_DiagResp_Byte11 "Diagnostic Signal Data Response Byte11";
CM_ SG_ 1538 IVI_DiagResp_Byte12 "Diagnostic Signal Data Response Byte12";
CM_ SG_ 1538 IVI_DiagResp_Byte13 "Diagnostic Signal Data Response Byte13";
CM_ SG_ 1538 IVI_DiagResp_Byte14 "Diagnostic Signal Data Response Byte14";
CM_ SG_ 1538 IVI_DiagResp_Byte15 "Diagnostic Signal Data Response Byte15";
CM_ SG_ 1538 IVI_DiagResp_Byte16 "Diagnostic Signal Data Response Byte16";
CM_ SG_ 1538 IVI_DiagResp_Byte17 "Diagnostic Signal Data Response Byte17";
CM_ SG_ 1538 IVI_DiagResp_Byte18 "Diagnostic Signal Data Response Byte18";
CM_ SG_ 1538 IVI_DiagResp_Byte19 "Diagnostic Signal Data Response Byte19";
CM_ SG_ 1538 IVI_DiagResp_Byte20 "Diagnostic Signal Data Response Byte20";
CM_ SG_ 1538 IVI_DiagResp_Byte21 "Diagnostic Signal Data Response Byte21";
CM_ SG_ 1538 IVI_DiagResp_Byte22 "Diagnostic Signal Data Response Byte22";
CM_ SG_ 1538 IVI_DiagResp_Byte23 "Diagnostic Signal Data Response Byte23";
CM_ SG_ 1538 IVI_DiagResp_Byte24 "Diagnostic Signal Data Response Byte24";
CM_ SG_ 1538 IVI_DiagResp_Byte25 "Diagnostic Signal Data Response Byte25";
CM_ SG_ 1538 IVI_DiagResp_Byte26 "Diagnostic Signal Data Response Byte26";
CM_ SG_ 1538 IVI_DiagResp_Byte27 "Diagnostic Signal Data Response Byte27";
CM_ SG_ 1538 IVI_DiagResp_Byte28 "Diagnostic Signal Data Response Byte28";
CM_ SG_ 1538 IVI_DiagResp_Byte29 "Diagnostic Signal Data Response Byte29";
CM_ SG_ 1538 IVI_DiagResp_Byte30 "Diagnostic Signal Data Response Byte30";
CM_ SG_ 1538 IVI_DiagResp_Byte31 "Diagnostic Signal Data Response Byte31";
CM_ SG_ 1538 IVI_DiagResp_Byte32 "Diagnostic Signal Data Response Byte32";
CM_ SG_ 1538 IVI_DiagResp_Byte33 "Diagnostic Signal Data Response Byte33";
CM_ SG_ 1538 IVI_DiagResp_Byte34 "Diagnostic Signal Data Response Byte34";
CM_ SG_ 1538 IVI_DiagResp_Byte35 "Diagnostic Signal Data Response Byte35";
CM_ SG_ 1538 IVI_DiagResp_Byte36 "Diagnostic Signal Data Response Byte36";
CM_ SG_ 1538 IVI_DiagResp_Byte37 "Diagnostic Signal Data Response Byte37";
CM_ SG_ 1538 IVI_DiagResp_Byte38 "Diagnostic Signal Data Response Byte38";
CM_ SG_ 1538 IVI_DiagResp_Byte39 "Diagnostic Signal Data Response Byte39";
CM_ SG_ 1538 IVI_DiagResp_Byte40 "Diagnostic Signal Data Response Byte40";
CM_ SG_ 1538 IVI_DiagResp_Byte41 "Diagnostic Signal Data Response Byte41";
CM_ SG_ 1538 IVI_DiagResp_Byte42 "Diagnostic Signal Data Response Byte42";
CM_ SG_ 1538 IVI_DiagResp_Byte43 "Diagnostic Signal Data Response Byte43";
CM_ SG_ 1538 IVI_DiagResp_Byte44 "Diagnostic Signal Data Response Byte44";
CM_ SG_ 1538 IVI_DiagResp_Byte45 "Diagnostic Signal Data Response Byte45";
CM_ SG_ 1538 IVI_DiagResp_Byte46 "Diagnostic Signal Data Response Byte46";
CM_ SG_ 1538 IVI_DiagResp_Byte47 "Diagnostic Signal Data Response Byte47";
CM_ SG_ 1538 IVI_DiagResp_Byte48 "Diagnostic Signal Data Response Byte48";
CM_ SG_ 1538 IVI_DiagResp_Byte49 "Diagnostic Signal Data Response Byte49";
CM_ SG_ 1538 IVI_DiagResp_Byte50 "Diagnostic Signal Data Response Byte50";
CM_ SG_ 1538 IVI_DiagResp_Byte51 "Diagnostic Signal Data Response Byte51";
CM_ SG_ 1538 IVI_DiagResp_Byte52 "Diagnostic Signal Data Response Byte52";
CM_ SG_ 1538 IVI_DiagResp_Byte53 "Diagnostic Signal Data Response Byte53";
CM_ SG_ 1538 IVI_DiagResp_Byte54 "Diagnostic Signal Data Response Byte54";
CM_ SG_ 1538 IVI_DiagResp_Byte55 "Diagnostic Signal Data Response Byte55";
CM_ SG_ 1538 IVI_DiagResp_Byte56 "Diagnostic Signal Data Response Byte56";
CM_ SG_ 1538 IVI_DiagResp_Byte57 "Diagnostic Signal Data Response Byte57";
CM_ SG_ 1538 IVI_DiagResp_Byte58 "Diagnostic Signal Data Response Byte58";
CM_ SG_ 1538 IVI_DiagResp_Byte59 "Diagnostic Signal Data Response Byte59";
CM_ SG_ 1538 IVI_DiagResp_Byte60 "Diagnostic Signal Data Response Byte60";
CM_ SG_ 1538 IVI_DiagResp_Byte61 "Diagnostic Signal Data Response Byte61";
CM_ SG_ 1538 IVI_DiagResp_Byte62 "Diagnostic Signal Data Response Byte62";
CM_ SG_ 1538 IVI_DiagResp_Byte63 "Diagnostic Signal Data Response Byte63";
CM_ BO_ 1586 "Wireless Charging Module Diagnostic Response";
CM_ SG_ 1586 WLC_DiagResp_Byte0 "Diagnostic Signal Data Response Byte0";
CM_ SG_ 1586 WLC_DiagResp_Byte1 "Diagnostic Signal Data Response Byte1";
CM_ SG_ 1586 WLC_DiagResp_Byte2 "Diagnostic Signal Data Response Byte2";
CM_ SG_ 1586 WLC_DiagResp_Byte3 "Diagnostic Signal Data Response Byte3";
CM_ SG_ 1586 WLC_DiagResp_Byte4 "Diagnostic Signal Data Response Byte4";
CM_ SG_ 1586 WLC_DiagResp_Byte5 "Diagnostic Signal Data Response Byte5";
CM_ SG_ 1586 WLC_DiagResp_Byte6 "Diagnostic Signal Data Response Byte6";
CM_ SG_ 1586 WLC_DiagResp_Byte7 "Diagnostic Signal Data Response Byte7";
CM_ BO_ 1666 "In Vehicle Infotainment Diagnostic Request";
CM_ SG_ 1666 IVI_DiagReq_Byte0 "Diagnostic Signal Data Request Byte0";
CM_ SG_ 1666 IVI_DiagReq_Byte1 "Diagnostic Signal Data Request Byte1";
CM_ SG_ 1666 IVI_DiagReq_Byte2 "Diagnostic Signal Data Request Byte2";
CM_ SG_ 1666 IVI_DiagReq_Byte3 "Diagnostic Signal Data Request Byte3";
CM_ SG_ 1666 IVI_DiagReq_Byte4 "Diagnostic Signal Data Request Byte4";
CM_ SG_ 1666 IVI_DiagReq_Byte5 "Diagnostic Signal Data Request Byte5";
CM_ SG_ 1666 IVI_DiagReq_Byte6 "Diagnostic Signal Data Request Byte6";
CM_ SG_ 1666 IVI_DiagReq_Byte7 "Diagnostic Signal Data Request Byte7";
CM_ SG_ 1666 IVI_DiagReq_Byte8 "Diagnostic Signal Data Request Byte8";
CM_ SG_ 1666 IVI_DiagReq_Byte9 "Diagnostic Signal Data Request Byte9";
CM_ SG_ 1666 IVI_DiagReq_Byte10 "Diagnostic Signal Data Request Byte10";
CM_ SG_ 1666 IVI_DiagReq_Byte11 "Diagnostic Signal Data Request Byte11";
CM_ SG_ 1666 IVI_DiagReq_Byte12 "Diagnostic Signal Data Request Byte12";
CM_ SG_ 1666 IVI_DiagReq_Byte13 "Diagnostic Signal Data Request Byte13";
CM_ SG_ 1666 IVI_DiagReq_Byte14 "Diagnostic Signal Data Request Byte14";
CM_ SG_ 1666 IVI_DiagReq_Byte15 "Diagnostic Signal Data Request Byte15";
CM_ SG_ 1666 IVI_DiagReq_Byte16 "Diagnostic Signal Data Request Byte16";
CM_ SG_ 1666 IVI_DiagReq_Byte17 "Diagnostic Signal Data Request Byte17";
CM_ SG_ 1666 IVI_DiagReq_Byte18 "Diagnostic Signal Data Request Byte18";
CM_ SG_ 1666 IVI_DiagReq_Byte19 "Diagnostic Signal Data Request Byte19";
CM_ SG_ 1666 IVI_DiagReq_Byte20 "Diagnostic Signal Data Request Byte20";
CM_ SG_ 1666 IVI_DiagReq_Byte21 "Diagnostic Signal Data Request Byte21";
CM_ SG_ 1666 IVI_DiagReq_Byte22 "Diagnostic Signal Data Request Byte22";
CM_ SG_ 1666 IVI_DiagReq_Byte23 "Diagnostic Signal Data Request Byte23";
CM_ SG_ 1666 IVI_DiagReq_Byte24 "Diagnostic Signal Data Request Byte24";
CM_ SG_ 1666 IVI_DiagReq_Byte25 "Diagnostic Signal Data Request Byte25";
CM_ SG_ 1666 IVI_DiagReq_Byte26 "Diagnostic Signal Data Request Byte26";
CM_ SG_ 1666 IVI_DiagReq_Byte27 "Diagnostic Signal Data Request Byte27";
CM_ SG_ 1666 IVI_DiagReq_Byte28 "Diagnostic Signal Data Request Byte28";
CM_ SG_ 1666 IVI_DiagReq_Byte29 "Diagnostic Signal Data Request Byte29";
CM_ SG_ 1666 IVI_DiagReq_Byte30 "Diagnostic Signal Data Request Byte30";
CM_ SG_ 1666 IVI_DiagReq_Byte31 "Diagnostic Signal Data Request Byte31";
CM_ SG_ 1666 IVI_DiagReq_Byte32 "Diagnostic Signal Data Request Byte32";
CM_ SG_ 1666 IVI_DiagReq_Byte33 "Diagnostic Signal Data Request Byte33";
CM_ SG_ 1666 IVI_DiagReq_Byte34 "Diagnostic Signal Data Request Byte34";
CM_ SG_ 1666 IVI_DiagReq_Byte35 "Diagnostic Signal Data Request Byte35";
CM_ SG_ 1666 IVI_DiagReq_Byte36 "Diagnostic Signal Data Request Byte36";
CM_ SG_ 1666 IVI_DiagReq_Byte37 "Diagnostic Signal Data Request Byte37";
CM_ SG_ 1666 IVI_DiagReq_Byte38 "Diagnostic Signal Data Request Byte38";
CM_ SG_ 1666 IVI_DiagReq_Byte39 "Diagnostic Signal Data Request Byte39";
CM_ SG_ 1666 IVI_DiagReq_Byte40 "Diagnostic Signal Data Request Byte40";
CM_ SG_ 1666 IVI_DiagReq_Byte41 "Diagnostic Signal Data Request Byte41";
CM_ SG_ 1666 IVI_DiagReq_Byte42 "Diagnostic Signal Data Request Byte42";
CM_ SG_ 1666 IVI_DiagReq_Byte43 "Diagnostic Signal Data Request Byte43";
CM_ SG_ 1666 IVI_DiagReq_Byte44 "Diagnostic Signal Data Request Byte44";
CM_ SG_ 1666 IVI_DiagReq_Byte45 "Diagnostic Signal Data Request Byte45";
CM_ SG_ 1666 IVI_DiagReq_Byte46 "Diagnostic Signal Data Request Byte46";
CM_ SG_ 1666 IVI_DiagReq_Byte47 "Diagnostic Signal Data Request Byte47";
CM_ SG_ 1666 IVI_DiagReq_Byte48 "Diagnostic Signal Data Request Byte48";
CM_ SG_ 1666 IVI_DiagReq_Byte49 "Diagnostic Signal Data Request Byte49";
CM_ SG_ 1666 IVI_DiagReq_Byte50 "Diagnostic Signal Data Request Byte50";
CM_ SG_ 1666 IVI_DiagReq_Byte51 "Diagnostic Signal Data Request Byte51";
CM_ SG_ 1666 IVI_DiagReq_Byte52 "Diagnostic Signal Data Request Byte52";
CM_ SG_ 1666 IVI_DiagReq_Byte53 "Diagnostic Signal Data Request Byte53";
CM_ SG_ 1666 IVI_DiagReq_Byte54 "Diagnostic Signal Data Request Byte54";
CM_ SG_ 1666 IVI_DiagReq_Byte55 "Diagnostic Signal Data Request Byte55";
CM_ SG_ 1666 IVI_DiagReq_Byte56 "Diagnostic Signal Data Request Byte56";
CM_ SG_ 1666 IVI_DiagReq_Byte57 "Diagnostic Signal Data Request Byte57";
CM_ SG_ 1666 IVI_DiagReq_Byte58 "Diagnostic Signal Data Request Byte58";
CM_ SG_ 1666 IVI_DiagReq_Byte59 "Diagnostic Signal Data Request Byte59";
CM_ SG_ 1666 IVI_DiagReq_Byte60 "Diagnostic Signal Data Request Byte60";
CM_ SG_ 1666 IVI_DiagReq_Byte61 "Diagnostic Signal Data Request Byte61";
CM_ SG_ 1666 IVI_DiagReq_Byte62 "Diagnostic Signal Data Request Byte62";
CM_ SG_ 1666 IVI_DiagReq_Byte63 "Diagnostic Signal Data Request Byte63";
CM_ BO_ 1714 "Wireless Charging Module Diagnostic Request";
CM_ SG_ 1714 WLC_DiagReq_Byte0 "Diagnostic Signal Data Request Byte0";
CM_ SG_ 1714 WLC_DiagReq_Byte1 "Diagnostic Signal Data Request Byte1";
CM_ SG_ 1714 WLC_DiagReq_Byte2 "Diagnostic Signal Data Request Byte2";
CM_ SG_ 1714 WLC_DiagReq_Byte3 "Diagnostic Signal Data Request Byte3";
CM_ SG_ 1714 WLC_DiagReq_Byte4 "Diagnostic Signal Data Request Byte4";
CM_ SG_ 1714 WLC_DiagReq_Byte5 "Diagnostic Signal Data Request Byte5";
CM_ SG_ 1714 WLC_DiagReq_Byte6 "Diagnostic Signal Data Request Byte6";
CM_ SG_ 1714 WLC_DiagReq_Byte7 "Diagnostic Signal Data Request Byte7";
CM_ BO_ 1791 "Diagnostic Functional Request
";
CM_ SG_ 1791 OBD_FuncDiagReq_Byte0 "Diagnostic Signal Data Request Byte0
";
CM_ SG_ 1791 OBD_FuncDiagReq_Byte1 "Diagnostic Signal Data Request Byte1
";
CM_ SG_ 1791 OBD_FuncDiagReq_Byte2 "Diagnostic Signal Data Request Byte2
";
CM_ SG_ 1791 OBD_FuncDiagReq_Byte3 "Diagnostic Signal Data Request Byte3
";
CM_ SG_ 1791 OBD_FuncDiagReq_Byte4 "Diagnostic Signal Data Request Byte4
";
CM_ SG_ 1791 OBD_FuncDiagReq_Byte5 "Diagnostic Signal Data Request Byte5
";
CM_ SG_ 1791 OBD_FuncDiagReq_Byte6 "Diagnostic Signal Data Request Byte6
";
CM_ SG_ 1791 OBD_FuncDiagReq_Byte7 "Diagnostic Signal Data Request Byte7
";
BA_DEF_ BO_  "DiagConnection" INT 0 0;
BA_DEF_ BO_  "DiagFdOnly" ENUM  "Yes","No";
BA_DEF_ BO_  "DataID" HEX 0 0;
BA_DEF_ BO_  "E2EProfile" ENUM  "PROFILE_1C","PROFILE_5","Not Applicable","NOT_E2E_MSG";
BA_DEF_ SG_  "GenSigSendType" ENUM  "Cyclic","OnChange","Cyclic On Change","NoSigSendType";
BA_DEF_ BO_  "VFrameFormat" ENUM  "StandardCAN","ExtendedCAN","reserved","reserved","reserved","reserved","reserved","reserved","reserved","reserved","reserved","reserved","reserved","reserved","StandardCAN_FD","ExtendedCAN_FD";
BA_DEF_ BO_  "NmAsrMessageCount" INT 1 256;
BA_DEF_ BO_  "GenMsgSendType" ENUM  "Cyclic","OnChange","Cyclic On Change","NoMsgSendType";
BA_DEF_ SG_  "InvalidValue" STRING ;
BA_DEF_ BO_  "GenMsgCycleTime" INT 0 65535;
BA_DEF_ BO_  "GenMsgCycleTimeFast" INT 0 65535;
BA_DEF_ SG_  "GenSigTimeoutTime" INT 0 65535;
BA_DEF_ SG_  "GenSigStartValue" INT 0 0;
BA_DEF_ BO_  "GenMsgILSupport" ENUM  "No","Yes";
BA_DEF_ BO_  "GenMsgNrOfRepetition" INT 0 0;
BA_DEF_ BO_  "DiagState" ENUM  "No","Yes";
BA_DEF_ BO_  "DiagResponse" ENUM  "No","Yes";
BA_DEF_ BO_  "DiagRequest" ENUM  "No","Yes";
BA_DEF_DEF_  "DiagConnection" 0;
BA_DEF_DEF_  "DiagFdOnly" "Yes";
BA_DEF_DEF_  "DataID" 0;
BA_DEF_DEF_  "E2EProfile" "NOT_E2E_MSG";
BA_DEF_DEF_  "GenSigSendType" "Cyclic";
BA_DEF_DEF_  "VFrameFormat" "StandardCAN";
BA_DEF_DEF_  "NmAsrMessageCount" 128;
BA_DEF_DEF_  "GenMsgSendType" "Cyclic";
BA_DEF_DEF_  "InvalidValue" "";
BA_DEF_DEF_  "GenMsgCycleTime" 0;
BA_DEF_DEF_  "GenMsgCycleTimeFast" 0;
BA_DEF_DEF_  "GenSigTimeoutTime" 0;
BA_DEF_DEF_  "GenSigStartValue" 0;
BA_DEF_DEF_  "GenMsgILSupport" "Yes";
BA_DEF_DEF_  "GenMsgNrOfRepetition" 0;
BA_DEF_DEF_  "DiagState" "No";
BA_DEF_DEF_  "DiagResponse" "No";
BA_DEF_DEF_  "DiagRequest" "No";
BA_ "GenMsgSendType" BO_ 1131 2;
BA_ "GenMsgNrOfRepetition" BO_ 1131 3;
BA_ "GenMsgCycleTimeFast" BO_ 1131 50;
BA_ "GenMsgCycleTime" BO_ 1131 1000;
BA_ "E2EProfile" BO_ 1131 0;
BA_ "DataID" BO_ 1131 1625;
BA_ "VFrameFormat" BO_ 1131 14;
BA_ "GenMsgSendType" BO_ 1140 2;
BA_ "GenMsgNrOfRepetition" BO_ 1140 3;
BA_ "GenMsgCycleTimeFast" BO_ 1140 50;
BA_ "GenMsgCycleTime" BO_ 1140 1000;
BA_ "VFrameFormat" BO_ 1140 14;
BA_ "GenMsgSendType" BO_ 1141 2;
BA_ "GenMsgNrOfRepetition" BO_ 1141 3;
BA_ "GenMsgCycleTimeFast" BO_ 1141 50;
BA_ "GenMsgCycleTime" BO_ 1141 1000;
BA_ "E2EProfile" BO_ 1141 0;
BA_ "DataID" BO_ 1141 3919;
BA_ "VFrameFormat" BO_ 1141 14;
BA_ "GenMsgSendType" BO_ 1147 2;
BA_ "GenMsgNrOfRepetition" BO_ 1147 3;
BA_ "GenMsgCycleTimeFast" BO_ 1147 50;
BA_ "GenMsgCycleTime" BO_ 1147 1000;
BA_ "VFrameFormat" BO_ 1147 14;
BA_ "GenMsgSendType" BO_ 1157 2;
BA_ "GenMsgNrOfRepetition" BO_ 1157 3;
BA_ "GenMsgCycleTimeFast" BO_ 1157 50;
BA_ "GenMsgCycleTime" BO_ 1157 1000;
BA_ "E2EProfile" BO_ 1157 1;
BA_ "DataID" BO_ 1157 503;
BA_ "VFrameFormat" BO_ 1157 14;
BA_ "GenMsgSendType" BO_ 1163 2;
BA_ "GenMsgNrOfRepetition" BO_ 1163 3;
BA_ "GenMsgCycleTimeFast" BO_ 1163 50;
BA_ "GenMsgCycleTime" BO_ 1163 1000;
BA_ "E2EProfile" BO_ 1163 1;
BA_ "DataID" BO_ 1163 3017;
BA_ "VFrameFormat" BO_ 1163 14;
BA_ "GenMsgSendType" BO_ 1173 2;
BA_ "GenMsgNrOfRepetition" BO_ 1173 3;
BA_ "GenMsgCycleTimeFast" BO_ 1173 50;
BA_ "GenMsgCycleTime" BO_ 1173 1000;
BA_ "E2EProfile" BO_ 1173 0;
BA_ "DataID" BO_ 1173 940;
BA_ "VFrameFormat" BO_ 1173 14;
BA_ "GenMsgSendType" BO_ 1179 2;
BA_ "GenMsgNrOfRepetition" BO_ 1179 3;
BA_ "GenMsgCycleTimeFast" BO_ 1179 50;
BA_ "GenMsgCycleTime" BO_ 1179 1000;
BA_ "E2EProfile" BO_ 1179 1;
BA_ "DataID" BO_ 1179 1733;
BA_ "VFrameFormat" BO_ 1179 14;
BA_ "GenMsgSendType" BO_ 1411 2;
BA_ "GenMsgNrOfRepetition" BO_ 1411 2;
BA_ "GenMsgCycleTimeFast" BO_ 1411 50;
BA_ "GenMsgCycleTime" BO_ 1411 1000;
BA_ "E2EProfile" BO_ 1411 1;
BA_ "DataID" BO_ 1411 1184;
BA_ "VFrameFormat" BO_ 1411 14;
BA_ "GenMsgSendType" BO_ 1412 2;
BA_ "GenMsgNrOfRepetition" BO_ 1412 2;
BA_ "GenMsgCycleTimeFast" BO_ 1412 50;
BA_ "GenMsgCycleTime" BO_ 1412 1000;
BA_ "E2EProfile" BO_ 1412 1;
BA_ "DataID" BO_ 1412 2754;
BA_ "VFrameFormat" BO_ 1412 14;
BA_ "GenMsgSendType" BO_ 1413 2;
BA_ "GenMsgNrOfRepetition" BO_ 1413 2;
BA_ "GenMsgCycleTimeFast" BO_ 1413 50;
BA_ "GenMsgCycleTime" BO_ 1413 1000;
BA_ "E2EProfile" BO_ 1413 1;
BA_ "DataID" BO_ 1413 2640;
BA_ "VFrameFormat" BO_ 1413 14;
BA_ "GenMsgSendType" BO_ 1424 2;
BA_ "GenMsgNrOfRepetition" BO_ 1424 2;
BA_ "GenMsgCycleTimeFast" BO_ 1424 50;
BA_ "GenMsgCycleTime" BO_ 1424 1000;
BA_ "E2EProfile" BO_ 1424 0;
BA_ "DataID" BO_ 1424 395;
BA_ "VFrameFormat" BO_ 1424 14;
BA_ "GenMsgSendType" BO_ 1425 2;
BA_ "GenMsgNrOfRepetition" BO_ 1425 2;
BA_ "GenMsgCycleTimeFast" BO_ 1425 50;
BA_ "GenMsgCycleTime" BO_ 1425 1000;
BA_ "E2EProfile" BO_ 1425 0;
BA_ "DataID" BO_ 1425 2197;
BA_ "VFrameFormat" BO_ 1425 14;
BA_ "GenMsgSendType" BO_ 1426 2;
BA_ "GenMsgNrOfRepetition" BO_ 1426 2;
BA_ "GenMsgCycleTimeFast" BO_ 1426 50;
BA_ "GenMsgCycleTime" BO_ 1426 1000;
BA_ "E2EProfile" BO_ 1426 0;
BA_ "DataID" BO_ 1426 406;
BA_ "VFrameFormat" BO_ 1426 14;
BA_ "GenMsgSendType" BO_ 1427 2;
BA_ "GenMsgNrOfRepetition" BO_ 1427 2;
BA_ "GenMsgCycleTimeFast" BO_ 1427 50;
BA_ "GenMsgCycleTime" BO_ 1427 1000;
BA_ "E2EProfile" BO_ 1427 1;
BA_ "DataID" BO_ 1427 2372;
BA_ "VFrameFormat" BO_ 1427 14;
BA_ "GenMsgSendType" BO_ 1428 2;
BA_ "GenMsgNrOfRepetition" BO_ 1428 2;
BA_ "GenMsgCycleTimeFast" BO_ 1428 50;
BA_ "GenMsgCycleTime" BO_ 1428 1000;
BA_ "E2EProfile" BO_ 1428 0;
BA_ "DataID" BO_ 1428 3135;
BA_ "VFrameFormat" BO_ 1428 14;
BA_ "GenMsgSendType" BO_ 1429 2;
BA_ "GenMsgNrOfRepetition" BO_ 1429 2;
BA_ "GenMsgCycleTimeFast" BO_ 1429 50;
BA_ "GenMsgCycleTime" BO_ 1429 1000;
BA_ "E2EProfile" BO_ 1429 1;
BA_ "DataID" BO_ 1429 2427;
BA_ "VFrameFormat" BO_ 1429 14;
BA_ "GenMsgSendType" BO_ 1430 2;
BA_ "GenMsgNrOfRepetition" BO_ 1430 2;
BA_ "GenMsgCycleTimeFast" BO_ 1430 50;
BA_ "GenMsgCycleTime" BO_ 1430 1000;
BA_ "E2EProfile" BO_ 1430 0;
BA_ "DataID" BO_ 1430 1902;
BA_ "VFrameFormat" BO_ 1430 14;
BA_ "GenMsgSendType" BO_ 1432 2;
BA_ "GenMsgNrOfRepetition" BO_ 1432 2;
BA_ "GenMsgCycleTimeFast" BO_ 1432 50;
BA_ "GenMsgCycleTime" BO_ 1432 1000;
BA_ "E2EProfile" BO_ 1432 1;
BA_ "DataID" BO_ 1432 1732;
BA_ "VFrameFormat" BO_ 1432 14;
BA_ "GenMsgSendType" BO_ 1434 2;
BA_ "GenMsgNrOfRepetition" BO_ 1434 2;
BA_ "GenMsgCycleTimeFast" BO_ 1434 50;
BA_ "GenMsgCycleTime" BO_ 1434 1000;
BA_ "E2EProfile" BO_ 1434 1;
BA_ "DataID" BO_ 1434 948;
BA_ "VFrameFormat" BO_ 1434 14;
BA_ "GenMsgSendType" BO_ 1436 2;
BA_ "GenMsgNrOfRepetition" BO_ 1436 2;
BA_ "GenMsgCycleTimeFast" BO_ 1436 50;
BA_ "GenMsgCycleTime" BO_ 1436 1000;
BA_ "E2EProfile" BO_ 1436 1;
BA_ "DataID" BO_ 1436 3456;
BA_ "VFrameFormat" BO_ 1436 14;
BA_ "GenMsgSendType" BO_ 1437 2;
BA_ "GenMsgNrOfRepetition" BO_ 1437 2;
BA_ "GenMsgCycleTimeFast" BO_ 1437 50;
BA_ "GenMsgCycleTime" BO_ 1437 1000;
BA_ "E2EProfile" BO_ 1437 1;
BA_ "DataID" BO_ 1437 385;
BA_ "VFrameFormat" BO_ 1437 14;
BA_ "GenMsgSendType" BO_ 1438 2;
BA_ "GenMsgNrOfRepetition" BO_ 1438 2;
BA_ "GenMsgCycleTimeFast" BO_ 1438 50;
BA_ "GenMsgCycleTime" BO_ 1438 1000;
BA_ "E2EProfile" BO_ 1438 1;
BA_ "DataID" BO_ 1438 2749;
BA_ "VFrameFormat" BO_ 1438 14;
BA_ "GenMsgSendType" BO_ 1439 2;
BA_ "GenMsgNrOfRepetition" BO_ 1439 2;
BA_ "GenMsgCycleTimeFast" BO_ 1439 50;
BA_ "GenMsgCycleTime" BO_ 1439 1000;
BA_ "E2EProfile" BO_ 1439 1;
BA_ "DataID" BO_ 1439 1349;
BA_ "VFrameFormat" BO_ 1439 14;
BA_ "GenMsgSendType" BO_ 1445 2;
BA_ "GenMsgNrOfRepetition" BO_ 1445 2;
BA_ "GenMsgCycleTimeFast" BO_ 1445 50;
BA_ "GenMsgCycleTime" BO_ 1445 1000;
BA_ "E2EProfile" BO_ 1445 1;
BA_ "DataID" BO_ 1445 2594;
BA_ "VFrameFormat" BO_ 1445 14;
BA_ "GenMsgSendType" BO_ 1446 2;
BA_ "GenMsgNrOfRepetition" BO_ 1446 2;
BA_ "GenMsgCycleTimeFast" BO_ 1446 50;
BA_ "GenMsgCycleTime" BO_ 1446 1000;
BA_ "E2EProfile" BO_ 1446 1;
BA_ "DataID" BO_ 1446 817;
BA_ "VFrameFormat" BO_ 1446 14;
BA_ "GenMsgSendType" BO_ 1447 2;
BA_ "GenMsgNrOfRepetition" BO_ 1447 2;
BA_ "GenMsgCycleTimeFast" BO_ 1447 50;
BA_ "GenMsgCycleTime" BO_ 1447 1000;
BA_ "E2EProfile" BO_ 1447 1;
BA_ "DataID" BO_ 1447 3215;
BA_ "VFrameFormat" BO_ 1447 14;
BA_ "GenMsgSendType" BO_ 1448 2;
BA_ "GenMsgNrOfRepetition" BO_ 1448 2;
BA_ "GenMsgCycleTimeFast" BO_ 1448 50;
BA_ "GenMsgCycleTime" BO_ 1448 1000;
BA_ "E2EProfile" BO_ 1448 0;
BA_ "DataID" BO_ 1448 1227;
BA_ "VFrameFormat" BO_ 1448 14;
BA_ "GenMsgSendType" BO_ 1452 2;
BA_ "GenMsgNrOfRepetition" BO_ 1452 2;
BA_ "GenMsgCycleTimeFast" BO_ 1452 50;
BA_ "GenMsgCycleTime" BO_ 1452 1000;
BA_ "E2EProfile" BO_ 1452 1;
BA_ "DataID" BO_ 1452 1591;
BA_ "VFrameFormat" BO_ 1452 14;
BA_ "GenMsgSendType" BO_ 1453 2;
BA_ "GenMsgNrOfRepetition" BO_ 1453 2;
BA_ "GenMsgCycleTimeFast" BO_ 1453 50;
BA_ "GenMsgCycleTime" BO_ 1453 1000;
BA_ "E2EProfile" BO_ 1453 1;
BA_ "DataID" BO_ 1453 3338;
BA_ "VFrameFormat" BO_ 1453 14;
BA_ "GenMsgSendType" BO_ 1454 2;
BA_ "GenMsgNrOfRepetition" BO_ 1454 2;
BA_ "GenMsgCycleTimeFast" BO_ 1454 50;
BA_ "GenMsgCycleTime" BO_ 1454 1000;
BA_ "E2EProfile" BO_ 1454 0;
BA_ "DataID" BO_ 1454 2112;
BA_ "VFrameFormat" BO_ 1454 14;
BA_ "GenMsgSendType" BO_ 1457 2;
BA_ "GenMsgNrOfRepetition" BO_ 1457 2;
BA_ "GenMsgCycleTimeFast" BO_ 1457 50;
BA_ "GenMsgCycleTime" BO_ 1457 1000;
BA_ "E2EProfile" BO_ 1457 1;
BA_ "DataID" BO_ 1457 1707;
BA_ "VFrameFormat" BO_ 1457 14;
BA_ "GenMsgSendType" BO_ 1459 2;
BA_ "GenMsgNrOfRepetition" BO_ 1459 2;
BA_ "GenMsgCycleTimeFast" BO_ 1459 50;
BA_ "GenMsgCycleTime" BO_ 1459 1000;
BA_ "E2EProfile" BO_ 1459 0;
BA_ "DataID" BO_ 1459 2903;
BA_ "VFrameFormat" BO_ 1459 14;
BA_ "GenMsgSendType" BO_ 1460 2;
BA_ "GenMsgNrOfRepetition" BO_ 1460 2;
BA_ "GenMsgCycleTimeFast" BO_ 1460 50;
BA_ "GenMsgCycleTime" BO_ 1460 1000;
BA_ "E2EProfile" BO_ 1460 0;
BA_ "DataID" BO_ 1460 2106;
BA_ "VFrameFormat" BO_ 1460 14;
BA_ "GenMsgSendType" BO_ 1463 2;
BA_ "GenMsgNrOfRepetition" BO_ 1463 2;
BA_ "GenMsgCycleTimeFast" BO_ 1463 50;
BA_ "GenMsgCycleTime" BO_ 1463 1000;
BA_ "E2EProfile" BO_ 1463 1;
BA_ "DataID" BO_ 1463 3314;
BA_ "VFrameFormat" BO_ 1463 14;
BA_ "GenMsgSendType" BO_ 1464 2;
BA_ "GenMsgNrOfRepetition" BO_ 1464 2;
BA_ "GenMsgCycleTimeFast" BO_ 1464 50;
BA_ "GenMsgCycleTime" BO_ 1464 1000;
BA_ "E2EProfile" BO_ 1464 1;
BA_ "DataID" BO_ 1464 3670;
BA_ "VFrameFormat" BO_ 1464 14;
BA_ "GenMsgSendType" BO_ 1472 2;
BA_ "GenMsgNrOfRepetition" BO_ 1472 2;
BA_ "GenMsgCycleTimeFast" BO_ 1472 50;
BA_ "GenMsgCycleTime" BO_ 1472 1000;
BA_ "E2EProfile" BO_ 1472 1;
BA_ "DataID" BO_ 1472 1865;
BA_ "VFrameFormat" BO_ 1472 14;
BA_ "GenMsgSendType" BO_ 1473 2;
BA_ "GenMsgNrOfRepetition" BO_ 1473 2;
BA_ "GenMsgCycleTimeFast" BO_ 1473 50;
BA_ "GenMsgCycleTime" BO_ 1473 1000;
BA_ "E2EProfile" BO_ 1473 1;
BA_ "DataID" BO_ 1473 721;
BA_ "VFrameFormat" BO_ 1473 14;
BA_ "GenMsgSendType" BO_ 1474 2;
BA_ "GenMsgNrOfRepetition" BO_ 1474 2;
BA_ "GenMsgCycleTimeFast" BO_ 1474 50;
BA_ "GenMsgCycleTime" BO_ 1474 1000;
BA_ "E2EProfile" BO_ 1474 1;
BA_ "DataID" BO_ 1474 3533;
BA_ "VFrameFormat" BO_ 1474 14;
BA_ "GenMsgSendType" BO_ 1475 2;
BA_ "GenMsgNrOfRepetition" BO_ 1475 2;
BA_ "GenMsgCycleTimeFast" BO_ 1475 50;
BA_ "GenMsgCycleTime" BO_ 1475 1000;
BA_ "E2EProfile" BO_ 1475 1;
BA_ "DataID" BO_ 1475 3936;
BA_ "VFrameFormat" BO_ 1475 14;
BA_ "GenMsgSendType" BO_ 1481 2;
BA_ "GenMsgNrOfRepetition" BO_ 1481 2;
BA_ "GenMsgCycleTimeFast" BO_ 1481 50;
BA_ "GenMsgCycleTime" BO_ 1481 1000;
BA_ "E2EProfile" BO_ 1481 1;
BA_ "DataID" BO_ 1481 1743;
BA_ "VFrameFormat" BO_ 1481 14;
BA_ "GenMsgSendType" BO_ 1482 2;
BA_ "GenMsgNrOfRepetition" BO_ 1482 2;
BA_ "GenMsgCycleTimeFast" BO_ 1482 50;
BA_ "GenMsgCycleTime" BO_ 1482 1000;
BA_ "E2EProfile" BO_ 1482 1;
BA_ "DataID" BO_ 1482 3838;
BA_ "VFrameFormat" BO_ 1482 14;
BA_ "GenMsgSendType" BO_ 1483 2;
BA_ "GenMsgNrOfRepetition" BO_ 1483 2;
BA_ "GenMsgCycleTimeFast" BO_ 1483 50;
BA_ "GenMsgCycleTime" BO_ 1483 1000;
BA_ "E2EProfile" BO_ 1483 1;
BA_ "DataID" BO_ 1483 2653;
BA_ "VFrameFormat" BO_ 1483 14;
BA_ "GenMsgSendType" BO_ 1484 2;
BA_ "GenMsgNrOfRepetition" BO_ 1484 2;
BA_ "GenMsgCycleTimeFast" BO_ 1484 50;
BA_ "GenMsgCycleTime" BO_ 1484 1000;
BA_ "E2EProfile" BO_ 1484 1;
BA_ "DataID" BO_ 1484 931;
BA_ "VFrameFormat" BO_ 1484 14;
BA_ "GenMsgILSupport" BO_ 1538 0;
BA_ "DiagConnection" BO_ 1538 11111;
BA_ "GenMsgSendType" BO_ 1538 3;
BA_ "DiagResponse" BO_ 1538 1;
BA_ "VFrameFormat" BO_ 1538 14;
BA_ "GenMsgSendType" BO_ 1586 3;
BA_ "DiagResponse" BO_ 1586 1;
BA_ "DiagConnection" BO_ 1586 11112;
BA_ "GenMsgILSupport" BO_ 1586 0;
BA_ "VFrameFormat" BO_ 1586 14;
BA_ "GenMsgILSupport" BO_ 1666 0;
BA_ "DiagConnection" BO_ 1666 11111;
BA_ "GenMsgSendType" BO_ 1666 3;
BA_ "DiagRequest" BO_ 1666 1;
BA_ "VFrameFormat" BO_ 1666 14;
BA_ "GenMsgSendType" BO_ 1714 3;
BA_ "DiagRequest" BO_ 1714 1;
BA_ "DiagConnection" BO_ 1714 11112;
BA_ "GenMsgILSupport" BO_ 1714 0;
BA_ "VFrameFormat" BO_ 1714 14;
BA_ "GenMsgSendType" BO_ 1791 3;
BA_ "DiagRequest" BO_ 1791 1;
BA_ "DiagConnection" BO_ 1791 11113;
BA_ "GenMsgILSupport" BO_ 1791 0;
BA_ "VFrameFormat" BO_ 1791 14;
BA_ "GenSigTimeoutTime" SG_ 1131 CRC_IVI_DrvrSeatStoredProfile 10000;
BA_ "GenSigStartValue" SG_ 1131 CRC_IVI_DrvrSeatStoredProfile 255;
BA_ "InvalidValue" SG_ 1131 AlvCtr_IVI_DrvrSeatStoredProfile "15";
BA_ "GenSigTimeoutTime" SG_ 1131 AlvCtr_IVI_DrvrSeatStoredProfile 10000;
BA_ "GenSigStartValue" SG_ 1131 AlvCtr_IVI_DrvrSeatStoredProfile 15;
BA_ "InvalidValue" SG_ 1131 SeatAdjmt_DrvFowdBawdStoredPosn "2047";
BA_ "GenSigTimeoutTime" SG_ 1131 SeatAdjmt_DrvFowdBawdStoredPosn 10000;
BA_ "GenSigSendType" SG_ 1131 SeatAdjmt_DrvFowdBawdStoredPosn 2;
BA_ "InvalidValue" SG_ 1131 SeatAdjmt_DrvReclnrStoredPosn "8191";
BA_ "GenSigTimeoutTime" SG_ 1131 SeatAdjmt_DrvReclnrStoredPosn 10000;
BA_ "GenSigSendType" SG_ 1131 SeatAdjmt_DrvReclnrStoredPosn 2;
BA_ "InvalidValue" SG_ 1131 SeatAdjmt_DrvHeiStoredPosn "2047";
BA_ "GenSigTimeoutTime" SG_ 1131 SeatAdjmt_DrvHeiStoredPosn 10000;
BA_ "GenSigSendType" SG_ 1131 SeatAdjmt_DrvHeiStoredPosn 2;
BA_ "InvalidValue" SG_ 1131 SeatAdjmt_DrvTiltStoredPosn "1023";
BA_ "GenSigTimeoutTime" SG_ 1131 SeatAdjmt_DrvTiltStoredPosn 10000;
BA_ "GenSigSendType" SG_ 1131 SeatAdjmt_DrvTiltStoredPosn 2;
BA_ "InvalidValue" SG_ 1140 DriverId_Byte1 "255";
BA_ "GenSigTimeoutTime" SG_ 1140 DriverId_Byte1 10000;
BA_ "GenSigSendType" SG_ 1140 DriverId_Byte1 2;
BA_ "InvalidValue" SG_ 1140 DriverId_Byte2 "255";
BA_ "GenSigTimeoutTime" SG_ 1140 DriverId_Byte2 10000;
BA_ "GenSigSendType" SG_ 1140 DriverId_Byte2 2;
BA_ "InvalidValue" SG_ 1140 DriverId_Byte3 "255";
BA_ "GenSigTimeoutTime" SG_ 1140 DriverId_Byte3 10000;
BA_ "GenSigSendType" SG_ 1140 DriverId_Byte3 2;
BA_ "InvalidValue" SG_ 1140 DriverId_Byte4 "255";
BA_ "GenSigTimeoutTime" SG_ 1140 DriverId_Byte4 10000;
BA_ "GenSigSendType" SG_ 1140 DriverId_Byte4 2;
BA_ "InvalidValue" SG_ 1140 DriverId_Byte5 "255";
BA_ "GenSigTimeoutTime" SG_ 1140 DriverId_Byte5 10000;
BA_ "GenSigSendType" SG_ 1140 DriverId_Byte5 2;
BA_ "InvalidValue" SG_ 1140 DriverId_Byte6 "255";
BA_ "GenSigTimeoutTime" SG_ 1140 DriverId_Byte6 10000;
BA_ "GenSigSendType" SG_ 1140 DriverId_Byte6 2;
BA_ "InvalidValue" SG_ 1140 DriverId_Byte7 "255";
BA_ "GenSigTimeoutTime" SG_ 1140 DriverId_Byte7 10000;
BA_ "GenSigSendType" SG_ 1140 DriverId_Byte7 2;
BA_ "InvalidValue" SG_ 1140 DriverId_Byte8 "255";
BA_ "GenSigTimeoutTime" SG_ 1140 DriverId_Byte8 10000;
BA_ "GenSigSendType" SG_ 1140 DriverId_Byte8 2;
BA_ "InvalidValue" SG_ 1140 DriverId_Byte9 "255";
BA_ "GenSigTimeoutTime" SG_ 1140 DriverId_Byte9 10000;
BA_ "GenSigSendType" SG_ 1140 DriverId_Byte9 2;
BA_ "InvalidValue" SG_ 1140 DriverId_Byte10 "255";
BA_ "GenSigTimeoutTime" SG_ 1140 DriverId_Byte10 10000;
BA_ "GenSigSendType" SG_ 1140 DriverId_Byte10 2;
BA_ "InvalidValue" SG_ 1140 DriverId_Byte11 "255";
BA_ "GenSigTimeoutTime" SG_ 1140 DriverId_Byte11 10000;
BA_ "GenSigSendType" SG_ 1140 DriverId_Byte11 2;
BA_ "InvalidValue" SG_ 1140 DriverId_Byte12 "255";
BA_ "GenSigTimeoutTime" SG_ 1140 DriverId_Byte12 10000;
BA_ "GenSigSendType" SG_ 1140 DriverId_Byte12 2;
BA_ "InvalidValue" SG_ 1140 DriverId_Byte13 "255";
BA_ "GenSigTimeoutTime" SG_ 1140 DriverId_Byte13 10000;
BA_ "GenSigSendType" SG_ 1140 DriverId_Byte13 2;
BA_ "InvalidValue" SG_ 1140 DriverId_Byte14 "255";
BA_ "GenSigTimeoutTime" SG_ 1140 DriverId_Byte14 10000;
BA_ "GenSigSendType" SG_ 1140 DriverId_Byte14 2;
BA_ "InvalidValue" SG_ 1140 DriverId_Byte15 "255";
BA_ "GenSigTimeoutTime" SG_ 1140 DriverId_Byte15 10000;
BA_ "GenSigSendType" SG_ 1140 DriverId_Byte15 2;
BA_ "InvalidValue" SG_ 1140 DriverId_Byte16 "255";
BA_ "GenSigTimeoutTime" SG_ 1140 DriverId_Byte16 10000;
BA_ "GenSigSendType" SG_ 1140 DriverId_Byte16 2;
BA_ "GenSigTimeoutTime" SG_ 1141 CRC_IVI_HvacCntrl 10000;
BA_ "GenSigStartValue" SG_ 1141 CRC_IVI_HvacCntrl 255;
BA_ "InvalidValue" SG_ 1141 AlvCtr_IVI_HvacCntrl "15";
BA_ "GenSigTimeoutTime" SG_ 1141 AlvCtr_IVI_HvacCntrl 10000;
BA_ "GenSigStartValue" SG_ 1141 AlvCtr_IVI_HvacCntrl 15;
BA_ "InvalidValue" SG_ 1141 Ccsf_VentOpModeReq "3";
BA_ "GenSigTimeoutTime" SG_ 1141 Ccsf_VentOpModeReq 10000;
BA_ "InvalidValue" SG_ 1141 Ccs_ReAcUsrIReq "3";
BA_ "GenSigTimeoutTime" SG_ 1141 Ccs_ReAcUsrIReq 10000;
BA_ "GenSigSendType" SG_ 1141 Ccs_ReAcUsrIReq 2;
BA_ "InvalidValue" SG_ 1141 Demir_HeatgSVMCReq "3";
BA_ "GenSigTimeoutTime" SG_ 1141 Demir_HeatgSVMCReq 10000;
BA_ "GenSigSendType" SG_ 1141 Demir_HeatgSVMCReq 2;
BA_ "InvalidValue" SG_ 1141 Ccs_ReBlowrLvUsrlReq "7";
BA_ "GenSigTimeoutTime" SG_ 1141 Ccs_ReBlowrLvUsrlReq 10000;
BA_ "GenSigSendType" SG_ 1141 Ccs_ReBlowrLvUsrlReq 2;
BA_ "InvalidValue" SG_ 1147 Ccs_AcMinTUsrBtn "3";
BA_ "GenSigTimeoutTime" SG_ 1147 Ccs_AcMinTUsrBtn 10000;
BA_ "InvalidValue" SG_ 1147 Ccs_AcMaxTUsrBtn "3";
BA_ "GenSigTimeoutTime" SG_ 1147 Ccs_AcMaxTUsrBtn 10000;
BA_ "InvalidValue" SG_ 1147 Ccs_RclOnOffReq "3";
BA_ "GenSigTimeoutTime" SG_ 1147 Ccs_RclOnOffReq 10000;
BA_ "GenSigSendType" SG_ 1147 Ccs_RclOnOffReq 2;
BA_ "InvalidValue" SG_ 1147 Ccs_FrntAcUsrReq "3";
BA_ "GenSigTimeoutTime" SG_ 1147 Ccs_FrntAcUsrReq 10000;
BA_ "GenSigSendType" SG_ 1147 Ccs_FrntAcUsrReq 2;
BA_ "InvalidValue" SG_ 1147 Ccs_ReLeTUsrSetReq "15";
BA_ "GenSigTimeoutTime" SG_ 1147 Ccs_ReLeTUsrSetReq 10000;
BA_ "GenSigStartValue" SG_ 1147 Ccs_ReLeTUsrSetReq 4;
BA_ "GenSigSendType" SG_ 1147 Ccs_ReLeTUsrSetReq 2;
BA_ "InvalidValue" SG_ 1147 Ccs_ReRiTUsrISetVal "15";
BA_ "GenSigTimeoutTime" SG_ 1147 Ccs_ReRiTUsrISetVal 10000;
BA_ "GenSigStartValue" SG_ 1147 Ccs_ReRiTUsrISetVal 4;
BA_ "GenSigSendType" SG_ 1147 Ccs_ReRiTUsrISetVal 1;
BA_ "InvalidValue" SG_ 1147 Ccs_SyncTReq "3";
BA_ "GenSigTimeoutTime" SG_ 1147 Ccs_SyncTReq 10000;
BA_ "GenSigSendType" SG_ 1147 Ccs_SyncTReq 2;
BA_ "InvalidValue" SG_ 1147 Ccs_AcEcoModeBtnUsrReq "3";
BA_ "GenSigTimeoutTime" SG_ 1147 Ccs_AcEcoModeBtnUsrReq 10000;
BA_ "GenSigSendType" SG_ 1147 Ccs_AcEcoModeBtnUsrReq 2;
BA_ "InvalidValue" SG_ 1147 Ccs_FrntAcAutoModUsrReq "3";
BA_ "GenSigTimeoutTime" SG_ 1147 Ccs_FrntAcAutoModUsrReq 10000;
BA_ "GenSigSendType" SG_ 1147 Ccs_FrntAcAutoModUsrReq 2;
BA_ "InvalidValue" SG_ 1147 Ccs_IoniserUsrReq "3";
BA_ "GenSigTimeoutTime" SG_ 1147 Ccs_IoniserUsrReq 10000;
BA_ "GenSigSendType" SG_ 1147 Ccs_IoniserUsrReq 2;
BA_ "InvalidValue" SG_ 1147 Ccs_FrgrncAcvnUsrReq "3";
BA_ "GenSigTimeoutTime" SG_ 1147 Ccs_FrgrncAcvnUsrReq 10000;
BA_ "GenSigSendType" SG_ 1147 Ccs_FrgrncAcvnUsrReq 2;
BA_ "InvalidValue" SG_ 1147 Ccs_DemistDefrstUsrReq "3";
BA_ "GenSigTimeoutTime" SG_ 1147 Ccs_DemistDefrstUsrReq 10000;
BA_ "GenSigSendType" SG_ 1147 Ccs_DemistDefrstUsrReq 2;
BA_ "InvalidValue" SG_ 1147 Ccs_FrntLeTUsrSetVal "15";
BA_ "GenSigTimeoutTime" SG_ 1147 Ccs_FrntLeTUsrSetVal 10000;
BA_ "GenSigStartValue" SG_ 1147 Ccs_FrntLeTUsrSetVal 4;
BA_ "GenSigSendType" SG_ 1147 Ccs_FrntLeTUsrSetVal 2;
BA_ "InvalidValue" SG_ 1147 Ccs_FrgrncIntenUsrReq "15";
BA_ "GenSigTimeoutTime" SG_ 1147 Ccs_FrgrncIntenUsrReq 10000;
BA_ "GenSigSendType" SG_ 1147 Ccs_FrgrncIntenUsrReq 2;
BA_ "InvalidValue" SG_ 1147 Ccs_FrntBlowrLvlUsrReq "7";
BA_ "GenSigTimeoutTime" SG_ 1147 Ccs_FrntBlowrLvlUsrReq 10000;
BA_ "GenSigSendType" SG_ 1147 Ccs_FrntBlowrLvlUsrReq 2;
BA_ "InvalidValue" SG_ 1147 Ccs_AirModeSelnUsrReq "7";
BA_ "GenSigTimeoutTime" SG_ 1147 Ccs_AirModeSelnUsrReq 10000;
BA_ "GenSigSendType" SG_ 1147 Ccs_AirModeSelnUsrReq 2;
BA_ "InvalidValue" SG_ 1147 Ccs_FrntRiTUsrSetVal "15";
BA_ "GenSigTimeoutTime" SG_ 1147 Ccs_FrntRiTUsrSetVal 10000;
BA_ "GenSigStartValue" SG_ 1147 Ccs_FrntRiTUsrSetVal 4;
BA_ "InvalidValue" SG_ 1147 Ccs_ClimPrsetUsrReq "7";
BA_ "GenSigTimeoutTime" SG_ 1147 Ccs_ClimPrsetUsrReq 10000;
BA_ "GenSigSendType" SG_ 1147 Ccs_ClimPrsetUsrReq 2;
BA_ "InvalidValue" SG_ 1147 Ccs_FrgrncSlenUsrReq "7";
BA_ "GenSigTimeoutTime" SG_ 1147 Ccs_FrgrncSlenUsrReq 10000;
BA_ "GenSigSendType" SG_ 1147 Ccs_FrgrncSlenUsrReq 2;
BA_ "InvalidValue" SG_ 1147 Ccs_ClimPrflSelnUsrReq "7";
BA_ "GenSigTimeoutTime" SG_ 1147 Ccs_ClimPrflSelnUsrReq 10000;
BA_ "GenSigSendType" SG_ 1147 Ccs_ClimPrflSelnUsrReq 2;
BA_ "GenSigTimeoutTime" SG_ 1157 CRC_IVI_UsrBodyCntrl_Req 10000;
BA_ "GenSigStartValue" SG_ 1157 CRC_IVI_UsrBodyCntrl_Req 65535;
BA_ "GenSigTimeoutTime" SG_ 1157 AlvCtr_IVI_UsrBodyCntrl_Req 10000;
BA_ "GenSigStartValue" SG_ 1157 AlvCtr_IVI_UsrBodyCntrl_Req 255;
BA_ "InvalidValue" SG_ 1157 ChrgrPort_ChrgPortLckUnlckUsrReq "3";
BA_ "GenSigTimeoutTime" SG_ 1157 ChrgrPort_ChrgPortLckUnlckUsrReq 10000;
BA_ "GenSigSendType" SG_ 1157 ChrgrPort_ChrgPortLckUnlckUsrReq 2;
BA_ "InvalidValue" SG_ 1157 Demir_FoldUnfoldSVMCReq "3";
BA_ "GenSigTimeoutTime" SG_ 1157 Demir_FoldUnfoldSVMCReq 10000;
BA_ "GenSigSendType" SG_ 1157 Demir_FoldUnfoldSVMCReq 2;
BA_ "InvalidValue" SG_ 1157 Demir_FoldUnfoldUsrReq "3";
BA_ "GenSigTimeoutTime" SG_ 1157 Demir_FoldUnfoldUsrReq 10000;
BA_ "GenSigSendType" SG_ 1157 Demir_FoldUnfoldUsrReq 2;
BA_ "InvalidValue" SG_ 1157 Demir_HeatgSVMC_Ena "3";
BA_ "GenSigTimeoutTime" SG_ 1157 Demir_HeatgSVMC_Ena 10000;
BA_ "GenSigSendType" SG_ 1157 Demir_HeatgSVMC_Ena 2;
BA_ "InvalidValue" SG_ 1157 Acttg_TailGateUsrAgReq "127";
BA_ "GenSigTimeoutTime" SG_ 1157 Acttg_TailGateUsrAgReq 10000;
BA_ "GenSigSendType" SG_ 1157 Acttg_TailGateUsrAgReq 2;
BA_ "InvalidValue" SG_ 1157 Acttg_TailGateUsrReq "3";
BA_ "GenSigTimeoutTime" SG_ 1157 Acttg_TailGateUsrReq 10000;
BA_ "GenSigStartValue" SG_ 1157 Acttg_TailGateUsrReq 3;
BA_ "GenSigSendType" SG_ 1157 Acttg_TailGateUsrReq 2;
BA_ "InvalidValue" SG_ 1157 Ssadl_AutoSpdLockVal "63";
BA_ "GenSigTimeoutTime" SG_ 1157 Ssadl_AutoSpdLockVal 10000;
BA_ "GenSigSendType" SG_ 1157 Ssadl_AutoSpdLockVal 2;
BA_ "InvalidValue" SG_ 1157 Ssadl_AutoSpdLockOnOffTypSts "3";
BA_ "GenSigTimeoutTime" SG_ 1157 Ssadl_AutoSpdLockOnOffTypSts 10000;
BA_ "GenSigSendType" SG_ 1157 Ssadl_AutoSpdLockOnOffTypSts 2;
BA_ "InvalidValue" SG_ 1157 Relamp_ReFogLiReq "3";
BA_ "GenSigTimeoutTime" SG_ 1157 Relamp_ReFogLiReq 10000;
BA_ "GenSigSendType" SG_ 1157 Relamp_ReFogLiReq 2;
BA_ "InvalidValue" SG_ 1157 Hdlamp_LampReq "3";
BA_ "GenSigTimeoutTime" SG_ 1157 Hdlamp_LampReq 10000;
BA_ "GenSigSendType" SG_ 1157 Hdlamp_LampReq 2;
BA_ "InvalidValue" SG_ 1157 Hdlamp_AutoModeCfgReq "3";
BA_ "GenSigTimeoutTime" SG_ 1157 Hdlamp_AutoModeCfgReq 10000;
BA_ "GenSigSendType" SG_ 1157 Hdlamp_AutoModeCfgReq 2;
BA_ "InvalidValue" SG_ 1157 Hdlamp_FollowMeCfg "7";
BA_ "GenSigTimeoutTime" SG_ 1157 Hdlamp_FollowMeCfg 10000;
BA_ "GenSigSendType" SG_ 1157 Hdlamp_FollowMeCfg 2;
BA_ "InvalidValue" SG_ 1157 Wipr_FrntWiprReq "7";
BA_ "GenSigTimeoutTime" SG_ 1157 Wipr_FrntWiprReq 10000;
BA_ "GenSigSendType" SG_ 1157 Wipr_FrntWiprReq 2;
BA_ "InvalidValue" SG_ 1157 Wipr_FrntOperParkReq "3";
BA_ "GenSigTimeoutTime" SG_ 1157 Wipr_FrntOperParkReq 10000;
BA_ "GenSigStartValue" SG_ 1157 Wipr_FrntOperParkReq 3;
BA_ "InvalidValue" SG_ 1157 Wipr_FrntWiprSrvPosReq "3";
BA_ "GenSigTimeoutTime" SG_ 1157 Wipr_FrntWiprSrvPosReq 10000;
BA_ "GenSigSendType" SG_ 1157 Wipr_FrntWiprSrvPosReq 2;
BA_ "GenSigTimeoutTime" SG_ 1163 CRC_IVI_UsrChassisCntrl_Req 10000;
BA_ "GenSigStartValue" SG_ 1163 CRC_IVI_UsrChassisCntrl_Req 65535;
BA_ "GenSigTimeoutTime" SG_ 1163 AlvCtr_IVI_UsrChassisCntrl_Req 10000;
BA_ "GenSigStartValue" SG_ 1163 AlvCtr_IVI_UsrChassisCntrl_Req 255;
BA_ "InvalidValue" SG_ 1163 Hdc_SwtSts "3";
BA_ "GenSigTimeoutTime" SG_ 1163 Hdc_SwtSts 10000;
BA_ "GenSigSendType" SG_ 1163 Hdc_SwtSts 2;
BA_ "InvalidValue" SG_ 1163 EscTcs_SwtSts "3";
BA_ "GenSigTimeoutTime" SG_ 1163 EscTcs_SwtSts 10000;
BA_ "GenSigSendType" SG_ 1163 EscTcs_SwtSts 2;
BA_ "InvalidValue" SG_ 1163 IVI_IngrsModeCmd "3";
BA_ "GenSigTimeoutTime" SG_ 1163 IVI_IngrsModeCmd 10000;
BA_ "GenSigSendType" SG_ 1163 IVI_IngrsModeCmd 2;
BA_ "InvalidValue" SG_ 1163 AVH_Swt_Sts "3";
BA_ "GenSigTimeoutTime" SG_ 1163 AVH_Swt_Sts 10000;
BA_ "GenSigStartValue" SG_ 1163 AVH_Swt_Sts 3;
BA_ "InvalidValue" SG_ 1163 IVI_SuspHeiAdjReq "7";
BA_ "GenSigTimeoutTime" SG_ 1163 IVI_SuspHeiAdjReq 10000;
BA_ "GenSigSendType" SG_ 1163 IVI_SuspHeiAdjReq 2;
BA_ "InvalidValue" SG_ 1163 IVI_SrvModCmd "3";
BA_ "GenSigTimeoutTime" SG_ 1163 IVI_SrvModCmd 10000;
BA_ "GenSigStartValue" SG_ 1163 IVI_SrvModCmd 3;
BA_ "GenSigTimeoutTime" SG_ 1173 CRC_IVI_UsrSeatAdjComfrt_Req 10000;
BA_ "GenSigStartValue" SG_ 1173 CRC_IVI_UsrSeatAdjComfrt_Req 255;
BA_ "InvalidValue" SG_ 1173 AlvCtr_IVI_UsrSeatAdjComfrt_Req "15";
BA_ "GenSigTimeoutTime" SG_ 1173 AlvCtr_IVI_UsrSeatAdjComfrt_Req 10000;
BA_ "GenSigStartValue" SG_ 1173 AlvCtr_IVI_UsrSeatAdjComfrt_Req 15;
BA_ "InvalidValue" SG_ 1173 SeatAdjmt_DrvFowdBawdReq "3";
BA_ "GenSigTimeoutTime" SG_ 1173 SeatAdjmt_DrvFowdBawdReq 10000;
BA_ "GenSigSendType" SG_ 1173 SeatAdjmt_DrvFowdBawdReq 2;
BA_ "InvalidValue" SG_ 1173 SeatAdjmt_DrvHeiUpDwnReq "3";
BA_ "GenSigTimeoutTime" SG_ 1173 SeatAdjmt_DrvHeiUpDwnReq 10000;
BA_ "GenSigSendType" SG_ 1173 SeatAdjmt_DrvHeiUpDwnReq 2;
BA_ "InvalidValue" SG_ 1173 SeatAdjmt_DrvLumInOutReq "3";
BA_ "GenSigTimeoutTime" SG_ 1173 SeatAdjmt_DrvLumInOutReq 10000;
BA_ "GenSigSendType" SG_ 1173 SeatAdjmt_DrvLumInOutReq 2;
BA_ "InvalidValue" SG_ 1173 SeatAdjmt_DrvLumUpDwnReq "3";
BA_ "GenSigTimeoutTime" SG_ 1173 SeatAdjmt_DrvLumUpDwnReq 10000;
BA_ "GenSigSendType" SG_ 1173 SeatAdjmt_DrvLumUpDwnReq 2;
BA_ "InvalidValue" SG_ 1173 SeatAdjmt_DrvReclUpDownReq "3";
BA_ "GenSigTimeoutTime" SG_ 1173 SeatAdjmt_DrvReclUpDownReq 10000;
BA_ "GenSigSendType" SG_ 1173 SeatAdjmt_DrvReclUpDownReq 2;
BA_ "InvalidValue" SG_ 1173 SeatCfmt_DrvMassgIntenSelnReq "7";
BA_ "GenSigTimeoutTime" SG_ 1173 SeatCfmt_DrvMassgIntenSelnReq 10000;
BA_ "GenSigSendType" SG_ 1173 SeatCfmt_DrvMassgIntenSelnReq 2;
BA_ "InvalidValue" SG_ 1173 SeatCfmt_DrvMassgPatSelnReq "7";
BA_ "GenSigTimeoutTime" SG_ 1173 SeatCfmt_DrvMassgPatSelnReq 10000;
BA_ "GenSigSendType" SG_ 1173 SeatCfmt_DrvMassgPatSelnReq 2;
BA_ "InvalidValue" SG_ 1173 SeatAdjmt_PassFowdBawdReq "3";
BA_ "GenSigTimeoutTime" SG_ 1173 SeatAdjmt_PassFowdBawdReq 10000;
BA_ "GenSigSendType" SG_ 1173 SeatAdjmt_PassFowdBawdReq 2;
BA_ "InvalidValue" SG_ 1173 SeatAdjmt_PassHeiUpDwnReq "3";
BA_ "GenSigTimeoutTime" SG_ 1173 SeatAdjmt_PassHeiUpDwnReq 10000;
BA_ "GenSigSendType" SG_ 1173 SeatAdjmt_PassHeiUpDwnReq 2;
BA_ "InvalidValue" SG_ 1173 SeatAdjmt_PassLumInOutReq "3";
BA_ "GenSigTimeoutTime" SG_ 1173 SeatAdjmt_PassLumInOutReq 10000;
BA_ "GenSigSendType" SG_ 1173 SeatAdjmt_PassLumInOutReq 2;
BA_ "InvalidValue" SG_ 1173 SeatAdjmt_PassLumUpDwnReq "3";
BA_ "GenSigTimeoutTime" SG_ 1173 SeatAdjmt_PassLumUpDwnReq 10000;
BA_ "GenSigStartValue" SG_ 1173 SeatAdjmt_PassLumUpDwnReq 3;
BA_ "InvalidValue" SG_ 1173 SeatAdjmt_PassReclUpDownReq "3";
BA_ "GenSigTimeoutTime" SG_ 1173 SeatAdjmt_PassReclUpDownReq 10000;
BA_ "GenSigSendType" SG_ 1173 SeatAdjmt_PassReclUpDownReq 2;
BA_ "InvalidValue" SG_ 1173 SeatAdjmt_PassTiltUpDwnReq "3";
BA_ "GenSigTimeoutTime" SG_ 1173 SeatAdjmt_PassTiltUpDwnReq 10000;
BA_ "GenSigStartValue" SG_ 1173 SeatAdjmt_PassTiltUpDwnReq 3;
BA_ "GenSigSendType" SG_ 1173 SeatAdjmt_PassTiltUpDwnReq 2;
BA_ "InvalidValue" SG_ 1173 SeatAdjmt_DrvTiltUpDwnReq "3";
BA_ "GenSigTimeoutTime" SG_ 1173 SeatAdjmt_DrvTiltUpDwnReq 10000;
BA_ "GenSigSendType" SG_ 1173 SeatAdjmt_DrvTiltUpDwnReq 2;
BA_ "InvalidValue" SG_ 1173 SeatCfmt_PassMassgIntenSelnReq "7";
BA_ "GenSigTimeoutTime" SG_ 1173 SeatCfmt_PassMassgIntenSelnReq 10000;
BA_ "GenSigSendType" SG_ 1173 SeatCfmt_PassMassgIntenSelnReq 2;
BA_ "InvalidValue" SG_ 1173 SeatCfmt_PassMassgPatSelnReq "7";
BA_ "GenSigTimeoutTime" SG_ 1173 SeatCfmt_PassMassgPatSelnReq 10000;
BA_ "GenSigSendType" SG_ 1173 SeatCfmt_PassMassgPatSelnReq 2;
BA_ "InvalidValue" SG_ 1173 SeatCfmt_ReLeVentnSpdReq "7";
BA_ "GenSigTimeoutTime" SG_ 1173 SeatCfmt_ReLeVentnSpdReq 10000;
BA_ "GenSigSendType" SG_ 1173 SeatCfmt_ReLeVentnSpdReq 2;
BA_ "InvalidValue" SG_ 1173 SeatCfmt_ReRiVentnSpdReq "7";
BA_ "GenSigTimeoutTime" SG_ 1173 SeatCfmt_ReRiVentnSpdReq 10000;
BA_ "GenSigSendType" SG_ 1173 SeatCfmt_ReRiVentnSpdReq 2;
BA_ "GenSigTimeoutTime" SG_ 1179 CRC_IVI_Vehicle_Mode_Ctrl 10000;
BA_ "GenSigStartValue" SG_ 1179 CRC_IVI_Vehicle_Mode_Ctrl 65535;
BA_ "GenSigTimeoutTime" SG_ 1179 AlvCtr_IVI_Vehicle_Mode_Ctrl 10000;
BA_ "GenSigStartValue" SG_ 1179 AlvCtr_IVI_Vehicle_Mode_Ctrl 255;
BA_ "InvalidValue" SG_ 1179 Klss_UsrVehPwrDnReq "3";
BA_ "GenSigTimeoutTime" SG_ 1179 Klss_UsrVehPwrDnReq 10000;
BA_ "GenSigSendType" SG_ 1179 Klss_UsrVehPwrDnReq 2;
BA_ "InvalidValue" SG_ 1179 HMI_KeepAlive "3";
BA_ "GenSigTimeoutTime" SG_ 1179 HMI_KeepAlive 10000;
BA_ "GenSigSendType" SG_ 1179 HMI_KeepAlive 2;
BA_ "InvalidValue" SG_ 1179 Lvm_LongParkMode_Req "3";
BA_ "GenSigTimeoutTime" SG_ 1179 Lvm_LongParkMode_Req 10000;
BA_ "GenSigSendType" SG_ 1179 Lvm_LongParkMode_Req 2;
BA_ "InvalidValue" SG_ 1179 Lvm_StorageMode_Req "3";
BA_ "GenSigTimeoutTime" SG_ 1179 Lvm_StorageMode_Req 10000;
BA_ "GenSigSendType" SG_ 1179 Lvm_StorageMode_Req 2;
BA_ "InvalidValue" SG_ 1179 Drvmc_Mode_Req "7";
BA_ "GenSigTimeoutTime" SG_ 1179 Drvmc_Mode_Req 10000;
BA_ "GenSigSendType" SG_ 1179 Drvmc_Mode_Req 2;
BA_ "InvalidValue" SG_ 1179 Eshift_TagtGear_Req "7";
BA_ "GenSigTimeoutTime" SG_ 1179 Eshift_TagtGear_Req 10000;
BA_ "GenSigSendType" SG_ 1179 Eshift_TagtGear_Req 2;
BA_ "GenSigTimeoutTime" SG_ 1411 CRC_TBOX_Warning 10000;
BA_ "GenSigTimeoutTime" SG_ 1411 AlvCtr_TBOX_Warning 10000;
BA_ "GenSigStartValue" SG_ 1411 AlvCtr_TBOX_Warning 255;
BA_ "InvalidValue" SG_ 1411 Kle_NfcCcCardVldtn_St_Warn "3";
BA_ "GenSigTimeoutTime" SG_ 1411 Kle_NfcCcCardVldtn_St_Warn 10000;
BA_ "GenSigStartValue" SG_ 1411 Kle_NfcCcCardVldtn_St_Warn 3;
BA_ "GenSigSendType" SG_ 1411 Kle_NfcCcCardVldtn_St_Warn 2;
BA_ "GenSigTimeoutTime" SG_ 1412 CRC_VCU_Warning 10000;
BA_ "GenSigStartValue" SG_ 1412 CRC_VCU_Warning 65535;
BA_ "GenSigTimeoutTime" SG_ 1412 AlvCtr_VCU_Warning 10000;
BA_ "GenSigStartValue" SG_ 1412 AlvCtr_VCU_Warning 255;
BA_ "InvalidValue" SG_ 1412 Acchg_ChgGunUnlckWarn "3";
BA_ "GenSigTimeoutTime" SG_ 1412 Acchg_ChgGunUnlckWarn 10000;
BA_ "GenSigSendType" SG_ 1412 Acchg_ChgGunUnlckWarn 2;
BA_ "InvalidValue" SG_ 1412 Hvsco_HV_SysWarn "3";
BA_ "GenSigTimeoutTime" SG_ 1412 Hvsco_HV_SysWarn 10000;
BA_ "GenSigSendType" SG_ 1412 Hvsco_HV_SysWarn 2;
BA_ "InvalidValue" SG_ 1412 Thmgt_CooltOverTWarn "3";
BA_ "GenSigTimeoutTime" SG_ 1412 Thmgt_CooltOverTWarn 10000;
BA_ "GenSigSendType" SG_ 1412 Thmgt_CooltOverTWarn 2;
BA_ "InvalidValue" SG_ 1412 Eshift_PsdBrkToEngeGear "3";
BA_ "GenSigTimeoutTime" SG_ 1412 Eshift_PsdBrkToEngeGear 10000;
BA_ "GenSigSendType" SG_ 1412 Eshift_PsdBrkToEngeGear 2;
BA_ "InvalidValue" SG_ 1412 Awd_WhlDrvModeWarn "3";
BA_ "GenSigTimeoutTime" SG_ 1412 Awd_WhlDrvModeWarn 10000;
BA_ "GenSigSendType" SG_ 1412 Awd_WhlDrvModeWarn 2;
BA_ "InvalidValue" SG_ 1412 Drvmc_DrvModeChngRestrWarn "3";
BA_ "GenSigTimeoutTime" SG_ 1412 Drvmc_DrvModeChngRestrWarn 10000;
BA_ "GenSigSendType" SG_ 1412 Drvmc_DrvModeChngRestrWarn 2;
BA_ "InvalidValue" SG_ 1412 Eshift_HvDcnctNoGearChngWarn "3";
BA_ "GenSigTimeoutTime" SG_ 1412 Eshift_HvDcnctNoGearChngWarn 10000;
BA_ "GenSigSendType" SG_ 1412 Eshift_HvDcnctNoGearChngWarn 2;
BA_ "InvalidValue" SG_ 1412 Eshift_GearChng_EPBEngeWarn "3";
BA_ "GenSigTimeoutTime" SG_ 1412 Eshift_GearChng_EPBEngeWarn 10000;
BA_ "GenSigSendType" SG_ 1412 Eshift_GearChng_EPBEngeWarn 2;
BA_ "InvalidValue" SG_ 1412 Thmgt_CooltLvlLoWarn "3";
BA_ "GenSigTimeoutTime" SG_ 1412 Thmgt_CooltLvlLoWarn 10000;
BA_ "GenSigSendType" SG_ 1412 Thmgt_CooltLvlLoWarn 2;
BA_ "InvalidValue" SG_ 1412 Eshift_StopVehToMoveFowdDir "3";
BA_ "GenSigTimeoutTime" SG_ 1412 Eshift_StopVehToMoveFowdDir 10000;
BA_ "GenSigSendType" SG_ 1412 Eshift_StopVehToMoveFowdDir 2;
BA_ "InvalidValue" SG_ 1412 Hvsft_HvsftSts "3";
BA_ "GenSigTimeoutTime" SG_ 1412 Hvsft_HvsftSts 10000;
BA_ "GenSigSendType" SG_ 1412 Hvsft_HvsftSts 2;
BA_ "InvalidValue" SG_ 1412 VCU_LimphmWarn "3";
BA_ "GenSigTimeoutTime" SG_ 1412 VCU_LimphmWarn 10000;
BA_ "GenSigSendType" SG_ 1412 VCU_LimphmWarn 2;
BA_ "InvalidValue" SG_ 1412 Eshift_EppFaiWarn "3";
BA_ "GenSigTimeoutTime" SG_ 1412 Eshift_EppFaiWarn 10000;
BA_ "GenSigSendType" SG_ 1412 Eshift_EppFaiWarn 2;
BA_ "InvalidValue" SG_ 1412 Thmgt_Therm_FltWarn "3";
BA_ "GenSigTimeoutTime" SG_ 1412 Thmgt_Therm_FltWarn 10000;
BA_ "GenSigSendType" SG_ 1412 Thmgt_Therm_FltWarn 2;
BA_ "InvalidValue" SG_ 1412 Acchr_ChgAuthWarn "3";
BA_ "GenSigTimeoutTime" SG_ 1412 Acchr_ChgAuthWarn 10000;
BA_ "GenSigSendType" SG_ 1412 Acchr_ChgAuthWarn 2;
BA_ "InvalidValue" SG_ 1412 Eshift_ACT_GearWarn "3";
BA_ "GenSigTimeoutTime" SG_ 1412 Eshift_ACT_GearWarn 10000;
BA_ "GenSigSendType" SG_ 1412 Eshift_ACT_GearWarn 2;
BA_ "InvalidValue" SG_ 1412 Eshift_TagtGearVldtnWarn "3";
BA_ "GenSigTimeoutTime" SG_ 1412 Eshift_TagtGearVldtnWarn 10000;
BA_ "GenSigSendType" SG_ 1412 Eshift_TagtGearVldtnWarn 2;
BA_ "InvalidValue" SG_ 1412 Hvsft_HvilErrWarn "3";
BA_ "GenSigTimeoutTime" SG_ 1412 Hvsft_HvilErrWarn 10000;
BA_ "GenSigSendType" SG_ 1412 Hvsft_HvilErrWarn 2;
BA_ "InvalidValue" SG_ 1412 Eshift_StopVehToMoveRvsDir "3";
BA_ "GenSigTimeoutTime" SG_ 1412 Eshift_StopVehToMoveRvsDir 10000;
BA_ "GenSigSendType" SG_ 1412 Eshift_StopVehToMoveRvsDir 2;
BA_ "InvalidValue" SG_ 1412 VCU_HV_Sys_FltLvl1Warn "3";
BA_ "GenSigTimeoutTime" SG_ 1412 VCU_HV_Sys_FltLvl1Warn 10000;
BA_ "GenSigSendType" SG_ 1412 VCU_HV_Sys_FltLvl1Warn 2;
BA_ "InvalidValue" SG_ 1412 VCU_HV_Sys_FltLvl2Warn "3";
BA_ "GenSigTimeoutTime" SG_ 1412 VCU_HV_Sys_FltLvl2Warn 10000;
BA_ "GenSigSendType" SG_ 1412 VCU_HV_Sys_FltLvl2Warn 2;
BA_ "InvalidValue" SG_ 1412 VCU_HV_Sys_FltLvl3Warn "3";
BA_ "GenSigTimeoutTime" SG_ 1412 VCU_HV_Sys_FltLvl3Warn 10000;
BA_ "GenSigSendType" SG_ 1412 VCU_HV_Sys_FltLvl3Warn 2;
BA_ "InvalidValue" SG_ 1412 Cregb_CoastRgnWarn "3";
BA_ "GenSigTimeoutTime" SG_ 1412 Cregb_CoastRgnWarn 10000;
BA_ "GenSigSendType" SG_ 1412 Cregb_CoastRgnWarn 2;
BA_ "GenSigTimeoutTime" SG_ 1413 CRC_ZCUF_Warning 10000;
BA_ "GenSigStartValue" SG_ 1413 CRC_ZCUF_Warning 65535;
BA_ "GenSigTimeoutTime" SG_ 1413 AlvCtr_ZCUF_Warning 10000;
BA_ "GenSigStartValue" SG_ 1413 AlvCtr_ZCUF_Warning 255;
BA_ "InvalidValue" SG_ 1413 CenLock_LockUnlckSts_Warn "3";
BA_ "GenSigTimeoutTime" SG_ 1413 CenLock_LockUnlckSts_Warn 10000;
BA_ "GenSigStartValue" SG_ 1413 CenLock_LockUnlckSts_Warn 3;
BA_ "GenSigSendType" SG_ 1413 CenLock_LockUnlckSts_Warn 2;
BA_ "InvalidValue" SG_ 1413 Wipr_FrntRiFaild_Warn "3";
BA_ "GenSigTimeoutTime" SG_ 1413 Wipr_FrntRiFaild_Warn 10000;
BA_ "GenSigStartValue" SG_ 1413 Wipr_FrntRiFaild_Warn 3;
BA_ "GenSigSendType" SG_ 1413 Wipr_FrntRiFaild_Warn 2;
BA_ "InvalidValue" SG_ 1413 SwtCtl_PassSeatHeatingSwFlt_Warn "3";
BA_ "GenSigTimeoutTime" SG_ 1413 SwtCtl_PassSeatHeatingSwFlt_Warn 10000;
BA_ "GenSigStartValue" SG_ 1413 SwtCtl_PassSeatHeatingSwFlt_Warn 3;
BA_ "GenSigSendType" SG_ 1413 SwtCtl_PassSeatHeatingSwFlt_Warn 2;
BA_ "InvalidValue" SG_ 1413 SwtCtl_VolSwtFlt_Warn "3";
BA_ "GenSigTimeoutTime" SG_ 1413 SwtCtl_VolSwtFlt_Warn 10000;
BA_ "GenSigStartValue" SG_ 1413 SwtCtl_VolSwtFlt_Warn 3;
BA_ "GenSigSendType" SG_ 1413 SwtCtl_VolSwtFlt_Warn 2;
BA_ "InvalidValue" SG_ 1413 Wipr_FrntLeFaild_Warn "3";
BA_ "GenSigTimeoutTime" SG_ 1413 Wipr_FrntLeFaild_Warn 10000;
BA_ "GenSigStartValue" SG_ 1413 Wipr_FrntLeFaild_Warn 3;
BA_ "GenSigSendType" SG_ 1413 Wipr_FrntLeFaild_Warn 2;
BA_ "InvalidValue" SG_ 1413 SwttCtl_DrvrStHeatngSwtFlt_Wrn "3";
BA_ "GenSigTimeoutTime" SG_ 1413 SwttCtl_DrvrStHeatngSwtFlt_Wrn 10000;
BA_ "GenSigStartValue" SG_ 1413 SwttCtl_DrvrStHeatngSwtFlt_Wrn 3;
BA_ "GenSigSendType" SG_ 1413 SwttCtl_DrvrStHeatngSwtFlt_Wrn 2;
BA_ "InvalidValue" SG_ 1413 Relamp_RevLmpWarn "3";
BA_ "GenSigTimeoutTime" SG_ 1413 Relamp_RevLmpWarn 10000;
BA_ "GenSigStartValue" SG_ 1413 Relamp_RevLmpWarn 3;
BA_ "GenSigSendType" SG_ 1413 Relamp_RevLmpWarn 2;
BA_ "InvalidValue" SG_ 1413 RLML_FogLmp_Warn "3";
BA_ "GenSigTimeoutTime" SG_ 1413 RLML_FogLmp_Warn 10000;
BA_ "GenSigStartValue" SG_ 1413 RLML_FogLmp_Warn 3;
BA_ "GenSigSendType" SG_ 1413 RLML_FogLmp_Warn 2;
BA_ "InvalidValue" SG_ 1413 SwtCtl_ChdLockSwtFault_Warn "3";
BA_ "GenSigTimeoutTime" SG_ 1413 SwtCtl_ChdLockSwtFault_Warn 10000;
BA_ "GenSigStartValue" SG_ 1413 SwtCtl_ChdLockSwtFault_Warn 3;
BA_ "GenSigSendType" SG_ 1413 SwtCtl_ChdLockSwtFault_Warn 2;
BA_ "InvalidValue" SG_ 1413 SwttCtl_ReclrnModOnOffSwtFlt_Wrn "3";
BA_ "GenSigTimeoutTime" SG_ 1413 SwttCtl_ReclrnModOnOffSwtFlt_Wrn 500;
BA_ "GenSigStartValue" SG_ 1413 SwttCtl_ReclrnModOnOffSwtFlt_Wrn 3;
BA_ "GenSigSendType" SG_ 1413 SwttCtl_ReclrnModOnOffSwtFlt_Wrn 2;
BA_ "InvalidValue" SG_ 1413 RLMR_FogLmp_Warn "3";
BA_ "GenSigTimeoutTime" SG_ 1413 RLMR_FogLmp_Warn 10000;
BA_ "GenSigStartValue" SG_ 1413 RLMR_FogLmp_Warn 3;
BA_ "GenSigSendType" SG_ 1413 RLMR_FogLmp_Warn 2;
BA_ "InvalidValue" SG_ 1413 Relamp_Chmsl_Warn "3";
BA_ "GenSigTimeoutTime" SG_ 1413 Relamp_Chmsl_Warn 10000;
BA_ "GenSigStartValue" SG_ 1413 Relamp_Chmsl_Warn 3;
BA_ "GenSigSendType" SG_ 1413 Relamp_Chmsl_Warn 2;
BA_ "InvalidValue" SG_ 1413 SwtCtl_HzrdSwtFlt_Warn "3";
BA_ "GenSigTimeoutTime" SG_ 1413 SwtCtl_HzrdSwtFlt_Warn 10000;
BA_ "GenSigStartValue" SG_ 1413 SwtCtl_HzrdSwtFlt_Warn 3;
BA_ "GenSigSendType" SG_ 1413 SwtCtl_HzrdSwtFlt_Warn 2;
BA_ "InvalidValue" SG_ 1413 Ssadl_DoorAct_Warn "3";
BA_ "GenSigTimeoutTime" SG_ 1413 Ssadl_DoorAct_Warn 10000;
BA_ "GenSigStartValue" SG_ 1413 Ssadl_DoorAct_Warn 3;
BA_ "GenSigSendType" SG_ 1413 Ssadl_DoorAct_Warn 2;
BA_ "InvalidValue" SG_ 1413 Ssadl_DoorAjar_Warn "3";
BA_ "GenSigTimeoutTime" SG_ 1413 Ssadl_DoorAjar_Warn 10000;
BA_ "GenSigStartValue" SG_ 1413 Ssadl_DoorAjar_Warn 3;
BA_ "GenSigSendType" SG_ 1413 Ssadl_DoorAjar_Warn 2;
BA_ "InvalidValue" SG_ 1413 Ccs_SrvWarn "3";
BA_ "GenSigTimeoutTime" SG_ 1413 Ccs_SrvWarn 10000;
BA_ "GenSigStartValue" SG_ 1413 Ccs_SrvWarn 3;
BA_ "GenSigSendType" SG_ 1413 Ccs_SrvWarn 2;
BA_ "GenSigTimeoutTime" SG_ 1424 CRC_ACM_Warning 10000;
BA_ "GenSigStartValue" SG_ 1424 CRC_ACM_Warning 255;
BA_ "InvalidValue" SG_ 1424 AlvCtr_ACM_Warning "15";
BA_ "GenSigTimeoutTime" SG_ 1424 AlvCtr_ACM_Warning 10000;
BA_ "GenSigStartValue" SG_ 1424 AlvCtr_ACM_Warning 15;
BA_ "InvalidValue" SG_ 1424 SbltWarn_BlinkingRmnReq "7";
BA_ "GenSigTimeoutTime" SG_ 1424 SbltWarn_BlinkingRmnReq 10000;
BA_ "GenSigSendType" SG_ 1424 SbltWarn_BlinkingRmnReq 2;
BA_ "InvalidValue" SG_ 1424 AirBg_WarnLamp "3";
BA_ "GenSigTimeoutTime" SG_ 1424 AirBg_WarnLamp 10000;
BA_ "GenSigSendType" SG_ 1424 AirBg_WarnLamp 2;
BA_ "InvalidValue" SG_ 1424 AirBg_PassAirbgDeac_Warn "3";
BA_ "GenSigTimeoutTime" SG_ 1424 AirBg_PassAirbgDeac_Warn 10000;
BA_ "GenSigSendType" SG_ 1424 AirBg_PassAirbgDeac_Warn 2;
BA_ "InvalidValue" SG_ 1424 SbltWarn_DrvrIndcrSts "3";
BA_ "GenSigTimeoutTime" SG_ 1424 SbltWarn_DrvrIndcrSts 10000;
BA_ "GenSigStartValue" SG_ 1424 SbltWarn_DrvrIndcrSts 3;
BA_ "GenSigSendType" SG_ 1424 SbltWarn_DrvrIndcrSts 2;
BA_ "InvalidValue" SG_ 1424 SbltWarn_PassIndcrSts "3";
BA_ "GenSigTimeoutTime" SG_ 1424 SbltWarn_PassIndcrSts 10000;
BA_ "GenSigStartValue" SG_ 1424 SbltWarn_PassIndcrSts 3;
BA_ "GenSigSendType" SG_ 1424 SbltWarn_PassIndcrSts 2;
BA_ "InvalidValue" SG_ 1424 SbltWarn_ReCentrIndcrSts "3";
BA_ "GenSigTimeoutTime" SG_ 1424 SbltWarn_ReCentrIndcrSts 10000;
BA_ "GenSigStartValue" SG_ 1424 SbltWarn_ReCentrIndcrSts 3;
BA_ "GenSigSendType" SG_ 1424 SbltWarn_ReCentrIndcrSts 2;
BA_ "InvalidValue" SG_ 1424 SbltWarn_ReRiIndcrSts "3";
BA_ "GenSigTimeoutTime" SG_ 1424 SbltWarn_ReRiIndcrSts 10000;
BA_ "GenSigStartValue" SG_ 1424 SbltWarn_ReRiIndcrSts 3;
BA_ "GenSigSendType" SG_ 1424 SbltWarn_ReRiIndcrSts 2;
BA_ "InvalidValue" SG_ 1424 SbltWarn_ReLeIndcrSts "3";
BA_ "GenSigTimeoutTime" SG_ 1424 SbltWarn_ReLeIndcrSts 10000;
BA_ "GenSigStartValue" SG_ 1424 SbltWarn_ReLeIndcrSts 3;
BA_ "GenSigSendType" SG_ 1424 SbltWarn_ReLeIndcrSts 2;
BA_ "InvalidValue" SG_ 1424 SbltWarn_DrvrBklSts "3";
BA_ "GenSigTimeoutTime" SG_ 1424 SbltWarn_DrvrBklSts 10000;
BA_ "GenSigStartValue" SG_ 1424 SbltWarn_DrvrBklSts 3;
BA_ "GenSigSendType" SG_ 1424 SbltWarn_DrvrBklSts 2;
BA_ "InvalidValue" SG_ 1424 SbltWarn_PassBklSts "3";
BA_ "GenSigTimeoutTime" SG_ 1424 SbltWarn_PassBklSts 10000;
BA_ "GenSigStartValue" SG_ 1424 SbltWarn_PassBklSts 3;
BA_ "GenSigSendType" SG_ 1424 SbltWarn_PassBklSts 2;
BA_ "InvalidValue" SG_ 1424 SbltWarn_ReCentrBklSts "3";
BA_ "GenSigTimeoutTime" SG_ 1424 SbltWarn_ReCentrBklSts 10000;
BA_ "GenSigStartValue" SG_ 1424 SbltWarn_ReCentrBklSts 3;
BA_ "GenSigSendType" SG_ 1424 SbltWarn_ReCentrBklSts 2;
BA_ "InvalidValue" SG_ 1424 SbltWarn_ReRiBklSts "3";
BA_ "GenSigTimeoutTime" SG_ 1424 SbltWarn_ReRiBklSts 10000;
BA_ "GenSigStartValue" SG_ 1424 SbltWarn_ReRiBklSts 3;
BA_ "GenSigSendType" SG_ 1424 SbltWarn_ReRiBklSts 2;
BA_ "InvalidValue" SG_ 1424 SbltWarn_ReLeBklSts "3";
BA_ "GenSigTimeoutTime" SG_ 1424 SbltWarn_ReLeBklSts 10000;
BA_ "GenSigStartValue" SG_ 1424 SbltWarn_ReLeBklSts 3;
BA_ "GenSigSendType" SG_ 1424 SbltWarn_ReLeBklSts 2;
BA_ "InvalidValue" SG_ 1424 SbltWarn_ChimeRmnReq "3";
BA_ "GenSigTimeoutTime" SG_ 1424 SbltWarn_ChimeRmnReq 10000;
BA_ "GenSigSendType" SG_ 1424 SbltWarn_ChimeRmnReq 2;
BA_ "GenSigTimeoutTime" SG_ 1425 CRC_DCMRL_Warning 10000;
BA_ "GenSigStartValue" SG_ 1425 CRC_DCMRL_Warning 255;
BA_ "InvalidValue" SG_ 1425 AlvCtr_DCMRL_Warning "15";
BA_ "GenSigTimeoutTime" SG_ 1425 AlvCtr_DCMRL_Warning 10000;
BA_ "GenSigStartValue" SG_ 1425 AlvCtr_DCMRL_Warning 15;
BA_ "InvalidValue" SG_ 1425 Pwind_ReLeWndw_Warn "3";
BA_ "GenSigTimeoutTime" SG_ 1425 Pwind_ReLeWndw_Warn 10000;
BA_ "GenSigStartValue" SG_ 1425 Pwind_ReLeWndw_Warn 3;
BA_ "GenSigSendType" SG_ 1425 Pwind_ReLeWndw_Warn 2;
BA_ "GenSigTimeoutTime" SG_ 1426 CRC_DCMRR_Warning 10000;
BA_ "GenSigStartValue" SG_ 1426 CRC_DCMRR_Warning 255;
BA_ "InvalidValue" SG_ 1426 AlvCtr_DCMRR_Warning "15";
BA_ "GenSigTimeoutTime" SG_ 1426 AlvCtr_DCMRR_Warning 10000;
BA_ "GenSigStartValue" SG_ 1426 AlvCtr_DCMRR_Warning 15;
BA_ "InvalidValue" SG_ 1426 CenLock_ReRiDoorAjar_Warn "3";
BA_ "GenSigTimeoutTime" SG_ 1426 CenLock_ReRiDoorAjar_Warn 10000;
BA_ "GenSigStartValue" SG_ 1426 CenLock_ReRiDoorAjar_Warn 3;
BA_ "GenSigSendType" SG_ 1426 CenLock_ReRiDoorAjar_Warn 2;
BA_ "InvalidValue" SG_ 1426 Pwind_ReRiWndw_Warn "3";
BA_ "GenSigTimeoutTime" SG_ 1426 Pwind_ReRiWndw_Warn 10000;
BA_ "GenSigStartValue" SG_ 1426 Pwind_ReRiWndw_Warn 3;
BA_ "GenSigSendType" SG_ 1426 Pwind_ReRiWndw_Warn 2;
BA_ "GenSigTimeoutTime" SG_ 1427 CRC_ASU_Warning 10000;
BA_ "GenSigStartValue" SG_ 1427 CRC_ASU_Warning 65535;
BA_ "GenSigTimeoutTime" SG_ 1427 AlvCtr_ASU_Warning 10000;
BA_ "GenSigStartValue" SG_ 1427 AlvCtr_ASU_Warning 255;
BA_ "InvalidValue" SG_ 1427 AirSuspUnit_Warn "3";
BA_ "GenSigTimeoutTime" SG_ 1427 AirSuspUnit_Warn 10000;
BA_ "GenSigSendType" SG_ 1427 AirSuspUnit_Warn 2;
BA_ "InvalidValue" SG_ 1427 AirSuspUnit_SrvModeNotActvdWarn "3";
BA_ "GenSigTimeoutTime" SG_ 1427 AirSuspUnit_SrvModeNotActvdWarn 10000;
BA_ "GenSigSendType" SG_ 1427 AirSuspUnit_SrvModeNotActvdWarn 2;
BA_ "GenSigTimeoutTime" SG_ 1428 CRC_DCMP_Warning 10000;
BA_ "GenSigStartValue" SG_ 1428 CRC_DCMP_Warning 255;
BA_ "InvalidValue" SG_ 1428 AlvCtr_DCMP_Warning "15";
BA_ "GenSigTimeoutTime" SG_ 1428 AlvCtr_DCMP_Warning 10000;
BA_ "GenSigStartValue" SG_ 1428 AlvCtr_DCMP_Warning 15;
BA_ "InvalidValue" SG_ 1428 CenLock_PassDoorAjar_Warn "3";
BA_ "GenSigTimeoutTime" SG_ 1428 CenLock_PassDoorAjar_Warn 10000;
BA_ "GenSigStartValue" SG_ 1428 CenLock_PassDoorAjar_Warn 3;
BA_ "GenSigSendType" SG_ 1428 CenLock_PassDoorAjar_Warn 2;
BA_ "InvalidValue" SG_ 1428 Pwind_PassWndw_Warn "3";
BA_ "GenSigTimeoutTime" SG_ 1428 Pwind_PassWndw_Warn 10000;
BA_ "GenSigStartValue" SG_ 1428 Pwind_PassWndw_Warn 3;
BA_ "GenSigSendType" SG_ 1428 Pwind_PassWndw_Warn 2;
BA_ "GenSigTimeoutTime" SG_ 1429 CRC_BMS_Warning 10000;
BA_ "GenSigStartValue" SG_ 1429 CRC_BMS_Warning 65535;
BA_ "GenSigTimeoutTime" SG_ 1429 AlvCtr_BMS_Warning 10000;
BA_ "GenSigStartValue" SG_ 1429 AlvCtr_BMS_Warning 255;
BA_ "InvalidValue" SG_ 1429 Bms_CellUDifErrWarn "3";
BA_ "GenSigTimeoutTime" SG_ 1429 Bms_CellUDifErrWarn 10000;
BA_ "GenSigSendType" SG_ 1429 Bms_CellUDifErrWarn 2;
BA_ "InvalidValue" SG_ 1429 Bms_CooltInletTSnsrFltWarn "3";
BA_ "GenSigTimeoutTime" SG_ 1429 Bms_CooltInletTSnsrFltWarn 10000;
BA_ "GenSigSendType" SG_ 1429 Bms_CooltInletTSnsrFltWarn 2;
BA_ "InvalidValue" SG_ 1429 Bms_CooltOutlTSnsrFltWarn "3";
BA_ "GenSigTimeoutTime" SG_ 1429 Bms_CooltOutlTSnsrFltWarn 10000;
BA_ "GenSigSendType" SG_ 1429 Bms_CooltOutlTSnsrFltWarn 2;
BA_ "InvalidValue" SG_ 1429 Bms_DCFCNegRlyErrWarn "3";
BA_ "GenSigTimeoutTime" SG_ 1429 Bms_DCFCNegRlyErrWarn 10000;
BA_ "GenSigSendType" SG_ 1429 Bms_DCFCNegRlyErrWarn 2;
BA_ "InvalidValue" SG_ 1429 Bms_DCFCPosRlyErrWarn "3";
BA_ "GenSigTimeoutTime" SG_ 1429 Bms_DCFCPosRlyErrWarn 10000;
BA_ "GenSigSendType" SG_ 1429 Bms_DCFCPosRlyErrWarn 2;
BA_ "InvalidValue" SG_ 1429 Bms_CtctrDcnctRsnWarn "3";
BA_ "GenSigTimeoutTime" SG_ 1429 Bms_CtctrDcnctRsnWarn 10000;
BA_ "GenSigSendType" SG_ 1429 Bms_CtctrDcnctRsnWarn 2;
BA_ "InvalidValue" SG_ 1429 Bms_ErrLevWarn "3";
BA_ "GenSigTimeoutTime" SG_ 1429 Bms_ErrLevWarn 10000;
BA_ "GenSigSendType" SG_ 1429 Bms_ErrLevWarn 2;
BA_ "InvalidValue" SG_ 1429 Bms_FuseStsErrWarn "3";
BA_ "GenSigTimeoutTime" SG_ 1429 Bms_FuseStsErrWarn 10000;
BA_ "GenSigSendType" SG_ 1429 Bms_FuseStsErrWarn 2;
BA_ "InvalidValue" SG_ 1429 Bms_HvilErrWarn "3";
BA_ "GenSigTimeoutTime" SG_ 1429 Bms_HvilErrWarn 10000;
BA_ "InvalidValue" SG_ 1429 Bms_LoBatWarn "3";
BA_ "GenSigTimeoutTime" SG_ 1429 Bms_LoBatWarn 10000;
BA_ "GenSigSendType" SG_ 1429 Bms_LoBatWarn 2;
BA_ "InvalidValue" SG_ 1429 Bms_MainPosRlyErrWarn "3";
BA_ "GenSigTimeoutTime" SG_ 1429 Bms_MainPosRlyErrWarn 10000;
BA_ "GenSigSendType" SG_ 1429 Bms_MainPosRlyErrWarn 2;
BA_ "InvalidValue" SG_ 1429 Bms_PackHvErrWarn "3";
BA_ "GenSigTimeoutTime" SG_ 1429 Bms_PackHvErrWarn 10000;
BA_ "GenSigSendType" SG_ 1429 Bms_PackHvErrWarn 2;
BA_ "InvalidValue" SG_ 1429 Bms_PackInsuErrWarn "3";
BA_ "GenSigTimeoutTime" SG_ 1429 Bms_PackInsuErrWarn 10000;
BA_ "GenSigSendType" SG_ 1429 Bms_PackInsuErrWarn 2;
BA_ "InvalidValue" SG_ 1429 Bms_PackLvErrWarn "3";
BA_ "GenSigTimeoutTime" SG_ 1429 Bms_PackLvErrWarn 10000;
BA_ "GenSigSendType" SG_ 1429 Bms_PackLvErrWarn 2;
BA_ "InvalidValue" SG_ 1429 Bms_PackOvcurErrWarn "3";
BA_ "GenSigTimeoutTime" SG_ 1429 Bms_PackOvcurErrWarn 10000;
BA_ "GenSigSendType" SG_ 1429 Bms_PackOvcurErrWarn 2;
BA_ "InvalidValue" SG_ 1429 Bms_PackTStsWarn "3";
BA_ "GenSigTimeoutTime" SG_ 1429 Bms_PackTStsWarn 10000;
BA_ "GenSigSendType" SG_ 1429 Bms_PackTStsWarn 2;
BA_ "InvalidValue" SG_ 1429 Bms_PreChRlyErrWarn "3";
BA_ "GenSigTimeoutTime" SG_ 1429 Bms_PreChRlyErrWarn 10000;
BA_ "GenSigSendType" SG_ 1429 Bms_PreChRlyErrWarn 2;
BA_ "InvalidValue" SG_ 1429 Bms_CellOverTErrWarn "3";
BA_ "GenSigTimeoutTime" SG_ 1429 Bms_CellOverTErrWarn 10000;
BA_ "GenSigSendType" SG_ 1429 Bms_CellOverTErrWarn 2;
BA_ "InvalidValue" SG_ 1429 Bms_CellUnderTErrWarn "3";
BA_ "GenSigTimeoutTime" SG_ 1429 Bms_CellUnderTErrWarn 10000;
BA_ "GenSigSendType" SG_ 1429 Bms_CellUnderTErrWarn 2;
BA_ "InvalidValue" SG_ 1429 Bms_RvsIDetChgFltWarn "3";
BA_ "GenSigTimeoutTime" SG_ 1429 Bms_RvsIDetChgFltWarn 10000;
BA_ "GenSigSendType" SG_ 1429 Bms_RvsIDetChgFltWarn 2;
BA_ "InvalidValue" SG_ 1429 Bms_ScIFltWarn "3";
BA_ "GenSigTimeoutTime" SG_ 1429 Bms_ScIFltWarn 10000;
BA_ "GenSigSendType" SG_ 1429 Bms_ScIFltWarn 2;
BA_ "InvalidValue" SG_ 1429 Bms_SocChngFastFltWarn "3";
BA_ "GenSigTimeoutTime" SG_ 1429 Bms_SocChngFastFltWarn 10000;
BA_ "GenSigSendType" SG_ 1429 Bms_SocChngFastFltWarn 2;
BA_ "InvalidValue" SG_ 1429 Bms_SrvDueDetnWarn "3";
BA_ "GenSigTimeoutTime" SG_ 1429 Bms_SrvDueDetnWarn 10000;
BA_ "GenSigSendType" SG_ 1429 Bms_SrvDueDetnWarn 2;
BA_ "InvalidValue" SG_ 1429 Bms_ThermRunawayWarn "3";
BA_ "GenSigTimeoutTime" SG_ 1429 Bms_ThermRunawayWarn 10000;
BA_ "GenSigSendType" SG_ 1429 Bms_ThermRunawayWarn 2;
BA_ "InvalidValue" SG_ 1429 Bms_TotNegRlyErrWarn "3";
BA_ "GenSigTimeoutTime" SG_ 1429 Bms_TotNegRlyErrWarn 10000;
BA_ "GenSigSendType" SG_ 1429 Bms_TotNegRlyErrWarn 2;
BA_ "InvalidValue" SG_ 1429 Bms_BatBalErrWarn "3";
BA_ "GenSigTimeoutTime" SG_ 1429 Bms_BatBalErrWarn 10000;
BA_ "GenSigSendType" SG_ 1429 Bms_BatBalErrWarn 2;
BA_ "InvalidValue" SG_ 1429 Bms_BatReplWarn "3";
BA_ "GenSigTimeoutTime" SG_ 1429 Bms_BatReplWarn 10000;
BA_ "GenSigSendType" SG_ 1429 Bms_BatReplWarn 2;
BA_ "InvalidValue" SG_ 1429 Bms_CellHvErrWarn "3";
BA_ "GenSigTimeoutTime" SG_ 1429 Bms_CellHvErrWarn 10000;
BA_ "GenSigSendType" SG_ 1429 Bms_CellHvErrWarn 2;
BA_ "InvalidValue" SG_ 1429 Bms_CellLvErrWarn "3";
BA_ "GenSigTimeoutTime" SG_ 1429 Bms_CellLvErrWarn 10000;
BA_ "GenSigSendType" SG_ 1429 Bms_CellLvErrWarn 2;
BA_ "GenSigTimeoutTime" SG_ 1430 CRC_DCMD_Warning 10000;
BA_ "GenSigStartValue" SG_ 1430 CRC_DCMD_Warning 255;
BA_ "InvalidValue" SG_ 1430 AlvCtr_DCMD_Warning "15";
BA_ "GenSigTimeoutTime" SG_ 1430 AlvCtr_DCMD_Warning 10000;
BA_ "GenSigStartValue" SG_ 1430 AlvCtr_DCMD_Warning 15;
BA_ "InvalidValue" SG_ 1430 Pwind_DrvWndw_Warn "3";
BA_ "GenSigTimeoutTime" SG_ 1430 Pwind_DrvWndw_Warn 10000;
BA_ "GenSigStartValue" SG_ 1430 Pwind_DrvWndw_Warn 3;
BA_ "GenSigSendType" SG_ 1430 Pwind_DrvWndw_Warn 2;
BA_ "InvalidValue" SG_ 1430 CenLock_DrvrDoorAjar_Warn "3";
BA_ "GenSigTimeoutTime" SG_ 1430 CenLock_DrvrDoorAjar_Warn 10000;
BA_ "GenSigStartValue" SG_ 1430 CenLock_DrvrDoorAjar_Warn 3;
BA_ "GenSigSendType" SG_ 1430 CenLock_DrvrDoorAjar_Warn 2;
BA_ "InvalidValue" SG_ 1430 Pwd_DrvrDoor_Warn "3";
BA_ "GenSigTimeoutTime" SG_ 1430 Pwd_DrvrDoor_Warn 10000;
BA_ "GenSigStartValue" SG_ 1430 Pwd_DrvrDoor_Warn 3;
BA_ "GenSigSendType" SG_ 1430 Pwd_DrvrDoor_Warn 2;
BA_ "GenSigTimeoutTime" SG_ 1432 CRC_EBCM_Warning 10000;
BA_ "GenSigStartValue" SG_ 1432 CRC_EBCM_Warning 65535;
BA_ "GenSigTimeoutTime" SG_ 1432 AlvCtr_EBCM_Warning 10000;
BA_ "GenSigStartValue" SG_ 1432 AlvCtr_EBCM_Warning 255;
BA_ "InvalidValue" SG_ 1432 Ecpbk_SwtFlt "3";
BA_ "GenSigTimeoutTime" SG_ 1432 Ecpbk_SwtFlt 10000;
BA_ "GenSigSendType" SG_ 1432 Ecpbk_SwtFlt 2;
BA_ "InvalidValue" SG_ 1432 Ecpbk_InclndVehParkWarn "3";
BA_ "GenSigTimeoutTime" SG_ 1432 Ecpbk_InclndVehParkWarn 10000;
BA_ "GenSigSendType" SG_ 1432 Ecpbk_InclndVehParkWarn 2;
BA_ "InvalidValue" SG_ 1432 Ecpbk_BrkFNotEnWarn "3";
BA_ "GenSigTimeoutTime" SG_ 1432 Ecpbk_BrkFNotEnWarn 10000;
BA_ "GenSigSendType" SG_ 1432 Ecpbk_BrkFNotEnWarn 2;
BA_ "InvalidValue" SG_ 1432 Brb_RgnWarn "3";
BA_ "GenSigTimeoutTime" SG_ 1432 Brb_RgnWarn 10000;
BA_ "GenSigStartValue" SG_ 1432 Brb_RgnWarn 3;
BA_ "InvalidValue" SG_ 1432 Ecpbk_NotAppldDoorOpenWarn "3";
BA_ "GenSigTimeoutTime" SG_ 1432 Ecpbk_NotAppldDoorOpenWarn 10000;
BA_ "GenSigSendType" SG_ 1432 Ecpbk_NotAppldDoorOpenWarn 2;
BA_ "InvalidValue" SG_ 1432 Ecpbk_RollrBenchModeWarn "3";
BA_ "GenSigTimeoutTime" SG_ 1432 Ecpbk_RollrBenchModeWarn 10000;
BA_ "GenSigSendType" SG_ 1432 Ecpbk_RollrBenchModeWarn 2;
BA_ "InvalidValue" SG_ 1432 Ecpbk_AutoRelsWarn "3";
BA_ "GenSigTimeoutTime" SG_ 1432 Ecpbk_AutoRelsWarn 10000;
BA_ "GenSigSendType" SG_ 1432 Ecpbk_AutoRelsWarn 2;
BA_ "InvalidValue" SG_ 1432 Ecpbk_RlsdMntnModeWarn "3";
BA_ "GenSigTimeoutTime" SG_ 1432 Ecpbk_RlsdMntnModeWarn 10000;
BA_ "GenSigSendType" SG_ 1432 Ecpbk_RlsdMntnModeWarn 2;
BA_ "InvalidValue" SG_ 1432 Ecpbk_RlsdTwModeWarn "3";
BA_ "GenSigTimeoutTime" SG_ 1432 Ecpbk_RlsdTwModeWarn 10000;
BA_ "GenSigSendType" SG_ 1432 Ecpbk_RlsdTwModeWarn 2;
BA_ "InvalidValue" SG_ 1432 Ecpbk_AutoAppldWarn "3";
BA_ "GenSigTimeoutTime" SG_ 1432 Ecpbk_AutoAppldWarn 10000;
BA_ "GenSigSendType" SG_ 1432 Ecpbk_AutoAppldWarn 2;
BA_ "InvalidValue" SG_ 1432 Drvac_HillStrtAssiFltWarn "3";
BA_ "GenSigTimeoutTime" SG_ 1432 Drvac_HillStrtAssiFltWarn 10000;
BA_ "GenSigSendType" SG_ 1432 Drvac_HillStrtAssiFltWarn 2;
BA_ "InvalidValue" SG_ 1432 Ebd_SysWarn "3";
BA_ "GenSigTimeoutTime" SG_ 1432 Ebd_SysWarn 10000;
BA_ "GenSigStartValue" SG_ 1432 Ebd_SysWarn 3;
BA_ "GenSigSendType" SG_ 1432 Ebd_SysWarn 2;
BA_ "InvalidValue" SG_ 1432 Drvac_CorneringBrkCtlFltWarn "3";
BA_ "GenSigTimeoutTime" SG_ 1432 Drvac_CorneringBrkCtlFltWarn 10000;
BA_ "GenSigSendType" SG_ 1432 Drvac_CorneringBrkCtlFltWarn 2;
BA_ "InvalidValue" SG_ 1432 Drvac_HdcWarn "3";
BA_ "GenSigTimeoutTime" SG_ 1432 Drvac_HdcWarn 10000;
BA_ "GenSigSendType" SG_ 1432 Drvac_HdcWarn 2;
BA_ "InvalidValue" SG_ 1432 Drvac_FldLvlIndcrBrkFldWarn "3";
BA_ "GenSigTimeoutTime" SG_ 1432 Drvac_FldLvlIndcrBrkFldWarn 10000;
BA_ "GenSigSendType" SG_ 1432 Drvac_FldLvlIndcrBrkFldWarn 2;
BA_ "InvalidValue" SG_ 1432 Drvac_TcsWarn "3";
BA_ "GenSigTimeoutTime" SG_ 1432 Drvac_TcsWarn 10000;
BA_ "GenSigSendType" SG_ 1432 Drvac_TcsWarn 2;
BA_ "InvalidValue" SG_ 1432 Ecpbk_PsdBrkPedlToRelsEpbWarn "3";
BA_ "GenSigTimeoutTime" SG_ 1432 Ecpbk_PsdBrkPedlToRelsEpbWarn 10000;
BA_ "InvalidValue" SG_ 1432 Ecpbk_WarnLampSt "3";
BA_ "GenSigTimeoutTime" SG_ 1432 Ecpbk_WarnLampSt 10000;
BA_ "InvalidValue" SG_ 1432 Ecpbk_ParkBrkFltWarn "3";
BA_ "GenSigTimeoutTime" SG_ 1432 Ecpbk_ParkBrkFltWarn 10000;
BA_ "InvalidValue" SG_ 1432 Ecpbk_DegradedModeToBeRlsdWarn "3";
BA_ "GenSigTimeoutTime" SG_ 1432 Ecpbk_DegradedModeToBeRlsdWarn 10000;
BA_ "InvalidValue" SG_ 1432 Ecpbk_DegradedModeRlsdWarn "3";
BA_ "GenSigTimeoutTime" SG_ 1432 Ecpbk_DegradedModeRlsdWarn 10000;
BA_ "GenSigSendType" SG_ 1432 Ecpbk_DegradedModeRlsdWarn 2;
BA_ "InvalidValue" SG_ 1432 Abs_FltWarn "3";
BA_ "GenSigTimeoutTime" SG_ 1432 Abs_FltWarn 10000;
BA_ "GenSigSendType" SG_ 1432 Abs_FltWarn 2;
BA_ "GenSigTimeoutTime" SG_ 1434 CRC_OBC_Warning 10000;
BA_ "GenSigStartValue" SG_ 1434 CRC_OBC_Warning 65535;
BA_ "GenSigTimeoutTime" SG_ 1434 AlvCtr_OBC_Warning 10000;
BA_ "GenSigStartValue" SG_ 1434 AlvCtr_OBC_Warning 255;
BA_ "InvalidValue" SG_ 1434 Acchg_ObcErrWarn "3";
BA_ "GenSigTimeoutTime" SG_ 1434 Acchg_ObcErrWarn 10000;
BA_ "GenSigSendType" SG_ 1434 Acchg_ObcErrWarn 2;
BA_ "GenSigTimeoutTime" SG_ 1436 CRC_EPS_RWA1_Warning 10000;
BA_ "GenSigTimeoutTime" SG_ 1436 AlvCtr_EPS_RWA1_Warning 10000;
BA_ "InvalidValue" SG_ 1436 Stbwr_RdndtModeWarn "3";
BA_ "GenSigTimeoutTime" SG_ 1436 Stbwr_RdndtModeWarn 10000;
BA_ "GenSigSendType" SG_ 1436 Stbwr_RdndtModeWarn 2;
BA_ "GenSigTimeoutTime" SG_ 1437 CRC_EPS_SFA1_Warning 10000;
BA_ "GenSigTimeoutTime" SG_ 1437 AlvCtr_EPS_SFA1_Warning 10000;
BA_ "InvalidValue" SG_ 1437 Stbwr_HptcWarnSts "3";
BA_ "GenSigTimeoutTime" SG_ 1437 Stbwr_HptcWarnSts 10000;
BA_ "GenSigStartValue" SG_ 1437 Stbwr_HptcWarnSts 3;
BA_ "GenSigSendType" SG_ 1437 Stbwr_HptcWarnSts 2;
BA_ "InvalidValue" SG_ 1437 Stbwr_SfaCluWarnLamp "3";
BA_ "GenSigTimeoutTime" SG_ 1437 Stbwr_SfaCluWarnLamp 10000;
BA_ "GenSigSendType" SG_ 1437 Stbwr_SfaCluWarnLamp 2;
BA_ "InvalidValue" SG_ 1437 Stbwr_SteerAlgnmtWarn "3";
BA_ "GenSigTimeoutTime" SG_ 1437 Stbwr_SteerAlgnmtWarn 10000;
BA_ "GenSigSendType" SG_ 1437 Stbwr_SteerAlgnmtWarn 2;
BA_ "GenSigTimeoutTime" SG_ 1438 CRC_EPS_RWA2_Warning 10000;
BA_ "GenSigTimeoutTime" SG_ 1438 AlvCtr_EPS_RWA2_Warning 10000;
BA_ "InvalidValue" SG_ 1438 Stbwr_RdndtModeWarn_R "3";
BA_ "GenSigTimeoutTime" SG_ 1438 Stbwr_RdndtModeWarn_R 10000;
BA_ "GenSigSendType" SG_ 1438 Stbwr_RdndtModeWarn_R 2;
BA_ "GenSigTimeoutTime" SG_ 1439 CRC_EPS_SFA2_Warning 10000;
BA_ "GenSigTimeoutTime" SG_ 1439 AlvCtr_EPS_SFA2_Warning 10000;
BA_ "InvalidValue" SG_ 1439 Stbwr_HptcWarnSts_R "3";
BA_ "GenSigTimeoutTime" SG_ 1439 Stbwr_HptcWarnSts_R 10000;
BA_ "GenSigStartValue" SG_ 1439 Stbwr_HptcWarnSts_R 3;
BA_ "GenSigSendType" SG_ 1439 Stbwr_HptcWarnSts_R 2;
BA_ "InvalidValue" SG_ 1439 Stbwr_SfaCluWarnLamp_R "3";
BA_ "GenSigTimeoutTime" SG_ 1439 Stbwr_SfaCluWarnLamp_R 10000;
BA_ "GenSigSendType" SG_ 1439 Stbwr_SfaCluWarnLamp_R 2;
BA_ "InvalidValue" SG_ 1439 Stbwr_SteerAlgnmtWarn_R "3";
BA_ "GenSigTimeoutTime" SG_ 1439 Stbwr_SteerAlgnmtWarn_R 10000;
BA_ "GenSigSendType" SG_ 1439 Stbwr_SteerAlgnmtWarn_R 2;
BA_ "GenSigTimeoutTime" SG_ 1445 CRC_HDLML_Warning 10000;
BA_ "GenSigStartValue" SG_ 1445 CRC_HDLML_Warning 65535;
BA_ "GenSigTimeoutTime" SG_ 1445 AlvCtr_HDLML_Warning 10000;
BA_ "GenSigStartValue" SG_ 1445 AlvCtr_HDLML_Warning 255;
BA_ "InvalidValue" SG_ 1445 Hdlamp_LeLoBeamLampWarn "3";
BA_ "GenSigTimeoutTime" SG_ 1445 Hdlamp_LeLoBeamLampWarn 10000;
BA_ "GenSigStartValue" SG_ 1445 Hdlamp_LeLoBeamLampWarn 3;
BA_ "GenSigSendType" SG_ 1445 Hdlamp_LeLoBeamLampWarn 2;
BA_ "InvalidValue" SG_ 1445 Hdlamp_LeHiBeamLampWarn "3";
BA_ "GenSigTimeoutTime" SG_ 1445 Hdlamp_LeHiBeamLampWarn 10000;
BA_ "GenSigStartValue" SG_ 1445 Hdlamp_LeHiBeamLampWarn 3;
BA_ "GenSigSendType" SG_ 1445 Hdlamp_LeHiBeamLampWarn 2;
BA_ "GenSigTimeoutTime" SG_ 1446 CRC_HDLMR_Warning 10000;
BA_ "GenSigStartValue" SG_ 1446 CRC_HDLMR_Warning 65535;
BA_ "GenSigTimeoutTime" SG_ 1446 AlvCtr_HDLMR_Warning 10000;
BA_ "GenSigStartValue" SG_ 1446 AlvCtr_HDLMR_Warning 255;
BA_ "InvalidValue" SG_ 1446 Hdlamp_RiLoBeamLampWarn "3";
BA_ "GenSigTimeoutTime" SG_ 1446 Hdlamp_RiLoBeamLampWarn 10000;
BA_ "GenSigStartValue" SG_ 1446 Hdlamp_RiLoBeamLampWarn 3;
BA_ "GenSigSendType" SG_ 1446 Hdlamp_RiLoBeamLampWarn 2;
BA_ "InvalidValue" SG_ 1446 Hdlamp_RiHiBeamLamp_Warn "3";
BA_ "GenSigTimeoutTime" SG_ 1446 Hdlamp_RiHiBeamLamp_Warn 10000;
BA_ "GenSigStartValue" SG_ 1446 Hdlamp_RiHiBeamLamp_Warn 3;
BA_ "GenSigSendType" SG_ 1446 Hdlamp_RiHiBeamLamp_Warn 2;
BA_ "GenSigTimeoutTime" SG_ 1447 CRC_Sbm_Warning 10000;
BA_ "GenSigStartValue" SG_ 1447 CRC_Sbm_Warning 65535;
BA_ "GenSigTimeoutTime" SG_ 1447 AlvCtr_SBM_Warning 10000;
BA_ "GenSigStartValue" SG_ 1447 AlvCtr_SBM_Warning 255;
BA_ "InvalidValue" SG_ 1447 Sbm_CriticalSoCAlert_Warn "3";
BA_ "GenSigTimeoutTime" SG_ 1447 Sbm_CriticalSoCAlert_Warn 10000;
BA_ "GenSigSendType" SG_ 1447 Sbm_CriticalSoCAlert_Warn 2;
BA_ "InvalidValue" SG_ 1447 Sbm_HealthStWarn "3";
BA_ "GenSigTimeoutTime" SG_ 1447 Sbm_HealthStWarn 10000;
BA_ "GenSigSendType" SG_ 1447 Sbm_HealthStWarn 2;
BA_ "InvalidValue" SG_ 1447 Sbm_LvBatTSnsrFltSts_Warn "3";
BA_ "GenSigTimeoutTime" SG_ 1447 Sbm_LvBatTSnsrFltSts_Warn 10000;
BA_ "GenSigSendType" SG_ 1447 Sbm_LvBatTSnsrFltSts_Warn 2;
BA_ "GenSigTimeoutTime" SG_ 1448 CRC_CCU_Warning 10000;
BA_ "GenSigStartValue" SG_ 1448 CRC_CCU_Warning 255;
BA_ "InvalidValue" SG_ 1448 AlvCtr_CCU_Warning "15";
BA_ "GenSigTimeoutTime" SG_ 1448 AlvCtr_CCU_Warning 10000;
BA_ "GenSigStartValue" SG_ 1448 AlvCtr_CCU_Warning 15;
BA_ "InvalidValue" SG_ 1448 Ccsf_IoniserFlt_Warn "3";
BA_ "GenSigTimeoutTime" SG_ 1448 Ccsf_IoniserFlt_Warn 10000;
BA_ "GenSigStartValue" SG_ 1448 Ccsf_IoniserFlt_Warn 3;
BA_ "GenSigSendType" SG_ 1448 Ccsf_IoniserFlt_Warn 2;
BA_ "InvalidValue" SG_ 1448 Ccsf_FrntLeDuctFlapFlt_Warn "3";
BA_ "GenSigTimeoutTime" SG_ 1448 Ccsf_FrntLeDuctFlapFlt_Warn 10000;
BA_ "GenSigStartValue" SG_ 1448 Ccsf_FrntLeDuctFlapFlt_Warn 3;
BA_ "GenSigSendType" SG_ 1448 Ccsf_FrntLeDuctFlapFlt_Warn 2;
BA_ "InvalidValue" SG_ 1448 Ccsf_ReRiTempMixFlapFlt_Warn "3";
BA_ "GenSigTimeoutTime" SG_ 1448 Ccsf_ReRiTempMixFlapFlt_Warn 10000;
BA_ "GenSigStartValue" SG_ 1448 Ccsf_ReRiTempMixFlapFlt_Warn 3;
BA_ "GenSigSendType" SG_ 1448 Ccsf_ReRiTempMixFlapFlt_Warn 2;
BA_ "InvalidValue" SG_ 1448 Ccsf_ReLeTempMixFlapFlt_Warn "3";
BA_ "GenSigTimeoutTime" SG_ 1448 Ccsf_ReLeTempMixFlapFlt_Warn 10000;
BA_ "GenSigStartValue" SG_ 1448 Ccsf_ReLeTempMixFlapFlt_Warn 3;
BA_ "GenSigSendType" SG_ 1448 Ccsf_ReLeTempMixFlapFlt_Warn 2;
BA_ "InvalidValue" SG_ 1448 Ccsf_FrntLeTempMixFlapFlt_Warn "3";
BA_ "GenSigTimeoutTime" SG_ 1448 Ccsf_FrntLeTempMixFlapFlt_Warn 10000;
BA_ "GenSigStartValue" SG_ 1448 Ccsf_FrntLeTempMixFlapFlt_Warn 3;
BA_ "GenSigSendType" SG_ 1448 Ccsf_FrntLeTempMixFlapFlt_Warn 2;
BA_ "InvalidValue" SG_ 1448 Ccsf_ReLeVentDuctFlapFlt_Warn "3";
BA_ "GenSigTimeoutTime" SG_ 1448 Ccsf_ReLeVentDuctFlapFlt_Warn 10000;
BA_ "GenSigStartValue" SG_ 1448 Ccsf_ReLeVentDuctFlapFlt_Warn 3;
BA_ "GenSigSendType" SG_ 1448 Ccsf_ReLeVentDuctFlapFlt_Warn 2;
BA_ "InvalidValue" SG_ 1448 Ccsf_FrntRiDuctFlapFlt_Warn "3";
BA_ "GenSigTimeoutTime" SG_ 1448 Ccsf_FrntRiDuctFlapFlt_Warn 10000;
BA_ "GenSigStartValue" SG_ 1448 Ccsf_FrntRiDuctFlapFlt_Warn 3;
BA_ "GenSigSendType" SG_ 1448 Ccsf_FrntRiDuctFlapFlt_Warn 2;
BA_ "InvalidValue" SG_ 1448 Ccsf_ReLeFootDuctFlapFlt_Warn "3";
BA_ "GenSigTimeoutTime" SG_ 1448 Ccsf_ReLeFootDuctFlapFlt_Warn 10000;
BA_ "GenSigStartValue" SG_ 1448 Ccsf_ReLeFootDuctFlapFlt_Warn 3;
BA_ "GenSigSendType" SG_ 1448 Ccsf_ReLeFootDuctFlapFlt_Warn 2;
BA_ "InvalidValue" SG_ 1448 Ccsf_FrntLeVenDirSts "3";
BA_ "GenSigTimeoutTime" SG_ 1448 Ccsf_FrntLeVenDirSts 10000;
BA_ "GenSigStartValue" SG_ 1448 Ccsf_FrntLeVenDirSts 3;
BA_ "GenSigSendType" SG_ 1448 Ccsf_FrntLeVenDirSts 2;
BA_ "InvalidValue" SG_ 1448 Ccsf_FrntRiTempMixFlapFltW_Warn "3";
BA_ "GenSigTimeoutTime" SG_ 1448 Ccsf_FrntRiTempMixFlapFltW_Warn 10000;
BA_ "GenSigStartValue" SG_ 1448 Ccsf_FrntRiTempMixFlapFltW_Warn 3;
BA_ "GenSigSendType" SG_ 1448 Ccsf_FrntRiTempMixFlapFltW_Warn 2;
BA_ "GenSigTimeoutTime" SG_ 1452 CRC_MCU_F_Warning 10000;
BA_ "GenSigStartValue" SG_ 1452 CRC_MCU_F_Warning 65535;
BA_ "GenSigTimeoutTime" SG_ 1452 AlvCtr_MCU_F_Warning 10000;
BA_ "GenSigStartValue" SG_ 1452 AlvCtr_MCU_F_Warning 255;
BA_ "InvalidValue" SG_ 1452 Eds_FrntDeratWarn "3";
BA_ "GenSigTimeoutTime" SG_ 1452 Eds_FrntDeratWarn 10000;
BA_ "GenSigSendType" SG_ 1452 Eds_FrntDeratWarn 2;
BA_ "InvalidValue" SG_ 1452 Eds_FrntErWarn "3";
BA_ "GenSigTimeoutTime" SG_ 1452 Eds_FrntErWarn 10000;
BA_ "GenSigSendType" SG_ 1452 Eds_FrntErWarn 2;
BA_ "InvalidValue" SG_ 1452 Eds_FrntParkLockErrWarn "3";
BA_ "GenSigTimeoutTime" SG_ 1452 Eds_FrntParkLockErrWarn 10000;
BA_ "GenSigSendType" SG_ 1452 Eds_FrntParkLockErrWarn 2;
BA_ "GenSigTimeoutTime" SG_ 1453 CRC_MCU_R_Warning 10000;
BA_ "GenSigStartValue" SG_ 1453 CRC_MCU_R_Warning 65535;
BA_ "GenSigTimeoutTime" SG_ 1453 AlvCtr_MCU_R_Warning 10000;
BA_ "GenSigStartValue" SG_ 1453 AlvCtr_MCU_R_Warning 255;
BA_ "InvalidValue" SG_ 1453 Eds_ReParkLockErrWarn "3";
BA_ "GenSigTimeoutTime" SG_ 1453 Eds_ReParkLockErrWarn 10000;
BA_ "GenSigSendType" SG_ 1453 Eds_ReParkLockErrWarn 2;
BA_ "InvalidValue" SG_ 1453 Eds_ReErrWarn "3";
BA_ "GenSigTimeoutTime" SG_ 1453 Eds_ReErrWarn 10000;
BA_ "GenSigSendType" SG_ 1453 Eds_ReErrWarn 2;
BA_ "InvalidValue" SG_ 1453 Eds_ReDeratWarn "3";
BA_ "GenSigTimeoutTime" SG_ 1453 Eds_ReDeratWarn 10000;
BA_ "GenSigSendType" SG_ 1453 Eds_ReDeratWarn 2;
BA_ "GenSigTimeoutTime" SG_ 1454 CRC_MFS_Warning 10000;
BA_ "GenSigStartValue" SG_ 1454 CRC_MFS_Warning 255;
BA_ "InvalidValue" SG_ 1454 AlvCtr_MFS_Warning "15";
BA_ "GenSigTimeoutTime" SG_ 1454 AlvCtr_MFS_Warning 10000;
BA_ "GenSigStartValue" SG_ 1454 AlvCtr_MFS_Warning 15;
BA_ "InvalidValue" SG_ 1454 Mfsw_DrvModSwt_Warn "3";
BA_ "GenSigTimeoutTime" SG_ 1454 Mfsw_DrvModSwt_Warn 10000;
BA_ "GenSigStartValue" SG_ 1454 Mfsw_DrvModSwt_Warn 3;
BA_ "GenSigSendType" SG_ 1454 Mfsw_DrvModSwt_Warn 2;
BA_ "InvalidValue" SG_ 1454 MFS_ADAS_Swt_Warn "3";
BA_ "GenSigTimeoutTime" SG_ 1454 MFS_ADAS_Swt_Warn 10000;
BA_ "GenSigStartValue" SG_ 1454 MFS_ADAS_Swt_Warn 3;
BA_ "GenSigSendType" SG_ 1454 MFS_ADAS_Swt_Warn 2;
BA_ "InvalidValue" SG_ 1454 MFS_Favorite_Swt_Warn "3";
BA_ "GenSigTimeoutTime" SG_ 1454 MFS_Favorite_Swt_Warn 10000;
BA_ "GenSigStartValue" SG_ 1454 MFS_Favorite_Swt_Warn 3;
BA_ "GenSigSendType" SG_ 1454 MFS_Favorite_Swt_Warn 2;
BA_ "InvalidValue" SG_ 1454 MFS_Rim_Swt_Hi_Beam_Warn "3";
BA_ "GenSigTimeoutTime" SG_ 1454 MFS_Rim_Swt_Hi_Beam_Warn 10000;
BA_ "GenSigStartValue" SG_ 1454 MFS_Rim_Swt_Hi_Beam_Warn 3;
BA_ "GenSigSendType" SG_ 1454 MFS_Rim_Swt_Hi_Beam_Warn 2;
BA_ "InvalidValue" SG_ 1454 MFS_Rim_Swt_Wiper_Warn "3";
BA_ "GenSigTimeoutTime" SG_ 1454 MFS_Rim_Swt_Wiper_Warn 10000;
BA_ "GenSigStartValue" SG_ 1454 MFS_Rim_Swt_Wiper_Warn 3;
BA_ "GenSigSendType" SG_ 1454 MFS_Rim_Swt_Wiper_Warn 2;
BA_ "GenSigTimeoutTime" SG_ 1457 CRC_DCDC_Warning 10000;
BA_ "GenSigStartValue" SG_ 1457 CRC_DCDC_Warning 65535;
BA_ "GenSigTimeoutTime" SG_ 1457 AlvCtr_DCDC_Warning 10000;
BA_ "GenSigStartValue" SG_ 1457 AlvCtr_DCDC_Warning 255;
BA_ "InvalidValue" SG_ 1457 Hvsco_DcdcOperWarn "3";
BA_ "GenSigTimeoutTime" SG_ 1457 Hvsco_DcdcOperWarn 10000;
BA_ "GenSigSendType" SG_ 1457 Hvsco_DcdcOperWarn 2;
BA_ "GenSigTimeoutTime" SG_ 1459 CRC_PSMD_Warning 10000;
BA_ "GenSigStartValue" SG_ 1459 CRC_PSMD_Warning 255;
BA_ "InvalidValue" SG_ 1459 AlvCtr_PSMD_Warning "15";
BA_ "GenSigTimeoutTime" SG_ 1459 AlvCtr_PSMD_Warning 10000;
BA_ "GenSigStartValue" SG_ 1459 AlvCtr_PSMD_Warning 15;
BA_ "InvalidValue" SG_ 1459 SeatAdjmt_DrvFrntBackMotWarn "3";
BA_ "GenSigTimeoutTime" SG_ 1459 SeatAdjmt_DrvFrntBackMotWarn 10000;
BA_ "GenSigSendType" SG_ 1459 SeatAdjmt_DrvFrntBackMotWarn 2;
BA_ "InvalidValue" SG_ 1459 SeatCfmt_DrvHeatgBackPadFailWarn "3";
BA_ "GenSigTimeoutTime" SG_ 1459 SeatCfmt_DrvHeatgBackPadFailWarn 10000;
BA_ "GenSigSendType" SG_ 1459 SeatCfmt_DrvHeatgBackPadFailWarn 2;
BA_ "InvalidValue" SG_ 1459 SeatCfmt_DrvVentnSqubFanFailWarn "3";
BA_ "GenSigTimeoutTime" SG_ 1459 SeatCfmt_DrvVentnSqubFanFailWarn 10000;
BA_ "GenSigSendType" SG_ 1459 SeatCfmt_DrvVentnSqubFanFailWarn 2;
BA_ "InvalidValue" SG_ 1459 SeatAdjmt_DrvHeiUpDwnMotWarn "3";
BA_ "GenSigTimeoutTime" SG_ 1459 SeatAdjmt_DrvHeiUpDwnMotWarn 10000;
BA_ "GenSigSendType" SG_ 1459 SeatAdjmt_DrvHeiUpDwnMotWarn 2;
BA_ "InvalidValue" SG_ 1459 SeatAdjmt_DrvTiltUpDwnMotWarn "3";
BA_ "GenSigTimeoutTime" SG_ 1459 SeatAdjmt_DrvTiltUpDwnMotWarn 10000;
BA_ "GenSigSendType" SG_ 1459 SeatAdjmt_DrvTiltUpDwnMotWarn 2;
BA_ "InvalidValue" SG_ 1459 SeatCfmt_DrvVentnCshnFanFailWarn "3";
BA_ "GenSigTimeoutTime" SG_ 1459 SeatCfmt_DrvVentnCshnFanFailWarn 10000;
BA_ "GenSigSendType" SG_ 1459 SeatCfmt_DrvVentnCshnFanFailWarn 2;
BA_ "InvalidValue" SG_ 1459 SeatAdjmt_DrvAdjmtWarn "3";
BA_ "GenSigTimeoutTime" SG_ 1459 SeatAdjmt_DrvAdjmtWarn 10000;
BA_ "GenSigSendType" SG_ 1459 SeatAdjmt_DrvAdjmtWarn 2;
BA_ "InvalidValue" SG_ 1459 SeatAdjmt_DrvReclUpDwnMotWarn "3";
BA_ "GenSigTimeoutTime" SG_ 1459 SeatAdjmt_DrvReclUpDwnMotWarn 10000;
BA_ "GenSigSendType" SG_ 1459 SeatAdjmt_DrvReclUpDwnMotWarn 2;
BA_ "InvalidValue" SG_ 1459 SeatCfmt_DrvMassgFailWarn "3";
BA_ "GenSigTimeoutTime" SG_ 1459 SeatCfmt_DrvMassgFailWarn 10000;
BA_ "GenSigSendType" SG_ 1459 SeatCfmt_DrvMassgFailWarn 2;
BA_ "GenSigTimeoutTime" SG_ 1460 CRC_PSMP_Warning 10000;
BA_ "InvalidValue" SG_ 1460 AlvCtr_PSMP_Warning "15";
BA_ "GenSigTimeoutTime" SG_ 1460 AlvCtr_PSMP_Warning 10000;
BA_ "GenSigStartValue" SG_ 1460 AlvCtr_PSMP_Warning 15;
BA_ "InvalidValue" SG_ 1460 SeatAdjmt_PassTiltUpDwnMotWarn "3";
BA_ "GenSigTimeoutTime" SG_ 1460 SeatAdjmt_PassTiltUpDwnMotWarn 10000;
BA_ "GenSigStartValue" SG_ 1460 SeatAdjmt_PassTiltUpDwnMotWarn 3;
BA_ "GenSigSendType" SG_ 1460 SeatAdjmt_PassTiltUpDwnMotWarn 2;
BA_ "InvalidValue" SG_ 1460 SeatAdjmt_PassAdjmtWarn "3";
BA_ "GenSigTimeoutTime" SG_ 1460 SeatAdjmt_PassAdjmtWarn 10000;
BA_ "GenSigStartValue" SG_ 1460 SeatAdjmt_PassAdjmtWarn 3;
BA_ "GenSigSendType" SG_ 1460 SeatAdjmt_PassAdjmtWarn 2;
BA_ "InvalidValue" SG_ 1460 SeatCfmt_PassVentnCshnFanFailWrn "3";
BA_ "GenSigTimeoutTime" SG_ 1460 SeatCfmt_PassVentnCshnFanFailWrn 10000;
BA_ "GenSigStartValue" SG_ 1460 SeatCfmt_PassVentnCshnFanFailWrn 3;
BA_ "GenSigSendType" SG_ 1460 SeatCfmt_PassVentnCshnFanFailWrn 2;
BA_ "InvalidValue" SG_ 1460 SeatAdjmt_PassReclUpDwnMotWarn "3";
BA_ "GenSigTimeoutTime" SG_ 1460 SeatAdjmt_PassReclUpDwnMotWarn 10000;
BA_ "GenSigStartValue" SG_ 1460 SeatAdjmt_PassReclUpDwnMotWarn 3;
BA_ "GenSigSendType" SG_ 1460 SeatAdjmt_PassReclUpDwnMotWarn 2;
BA_ "InvalidValue" SG_ 1460 SeatAdjmt_PassHeiUpDwnMotWarn "3";
BA_ "GenSigTimeoutTime" SG_ 1460 SeatAdjmt_PassHeiUpDwnMotWarn 10000;
BA_ "GenSigStartValue" SG_ 1460 SeatAdjmt_PassHeiUpDwnMotWarn 3;
BA_ "GenSigSendType" SG_ 1460 SeatAdjmt_PassHeiUpDwnMotWarn 2;
BA_ "InvalidValue" SG_ 1460 SeatCfmt_PassVentnSqubFanFailWrn "3";
BA_ "GenSigTimeoutTime" SG_ 1460 SeatCfmt_PassVentnSqubFanFailWrn 10000;
BA_ "GenSigStartValue" SG_ 1460 SeatCfmt_PassVentnSqubFanFailWrn 3;
BA_ "GenSigSendType" SG_ 1460 SeatCfmt_PassVentnSqubFanFailWrn 2;
BA_ "InvalidValue" SG_ 1460 SeatCfmt_PassMassgFailWarn "3";
BA_ "GenSigTimeoutTime" SG_ 1460 SeatCfmt_PassMassgFailWarn 10000;
BA_ "GenSigStartValue" SG_ 1460 SeatCfmt_PassMassgFailWarn 3;
BA_ "GenSigSendType" SG_ 1460 SeatCfmt_PassMassgFailWarn 2;
BA_ "InvalidValue" SG_ 1460 SeatAdjmt_PassFowdBawdMotWarn "3";
BA_ "GenSigTimeoutTime" SG_ 1460 SeatAdjmt_PassFowdBawdMotWarn 10000;
BA_ "GenSigStartValue" SG_ 1460 SeatAdjmt_PassFowdBawdMotWarn 3;
BA_ "GenSigSendType" SG_ 1460 SeatAdjmt_PassFowdBawdMotWarn 2;
BA_ "GenSigTimeoutTime" SG_ 1463 CRC_RWSM_Warning 10000;
BA_ "GenSigStartValue" SG_ 1463 CRC_RWSM_Warning 65535;
BA_ "GenSigTimeoutTime" SG_ 1463 AlvCtr_RWSM_Warning 10000;
BA_ "GenSigStartValue" SG_ 1463 AlvCtr_RWSM_Warning 255;
BA_ "InvalidValue" SG_ 1463 ReWhlSteer_WarnLamp "7";
BA_ "GenSigTimeoutTime" SG_ 1463 ReWhlSteer_WarnLamp 10000;
BA_ "GenSigStartValue" SG_ 1463 ReWhlSteer_WarnLamp 7;
BA_ "GenSigSendType" SG_ 1463 ReWhlSteer_WarnLamp 2;
BA_ "GenSigTimeoutTime" SG_ 1464 CRC_ZCUR_Warning 10000;
BA_ "GenSigStartValue" SG_ 1464 CRC_ZCUR_Warning 65535;
BA_ "GenSigTimeoutTime" SG_ 1464 AlvCtr_ZCUR_Warning 10000;
BA_ "GenSigStartValue" SG_ 1464 AlvCtr_ZCUR_Warning 255;
BA_ "InvalidValue" SG_ 1464 SeatCfmt_ReLeVentnCshnFanFailWrn "3";
BA_ "GenSigTimeoutTime" SG_ 1464 SeatCfmt_ReLeVentnCshnFanFailWrn 10000;
BA_ "GenSigStartValue" SG_ 1464 SeatCfmt_ReLeVentnCshnFanFailWrn 3;
BA_ "GenSigSendType" SG_ 1464 SeatCfmt_ReLeVentnCshnFanFailWrn 2;
BA_ "InvalidValue" SG_ 1464 SeatCfmt_ReLeVentnSqubFanFailWrn "3";
BA_ "GenSigTimeoutTime" SG_ 1464 SeatCfmt_ReLeVentnSqubFanFailWrn 10000;
BA_ "GenSigStartValue" SG_ 1464 SeatCfmt_ReLeVentnSqubFanFailWrn 3;
BA_ "GenSigSendType" SG_ 1464 SeatCfmt_ReLeVentnSqubFanFailWrn 2;
BA_ "InvalidValue" SG_ 1464 SeatCfmt_ReRiVentnCshnFanFailWrn "3";
BA_ "GenSigTimeoutTime" SG_ 1464 SeatCfmt_ReRiVentnCshnFanFailWrn 10000;
BA_ "GenSigStartValue" SG_ 1464 SeatCfmt_ReRiVentnCshnFanFailWrn 3;
BA_ "GenSigSendType" SG_ 1464 SeatCfmt_ReRiVentnCshnFanFailWrn 2;
BA_ "InvalidValue" SG_ 1464 SeatCfmt_ReRiVentnSqubFanFailWrn "3";
BA_ "GenSigTimeoutTime" SG_ 1464 SeatCfmt_ReRiVentnSqubFanFailWrn 10000;
BA_ "GenSigStartValue" SG_ 1464 SeatCfmt_ReRiVentnSqubFanFailWrn 3;
BA_ "GenSigSendType" SG_ 1464 SeatCfmt_ReRiVentnSqubFanFailWrn 2;
BA_ "InvalidValue" SG_ 1464 Acttg_TailGate_Warn "3";
BA_ "GenSigTimeoutTime" SG_ 1464 Acttg_TailGate_Warn 10000;
BA_ "GenSigStartValue" SG_ 1464 Acttg_TailGate_Warn 3;
BA_ "GenSigSendType" SG_ 1464 Acttg_TailGate_Warn 2;
BA_ "InvalidValue" SG_ 1464 ChrgrPort_IlmnLampW_Warn "3";
BA_ "GenSigTimeoutTime" SG_ 1464 ChrgrPort_IlmnLampW_Warn 10000;
BA_ "GenSigStartValue" SG_ 1464 ChrgrPort_IlmnLampW_Warn 3;
BA_ "GenSigSendType" SG_ 1464 ChrgrPort_IlmnLampW_Warn 2;
BA_ "GenSigTimeoutTime" SG_ 1472 CRC_TLML_Warning 10000;
BA_ "GenSigTimeoutTime" SG_ 1472 AlvCtr_TLML_Warning 10000;
BA_ "GenSigStartValue" SG_ 1472 AlvCtr_TLML_Warning 255;
BA_ "InvalidValue" SG_ 1472 Relamp_ReLeTLGTurnIndcr_Warn "3";
BA_ "GenSigTimeoutTime" SG_ 1472 Relamp_ReLeTLGTurnIndcr_Warn 10000;
BA_ "GenSigStartValue" SG_ 1472 Relamp_ReLeTLGTurnIndcr_Warn 3;
BA_ "GenSigSendType" SG_ 1472 Relamp_ReLeTLGTurnIndcr_Warn 2;
BA_ "InvalidValue" SG_ 1472 Relamp_ReLeTLGPosnLamp_Warn "3";
BA_ "GenSigTimeoutTime" SG_ 1472 Relamp_ReLeTLGPosnLamp_Warn 10000;
BA_ "GenSigStartValue" SG_ 1472 Relamp_ReLeTLGPosnLamp_Warn 3;
BA_ "GenSigSendType" SG_ 1472 Relamp_ReLeTLGPosnLamp_Warn 2;
BA_ "InvalidValue" SG_ 1472 Relamp_LeTLGBrkLamp_Warn "3";
BA_ "GenSigTimeoutTime" SG_ 1472 Relamp_LeTLGBrkLamp_Warn 10000;
BA_ "GenSigStartValue" SG_ 1472 Relamp_LeTLGBrkLamp_Warn 3;
BA_ "GenSigSendType" SG_ 1472 Relamp_LeTLGBrkLamp_Warn 2;
BA_ "GenSigTimeoutTime" SG_ 1473 CRC_TLMR_Warning 10000;
BA_ "GenSigTimeoutTime" SG_ 1473 AlvCtr_TLMR_Warning 10000;
BA_ "GenSigStartValue" SG_ 1473 AlvCtr_TLMR_Warning 255;
BA_ "InvalidValue" SG_ 1473 Relamp_RiTLGBrkLamp_Warn "3";
BA_ "GenSigTimeoutTime" SG_ 1473 Relamp_RiTLGBrkLamp_Warn 10000;
BA_ "GenSigStartValue" SG_ 1473 Relamp_RiTLGBrkLamp_Warn 3;
BA_ "GenSigSendType" SG_ 1473 Relamp_RiTLGBrkLamp_Warn 2;
BA_ "InvalidValue" SG_ 1473 Relamp_ReRiTLGTurnIndcr_Warn "3";
BA_ "GenSigTimeoutTime" SG_ 1473 Relamp_ReRiTLGTurnIndcr_Warn 10000;
BA_ "GenSigStartValue" SG_ 1473 Relamp_ReRiTLGTurnIndcr_Warn 3;
BA_ "GenSigSendType" SG_ 1473 Relamp_ReRiTLGTurnIndcr_Warn 2;
BA_ "InvalidValue" SG_ 1473 Relamp_ReRiTLGPosnLamp_Warn "3";
BA_ "GenSigTimeoutTime" SG_ 1473 Relamp_ReRiTLGPosnLamp_Warn 10000;
BA_ "GenSigStartValue" SG_ 1473 Relamp_ReRiTLGPosnLamp_Warn 3;
BA_ "GenSigSendType" SG_ 1473 Relamp_ReRiTLGPosnLamp_Warn 2;
BA_ "GenSigTimeoutTime" SG_ 1474 CRC_RLML_Warning 10000;
BA_ "GenSigTimeoutTime" SG_ 1474 AlvCtr_RLML_Warning 10000;
BA_ "GenSigStartValue" SG_ 1474 AlvCtr_RLML_Warning 255;
BA_ "InvalidValue" SG_ 1474 Relamp_LeBodyBrkLamp_Warn "3";
BA_ "GenSigTimeoutTime" SG_ 1474 Relamp_LeBodyBrkLamp_Warn 10000;
BA_ "GenSigStartValue" SG_ 1474 Relamp_LeBodyBrkLamp_Warn 3;
BA_ "GenSigSendType" SG_ 1474 Relamp_LeBodyBrkLamp_Warn 2;
BA_ "InvalidValue" SG_ 1474 Relamp_ReLeBodyTurnIndcr_Warn "3";
BA_ "GenSigTimeoutTime" SG_ 1474 Relamp_ReLeBodyTurnIndcr_Warn 10000;
BA_ "GenSigStartValue" SG_ 1474 Relamp_ReLeBodyTurnIndcr_Warn 3;
BA_ "GenSigSendType" SG_ 1474 Relamp_ReLeBodyTurnIndcr_Warn 2;
BA_ "GenSigTimeoutTime" SG_ 1475 CRC_RLMR_Warning 10000;
BA_ "GenSigStartValue" SG_ 1475 CRC_RLMR_Warning 65535;
BA_ "GenSigTimeoutTime" SG_ 1475 AlvCtr_RLMR_Warning 10000;
BA_ "GenSigStartValue" SG_ 1475 AlvCtr_RLMR_Warning 255;
BA_ "InvalidValue" SG_ 1475 Relamp_ReRiBodyTurnIndcr_Warn "3";
BA_ "GenSigTimeoutTime" SG_ 1475 Relamp_ReRiBodyTurnIndcr_Warn 10000;
BA_ "GenSigStartValue" SG_ 1475 Relamp_ReRiBodyTurnIndcr_Warn 3;
BA_ "GenSigSendType" SG_ 1475 Relamp_ReRiBodyTurnIndcr_Warn 2;
BA_ "InvalidValue" SG_ 1475 Relamp_RiBodyBrkLamp_Warn "3";
BA_ "GenSigTimeoutTime" SG_ 1475 Relamp_RiBodyBrkLamp_Warn 10000;
BA_ "GenSigStartValue" SG_ 1475 Relamp_RiBodyBrkLamp_Warn 3;
BA_ "GenSigSendType" SG_ 1475 Relamp_RiBodyBrkLamp_Warn 2;
BA_ "GenSigTimeoutTime" SG_ 1481 CRC_SLMFC_Warning 10000;
BA_ "GenSigTimeoutTime" SG_ 1481 AlvCtr_SLMFC_Warning 10000;
BA_ "GenSigStartValue" SG_ 1481 AlvCtr_SLMFC_Warning 255;
BA_ "InvalidValue" SG_ 1481 Hdlamp_FrntCentr_LeSignLamp_Warn "3";
BA_ "GenSigTimeoutTime" SG_ 1481 Hdlamp_FrntCentr_LeSignLamp_Warn 10000;
BA_ "GenSigStartValue" SG_ 1481 Hdlamp_FrntCentr_LeSignLamp_Warn 3;
BA_ "GenSigSendType" SG_ 1481 Hdlamp_FrntCentr_LeSignLamp_Warn 2;
BA_ "InvalidValue" SG_ 1481 Hdlamp_FrntCentr_RiSignLamp_Warn "3";
BA_ "GenSigTimeoutTime" SG_ 1481 Hdlamp_FrntCentr_RiSignLamp_Warn 10000;
BA_ "GenSigStartValue" SG_ 1481 Hdlamp_FrntCentr_RiSignLamp_Warn 3;
BA_ "GenSigSendType" SG_ 1481 Hdlamp_FrntCentr_RiSignLamp_Warn 2;
BA_ "GenSigTimeoutTime" SG_ 1482 CRC_SLMFL_Warning 10000;
BA_ "GenSigTimeoutTime" SG_ 1482 AlvCtr_SLMFL_Warning 10000;
BA_ "GenSigStartValue" SG_ 1482 AlvCtr_SLMFL_Warning 255;
BA_ "InvalidValue" SG_ 1482 Hdlamp_FrntLeBodyTurnIndcr_Warn "3";
BA_ "GenSigTimeoutTime" SG_ 1482 Hdlamp_FrntLeBodyTurnIndcr_Warn 10000;
BA_ "GenSigStartValue" SG_ 1482 Hdlamp_FrntLeBodyTurnIndcr_Warn 3;
BA_ "GenSigSendType" SG_ 1482 Hdlamp_FrntLeBodyTurnIndcr_Warn 2;
BA_ "InvalidValue" SG_ 1482 Hdlamp_LeDRLLamp_Warn "3";
BA_ "GenSigTimeoutTime" SG_ 1482 Hdlamp_LeDRLLamp_Warn 10000;
BA_ "GenSigStartValue" SG_ 1482 Hdlamp_LeDRLLamp_Warn 3;
BA_ "GenSigSendType" SG_ 1482 Hdlamp_LeDRLLamp_Warn 2;
BA_ "InvalidValue" SG_ 1482 Hdlamp_LeFrntPosnLamp_Warn "3";
BA_ "GenSigTimeoutTime" SG_ 1482 Hdlamp_LeFrntPosnLamp_Warn 10000;
BA_ "GenSigStartValue" SG_ 1482 Hdlamp_LeFrntPosnLamp_Warn 3;
BA_ "GenSigSendType" SG_ 1482 Hdlamp_LeFrntPosnLamp_Warn 2;
BA_ "GenSigTimeoutTime" SG_ 1483 CRC_SLMFR_Warning 10000;
BA_ "GenSigStartValue" SG_ 1483 CRC_SLMFR_Warning 65535;
BA_ "GenSigTimeoutTime" SG_ 1483 AlvCtr_SLMFR_Warning 10000;
BA_ "GenSigStartValue" SG_ 1483 AlvCtr_SLMFR_Warning 255;
BA_ "InvalidValue" SG_ 1483 Hdlamp_FrntRiBodyTurnIndcr_Warn "3";
BA_ "GenSigTimeoutTime" SG_ 1483 Hdlamp_FrntRiBodyTurnIndcr_Warn 10000;
BA_ "GenSigStartValue" SG_ 1483 Hdlamp_FrntRiBodyTurnIndcr_Warn 3;
BA_ "GenSigSendType" SG_ 1483 Hdlamp_FrntRiBodyTurnIndcr_Warn 2;
BA_ "InvalidValue" SG_ 1483 Hdlamp_RiDRLLamp_Warn "3";
BA_ "GenSigTimeoutTime" SG_ 1483 Hdlamp_RiDRLLamp_Warn 10000;
BA_ "GenSigStartValue" SG_ 1483 Hdlamp_RiDRLLamp_Warn 3;
BA_ "GenSigSendType" SG_ 1483 Hdlamp_RiDRLLamp_Warn 2;
BA_ "InvalidValue" SG_ 1483 Hdlamp_RiFrntPosnLamp_Warn "3";
BA_ "GenSigTimeoutTime" SG_ 1483 Hdlamp_RiFrntPosnLamp_Warn 10000;
BA_ "GenSigStartValue" SG_ 1483 Hdlamp_RiFrntPosnLamp_Warn 3;
BA_ "GenSigSendType" SG_ 1483 Hdlamp_RiFrntPosnLamp_Warn 2;
BA_ "GenSigTimeoutTime" SG_ 1484 CRC_SLMRC_Warning 10000;
BA_ "GenSigTimeoutTime" SG_ 1484 AlvCtr_SLMRC_Warning 10000;
BA_ "GenSigStartValue" SG_ 1484 AlvCtr_SLMRC_Warning 255;
BA_ "InvalidValue" SG_ 1484 Relamp_Centr_RiSignLampSts "3";
BA_ "GenSigTimeoutTime" SG_ 1484 Relamp_Centr_RiSignLampSts 10000;
BA_ "GenSigStartValue" SG_ 1484 Relamp_Centr_RiSignLampSts 3;
BA_ "GenSigSendType" SG_ 1484 Relamp_Centr_RiSignLampSts 2;
BA_ "InvalidValue" SG_ 1484 Relamp_Centr_LeSignLampSts "3";
BA_ "GenSigTimeoutTime" SG_ 1484 Relamp_Centr_LeSignLampSts 10000;
BA_ "GenSigStartValue" SG_ 1484 Relamp_Centr_LeSignLampSts 3;
BA_ "GenSigSendType" SG_ 1484 Relamp_Centr_LeSignLampSts 2;
BA_ "GenSigSendType" SG_ 1538 IVI_DiagResp_Byte0 3;
BA_ "GenSigSendType" SG_ 1538 IVI_DiagResp_Byte1 3;
BA_ "GenSigSendType" SG_ 1538 IVI_DiagResp_Byte2 3;
BA_ "GenSigSendType" SG_ 1538 IVI_DiagResp_Byte3 3;
BA_ "GenSigSendType" SG_ 1538 IVI_DiagResp_Byte4 3;
BA_ "GenSigSendType" SG_ 1538 IVI_DiagResp_Byte5 3;
BA_ "GenSigSendType" SG_ 1538 IVI_DiagResp_Byte6 3;
BA_ "GenSigSendType" SG_ 1538 IVI_DiagResp_Byte7 3;
BA_ "GenSigSendType" SG_ 1538 IVI_DiagResp_Byte8 3;
BA_ "GenSigSendType" SG_ 1538 IVI_DiagResp_Byte9 3;
BA_ "GenSigSendType" SG_ 1538 IVI_DiagResp_Byte10 3;
BA_ "GenSigSendType" SG_ 1538 IVI_DiagResp_Byte11 3;
BA_ "GenSigSendType" SG_ 1538 IVI_DiagResp_Byte12 3;
BA_ "GenSigSendType" SG_ 1538 IVI_DiagResp_Byte13 3;
BA_ "GenSigSendType" SG_ 1538 IVI_DiagResp_Byte14 3;
BA_ "GenSigSendType" SG_ 1538 IVI_DiagResp_Byte15 3;
BA_ "GenSigSendType" SG_ 1538 IVI_DiagResp_Byte16 3;
BA_ "GenSigSendType" SG_ 1538 IVI_DiagResp_Byte17 3;
BA_ "GenSigSendType" SG_ 1538 IVI_DiagResp_Byte18 3;
BA_ "GenSigSendType" SG_ 1538 IVI_DiagResp_Byte19 3;
BA_ "GenSigSendType" SG_ 1538 IVI_DiagResp_Byte20 3;
BA_ "GenSigSendType" SG_ 1538 IVI_DiagResp_Byte21 3;
BA_ "GenSigSendType" SG_ 1538 IVI_DiagResp_Byte22 3;
BA_ "GenSigSendType" SG_ 1538 IVI_DiagResp_Byte23 3;
BA_ "GenSigSendType" SG_ 1538 IVI_DiagResp_Byte24 3;
BA_ "GenSigSendType" SG_ 1538 IVI_DiagResp_Byte25 3;
BA_ "GenSigSendType" SG_ 1538 IVI_DiagResp_Byte26 3;
BA_ "GenSigSendType" SG_ 1538 IVI_DiagResp_Byte27 3;
BA_ "GenSigSendType" SG_ 1538 IVI_DiagResp_Byte28 3;
BA_ "GenSigSendType" SG_ 1538 IVI_DiagResp_Byte29 3;
BA_ "GenSigSendType" SG_ 1538 IVI_DiagResp_Byte30 3;
BA_ "GenSigSendType" SG_ 1538 IVI_DiagResp_Byte31 3;
BA_ "GenSigSendType" SG_ 1538 IVI_DiagResp_Byte32 3;
BA_ "GenSigSendType" SG_ 1538 IVI_DiagResp_Byte33 3;
BA_ "GenSigSendType" SG_ 1538 IVI_DiagResp_Byte34 3;
BA_ "GenSigSendType" SG_ 1538 IVI_DiagResp_Byte35 3;
BA_ "GenSigSendType" SG_ 1538 IVI_DiagResp_Byte36 3;
BA_ "GenSigSendType" SG_ 1538 IVI_DiagResp_Byte37 3;
BA_ "GenSigSendType" SG_ 1538 IVI_DiagResp_Byte38 3;
BA_ "GenSigSendType" SG_ 1538 IVI_DiagResp_Byte39 3;
BA_ "GenSigSendType" SG_ 1538 IVI_DiagResp_Byte40 3;
BA_ "GenSigSendType" SG_ 1538 IVI_DiagResp_Byte41 3;
BA_ "GenSigSendType" SG_ 1538 IVI_DiagResp_Byte42 3;
BA_ "GenSigSendType" SG_ 1538 IVI_DiagResp_Byte43 3;
BA_ "GenSigSendType" SG_ 1538 IVI_DiagResp_Byte44 3;
BA_ "GenSigSendType" SG_ 1538 IVI_DiagResp_Byte45 3;
BA_ "GenSigSendType" SG_ 1538 IVI_DiagResp_Byte46 3;
BA_ "GenSigSendType" SG_ 1538 IVI_DiagResp_Byte47 3;
BA_ "GenSigSendType" SG_ 1538 IVI_DiagResp_Byte48 3;
BA_ "GenSigSendType" SG_ 1538 IVI_DiagResp_Byte49 3;
BA_ "GenSigSendType" SG_ 1538 IVI_DiagResp_Byte50 3;
BA_ "GenSigSendType" SG_ 1538 IVI_DiagResp_Byte51 3;
BA_ "GenSigSendType" SG_ 1538 IVI_DiagResp_Byte52 3;
BA_ "GenSigSendType" SG_ 1538 IVI_DiagResp_Byte53 3;
BA_ "GenSigSendType" SG_ 1538 IVI_DiagResp_Byte54 3;
BA_ "GenSigSendType" SG_ 1538 IVI_DiagResp_Byte55 3;
BA_ "GenSigSendType" SG_ 1538 IVI_DiagResp_Byte56 3;
BA_ "GenSigSendType" SG_ 1538 IVI_DiagResp_Byte57 3;
BA_ "GenSigSendType" SG_ 1538 IVI_DiagResp_Byte58 3;
BA_ "GenSigSendType" SG_ 1538 IVI_DiagResp_Byte59 3;
BA_ "GenSigSendType" SG_ 1538 IVI_DiagResp_Byte60 3;
BA_ "GenSigSendType" SG_ 1538 IVI_DiagResp_Byte61 3;
BA_ "GenSigSendType" SG_ 1538 IVI_DiagResp_Byte62 3;
BA_ "GenSigSendType" SG_ 1538 IVI_DiagResp_Byte63 3;
BA_ "GenSigSendType" SG_ 1586 WLC_DiagResp_Byte0 3;
BA_ "GenSigSendType" SG_ 1586 WLC_DiagResp_Byte1 3;
BA_ "GenSigSendType" SG_ 1586 WLC_DiagResp_Byte2 3;
BA_ "GenSigSendType" SG_ 1586 WLC_DiagResp_Byte3 3;
BA_ "GenSigSendType" SG_ 1586 WLC_DiagResp_Byte4 3;
BA_ "GenSigSendType" SG_ 1586 WLC_DiagResp_Byte5 3;
BA_ "GenSigSendType" SG_ 1586 WLC_DiagResp_Byte6 3;
BA_ "GenSigSendType" SG_ 1586 WLC_DiagResp_Byte7 3;
BA_ "GenSigSendType" SG_ 1666 IVI_DiagReq_Byte0 3;
BA_ "GenSigSendType" SG_ 1666 IVI_DiagReq_Byte1 3;
BA_ "GenSigSendType" SG_ 1666 IVI_DiagReq_Byte2 3;
BA_ "GenSigSendType" SG_ 1666 IVI_DiagReq_Byte3 3;
BA_ "GenSigSendType" SG_ 1666 IVI_DiagReq_Byte4 3;
BA_ "GenSigSendType" SG_ 1666 IVI_DiagReq_Byte5 3;
BA_ "GenSigSendType" SG_ 1666 IVI_DiagReq_Byte6 3;
BA_ "GenSigSendType" SG_ 1666 IVI_DiagReq_Byte7 3;
BA_ "GenSigSendType" SG_ 1666 IVI_DiagReq_Byte8 3;
BA_ "GenSigSendType" SG_ 1666 IVI_DiagReq_Byte9 3;
BA_ "GenSigSendType" SG_ 1666 IVI_DiagReq_Byte10 3;
BA_ "GenSigSendType" SG_ 1666 IVI_DiagReq_Byte11 3;
BA_ "GenSigSendType" SG_ 1666 IVI_DiagReq_Byte12 3;
BA_ "GenSigSendType" SG_ 1666 IVI_DiagReq_Byte13 3;
BA_ "GenSigSendType" SG_ 1666 IVI_DiagReq_Byte14 3;
BA_ "GenSigSendType" SG_ 1666 IVI_DiagReq_Byte15 3;
BA_ "GenSigSendType" SG_ 1666 IVI_DiagReq_Byte16 3;
BA_ "GenSigSendType" SG_ 1666 IVI_DiagReq_Byte17 3;
BA_ "GenSigSendType" SG_ 1666 IVI_DiagReq_Byte18 3;
BA_ "GenSigSendType" SG_ 1666 IVI_DiagReq_Byte19 3;
BA_ "GenSigSendType" SG_ 1666 IVI_DiagReq_Byte20 3;
BA_ "GenSigSendType" SG_ 1666 IVI_DiagReq_Byte21 3;
BA_ "GenSigSendType" SG_ 1666 IVI_DiagReq_Byte22 3;
BA_ "GenSigSendType" SG_ 1666 IVI_DiagReq_Byte23 3;
BA_ "GenSigSendType" SG_ 1666 IVI_DiagReq_Byte24 3;
BA_ "GenSigSendType" SG_ 1666 IVI_DiagReq_Byte25 3;
BA_ "GenSigSendType" SG_ 1666 IVI_DiagReq_Byte26 3;
BA_ "GenSigSendType" SG_ 1666 IVI_DiagReq_Byte27 3;
BA_ "GenSigSendType" SG_ 1666 IVI_DiagReq_Byte28 3;
BA_ "GenSigSendType" SG_ 1666 IVI_DiagReq_Byte29 3;
BA_ "GenSigSendType" SG_ 1666 IVI_DiagReq_Byte30 3;
BA_ "GenSigSendType" SG_ 1666 IVI_DiagReq_Byte31 3;
BA_ "GenSigSendType" SG_ 1666 IVI_DiagReq_Byte32 3;
BA_ "GenSigSendType" SG_ 1666 IVI_DiagReq_Byte33 3;
BA_ "GenSigSendType" SG_ 1666 IVI_DiagReq_Byte34 3;
BA_ "GenSigSendType" SG_ 1666 IVI_DiagReq_Byte35 3;
BA_ "GenSigSendType" SG_ 1666 IVI_DiagReq_Byte36 3;
BA_ "GenSigSendType" SG_ 1666 IVI_DiagReq_Byte37 3;
BA_ "GenSigSendType" SG_ 1666 IVI_DiagReq_Byte38 3;
BA_ "GenSigSendType" SG_ 1666 IVI_DiagReq_Byte39 3;
BA_ "GenSigSendType" SG_ 1666 IVI_DiagReq_Byte40 3;
BA_ "GenSigSendType" SG_ 1666 IVI_DiagReq_Byte41 3;
BA_ "GenSigSendType" SG_ 1666 IVI_DiagReq_Byte42 3;
BA_ "GenSigSendType" SG_ 1666 IVI_DiagReq_Byte43 3;
BA_ "GenSigSendType" SG_ 1666 IVI_DiagReq_Byte44 3;
BA_ "GenSigSendType" SG_ 1666 IVI_DiagReq_Byte45 3;
BA_ "GenSigSendType" SG_ 1666 IVI_DiagReq_Byte46 3;
BA_ "GenSigSendType" SG_ 1666 IVI_DiagReq_Byte47 3;
BA_ "GenSigSendType" SG_ 1666 IVI_DiagReq_Byte48 3;
BA_ "GenSigSendType" SG_ 1666 IVI_DiagReq_Byte49 3;
BA_ "GenSigSendType" SG_ 1666 IVI_DiagReq_Byte50 3;
BA_ "GenSigSendType" SG_ 1666 IVI_DiagReq_Byte51 3;
BA_ "GenSigSendType" SG_ 1666 IVI_DiagReq_Byte52 3;
BA_ "GenSigSendType" SG_ 1666 IVI_DiagReq_Byte53 3;
BA_ "GenSigSendType" SG_ 1666 IVI_DiagReq_Byte54 3;
BA_ "GenSigSendType" SG_ 1666 IVI_DiagReq_Byte55 3;
BA_ "GenSigSendType" SG_ 1666 IVI_DiagReq_Byte56 3;
BA_ "GenSigSendType" SG_ 1666 IVI_DiagReq_Byte57 3;
BA_ "GenSigSendType" SG_ 1666 IVI_DiagReq_Byte58 3;
BA_ "GenSigSendType" SG_ 1666 IVI_DiagReq_Byte59 3;
BA_ "GenSigSendType" SG_ 1666 IVI_DiagReq_Byte60 3;
BA_ "GenSigSendType" SG_ 1666 IVI_DiagReq_Byte61 3;
BA_ "GenSigSendType" SG_ 1666 IVI_DiagReq_Byte62 3;
BA_ "GenSigSendType" SG_ 1666 IVI_DiagReq_Byte63 3;
BA_ "GenSigSendType" SG_ 1714 WLC_DiagReq_Byte0 3;
BA_ "GenSigSendType" SG_ 1714 WLC_DiagReq_Byte1 3;
BA_ "GenSigSendType" SG_ 1714 WLC_DiagReq_Byte2 3;
BA_ "GenSigSendType" SG_ 1714 WLC_DiagReq_Byte3 3;
BA_ "GenSigSendType" SG_ 1714 WLC_DiagReq_Byte4 3;
BA_ "GenSigSendType" SG_ 1714 WLC_DiagReq_Byte5 3;
BA_ "GenSigSendType" SG_ 1714 WLC_DiagReq_Byte6 3;
BA_ "GenSigSendType" SG_ 1714 WLC_DiagReq_Byte7 3;
BA_ "GenSigSendType" SG_ 1791 OBD_FuncDiagReq_Byte0 3;
BA_ "GenSigSendType" SG_ 1791 OBD_FuncDiagReq_Byte1 3;
BA_ "GenSigSendType" SG_ 1791 OBD_FuncDiagReq_Byte2 3;
BA_ "GenSigSendType" SG_ 1791 OBD_FuncDiagReq_Byte3 3;
BA_ "GenSigSendType" SG_ 1791 OBD_FuncDiagReq_Byte4 3;
BA_ "GenSigSendType" SG_ 1791 OBD_FuncDiagReq_Byte5 3;
BA_ "GenSigSendType" SG_ 1791 OBD_FuncDiagReq_Byte6 3;
BA_ "GenSigSendType" SG_ 1791 OBD_FuncDiagReq_Byte7 3;
VAL_ 1131 AlvCtr_IVI_DrvrSeatStoredProfile 15 "Invalid Value" ;
VAL_ 1141 AlvCtr_IVI_HvacCntrl 15 "Invalid Value" ;
VAL_ 1141 Ccsf_VentOpModeReq 0 "NormallyOutwards" 1 "HarmonicsUpDown" 2 "HarmonicsSideBySide" 3 "NotAvailable" ;
VAL_ 1141 Ccs_ReAcUsrIReq 0 "Off" 1 "On" 2 "Error" 3 "NotAvailable" ;
VAL_ 1141 Demir_HeatgSVMCReq 0 "REQ_HEAT_DIS" 1 "REQ_HEAT_ENA" 2 "REQ_HEAT_RESERVED" 3 "REQ_HEAT_SNA" ;
VAL_ 1141 Ccs_ReBlowrLvUsrlReq 0 "Level0" 1 "Level1" 2 "Level2" 3 "Level3" 4 "Level4" 5 "Level5" 6 "Error" 7 "NotAvailable" ;
VAL_ 1147 Ccs_AcMinTUsrBtn 0 "Not_Pressed" 1 "Pressed" 2 "Error" 3 "NotAvailable" ;
VAL_ 1147 Ccs_AcMaxTUsrBtn 0 "Not available" 1 "Available" 2 "Error" 3 "SNA" ;
VAL_ 1147 Ccs_RclOnOffReq 0 "Off" 1 "On" 2 "Error" 3 "NotAvailable" ;
VAL_ 1147 Ccs_FrntAcUsrReq 0 "Off" 1 "On" 2 "Error" 3 "NotAvailable" ;
VAL_ 1147 Ccs_SyncTReq 0 "Sync not requested" 1 "Sync requested" 2 "Reserved" 3 "Signal Invalid" ;
VAL_ 1147 Ccs_AcEcoModeBtnUsrReq 0 "Not_Pressed" 1 "Pressed" 2 "Error" 3 "NotAvailable" ;
VAL_ 1147 Ccs_FrntAcAutoModUsrReq 0 "Off" 1 "On" 2 "Error" 3 "NotAvailable" ;
VAL_ 1147 Ccs_IoniserUsrReq 0 "Off" 1 "On" 2 "Error" 3 "NotAvailable" ;
VAL_ 1147 Ccs_FrgrncAcvnUsrReq 0 "Off" 1 "On" 2 "Error" 3 "NotAvailable" ;
VAL_ 1147 Ccs_DemistDefrstUsrReq 0 "Off" 1 "On" 2 "Error" 3 "NotAvailable" ;
VAL_ 1147 Ccs_FrntBlowrLvlUsrReq 0 "Level0" 1 "Level1" 2 "Level2" 3 "Level3" 4 "Level4" 5 "Level5" 6 "Error" 7 "NotAvailable" ;
VAL_ 1147 Ccs_AirModeSelnUsrReq 0 "Face" 1 "FaceFoot" 2 "Foot" 3 "FootSideWindowDemist" 4 "SideWindowDemist" 5 "DiffuseAmbient" 6 "DiffuseAmbientFace" 7 "NotAvailable" ;
VAL_ 1147 Ccs_ClimPrsetUsrReq 0 "Preset1" 1 "Preset2" 2 "Preset3" 3 "Preset4" 4 "Reserved" 5 "Reserved" 6 "Reserved" 7 "NotAvailable" ;
VAL_ 1147 Ccs_FrgrncSlenUsrReq 0 "FragranceSlot1" 1 "FragranceSlot2" 2 "FragranceSlot3" 3 "FragranceSlot4" 4 "Reserved" 5 "Reserved" 6 "Error" 7 "NotAvailable" ;
VAL_ 1147 Ccs_ClimPrflSelnUsrReq 0 "Profile1" 1 "Profile2" 2 "Profile3" 3 "Profile4" 4 "Reserved" 5 "Reserved" 6 "Reserved" 7 "NotAvailable" ;
VAL_ 1157 ChrgrPort_ChrgPortLckUnlckUsrReq 0 "Unlock" 1 "Lock" 2 "Reserved" 3 "NotAvailable" ;
VAL_ 1157 Demir_FoldUnfoldSVMCReq 0 "REQ_DEM_FOLD" 1 "REQ_DEM_UNFOLD" 2 "REQ_DEM_RESERVED" 3 "REQ_DEM_SNA" ;
VAL_ 1157 Demir_FoldUnfoldUsrReq 0 "REQ_DEM_FOLD" 1 "REQ_DEM_UNFOLD" 2 "REQ_DEM_RESERVED" 3 "REQ_DEM_SNA" ;
VAL_ 1157 Demir_HeatgSVMC_Ena 0 "Not available" 1 "Available" 2 "Error" 3 "SNA" ;
VAL_ 1157 Acttg_TailGateUsrReq 0 "Open" 1 "Closed" 2 "Error" 3 "NotAvailable" ;
VAL_ 1157 Ssadl_AutoSpdLockOnOffTypSts 0 "Off" 1 "On" 2 "Error" 3 "NotAvailable" ;
VAL_ 1157 Relamp_ReFogLiReq 0 "Off" 1 "On" 2 "Error" 3 "NotAvailable" ;
VAL_ 1157 Hdlamp_LampReq 0 "Off" 1 "On" 2 "Flash" 3 "NotAvailable" ;
VAL_ 1157 Hdlamp_AutoModeCfgReq 0 "Not available" 1 "Available" 2 "Error" 3 "SNA" ;
VAL_ 1157 Hdlamp_FollowMeCfg 0 "Level0" 1 "Level1" 2 "Level2" 3 "Level3" 4 "Level4" 5 "Level5" 6 "Error" 7 "NotAvailable" ;
VAL_ 1157 Wipr_FrntWiprReq 0 "Off" 1 "Low" 2 "High" 3 "Auto" 4 "SingleWipe" 5 "Reserved" 6 "Error" 7 "NotAvailable" ;
VAL_ 1157 Wipr_FrntOperParkReq 0 "Off" 1 "On" 2 "Error" 3 "NotAvailable" ;
VAL_ 1157 Wipr_FrntWiprSrvPosReq 0 "Off" 1 "On" 2 "Error" 3 "NotAvailable" ;
VAL_ 1163 Hdc_SwtSts 0 "Inactive" 1 "Active" 2 "Error" 3 "NotAvailable" ;
VAL_ 1163 EscTcs_SwtSts 0 "Inactive" 1 "Active" 2 "Error" 3 "NotAvailable" ;
VAL_ 1163 IVI_IngrsModeCmd 0 "Disable" 1 "Enable" 2 "Reserved" 3 "Not Available" ;
VAL_ 1163 AVH_Swt_Sts 0 "Inactive" 1 "Active" 2 "Error" 3 "NotAvailable" ;
VAL_ 1163 IVI_SuspHeiAdjReq 0 "NotRequested" 1 "Nominal" 2 "Low" 3 "High" 4 "Reserved" 5 "Reserved" 6 "Reserved" 7 "Not Available" ;
VAL_ 1163 IVI_SrvModCmd 0 "Disable" 1 "Enable" 2 "Reserved" 3 "Not Available" ;
VAL_ 1173 AlvCtr_IVI_UsrSeatAdjComfrt_Req 15 "Invalid Value" ;
VAL_ 1173 SeatAdjmt_DrvFowdBawdReq 0 "NoRequest" 1 "ForwardMovement" 2 "BackwardMovement" 3 "Error" ;
VAL_ 1173 SeatAdjmt_DrvHeiUpDwnReq 0 "NoRequest" 1 "Up" 2 "Down" 3 "Error" ;
VAL_ 1173 SeatAdjmt_DrvLumInOutReq 0 "NoRequest" 1 "In" 2 "Out" 3 "Error" ;
VAL_ 1173 SeatAdjmt_DrvLumUpDwnReq 0 "NoRequest" 1 "Up" 2 "Down" 3 "Error" ;
VAL_ 1173 SeatAdjmt_DrvReclUpDownReq 0 "NoRequest" 1 "Up" 2 "Down" 3 "Error" ;
VAL_ 1173 SeatCfmt_DrvMassgIntenSelnReq 0 "Off" 1 "Low" 2 "Medium" 3 "High" 4 "Reserved" 5 "Reserved" 6 "Reserved" 7 "Invalid" ;
VAL_ 1173 SeatCfmt_DrvMassgPatSelnReq 0 "Off" 1 "Pattern1" 2 "Pattern2" 3 "Pattern3" 4 "Pattern4" 5 "Pattern5" 6 "Reserved" 7 "NotAvailable" ;
VAL_ 1173 SeatAdjmt_PassFowdBawdReq 0 "NoRequest" 1 "ForwardMovement" 2 "BackwardMovement" 3 "Error" ;
VAL_ 1173 SeatAdjmt_PassHeiUpDwnReq 0 "NoRequest" 1 "Up" 2 "Down" 3 "Error" ;
VAL_ 1173 SeatAdjmt_PassLumInOutReq 0 "NoRequest" 1 "In" 2 "Out" 3 "Error" ;
VAL_ 1173 SeatAdjmt_PassLumUpDwnReq 0 "NoRequest" 1 "Up" 2 "Down" 3 "Error" ;
VAL_ 1173 SeatAdjmt_PassReclUpDownReq 0 "NoRequest" 1 "Up" 2 "Down" 3 "Error" ;
VAL_ 1173 SeatAdjmt_PassTiltUpDwnReq 0 "NoRequest" 1 "Up" 2 "Down" 3 "Error" ;
VAL_ 1173 SeatAdjmt_DrvTiltUpDwnReq 0 "NoRequest" 1 "Up" 2 "Down" 3 "Error" ;
VAL_ 1173 SeatCfmt_PassMassgIntenSelnReq 0 "Off" 1 "Low" 2 "Medium" 3 "High" 4 "Reserved" 5 "Reserved" 6 "Reserved" 7 "Invalid" ;
VAL_ 1173 SeatCfmt_PassMassgPatSelnReq 0 "Off" 1 "Pattern1" 2 "Pattern2" 3 "Pattern3" 4 "Pattern4" 5 "Pattern5" 6 "Reserved" 7 "NotAvailable" ;
VAL_ 1173 SeatCfmt_ReLeVentnSpdReq 0 "Off" 1 "Low" 2 "Medium" 3 "High" 4 "Reserved" 5 "Reserved" 6 "Reserved" 7 "Invalid" ;
VAL_ 1173 SeatCfmt_ReRiVentnSpdReq 0 "Off" 1 "Low" 2 "Medium" 3 "High" 4 "Reserved" 5 "Reserved" 6 "Reserved" 7 "Invalid" ;
VAL_ 1179 Klss_UsrVehPwrDnReq 0 "Off" 1 "On" 2 "Error" 3 "NotAvailable" ;
VAL_ 1179 HMI_KeepAlive 0 "Not available" 1 "Available" 2 "Error" 3 "SNA" ;
VAL_ 1179 Lvm_LongParkMode_Req 0 "Deactivated" 1 "Activated" 2 "Error" 3 "NotAvailable" ;
VAL_ 1179 Lvm_StorageMode_Req 0 "Deactivated" 1 "Activated" 2 "Error" 3 "NotAvailable" ;
VAL_ 1179 Drvmc_Mode_Req 0 "EcoPlus" 1 "Eco" 2 "Normal
" 3 "Sport" 4 "SportsPlus" 5 "Sand_Off
" 6 "Reserve" 7 "NotAvailable" ;
VAL_ 1179 Eshift_TagtGear_Req 0 "Park" 1 "Reverse" 2 "Neutral" 3 "Drive" 4 "Reserved" 5 "Reserved" 6 "Error" 7 "NotAvailable" ;
VAL_ 1411 Kle_NfcCcCardVldtn_St_Warn 0 "No_Warning" 1 "Warning" 2 "Reserved" 3 "NotAvailable" ;
VAL_ 1412 Acchg_ChgGunUnlckWarn 0 "No_Warning" 1 "Warning" 2 "Reserved" 3 "NotAvailable" ;
VAL_ 1412 Hvsco_HV_SysWarn 0 "No_Warning" 1 "Warning" 2 "Reserved" 3 "NotAvailable" ;
VAL_ 1412 Thmgt_CooltOverTWarn 0 "No_Warning" 1 "Warning" 2 "Reserved" 3 "NotAvailable" ;
VAL_ 1412 Eshift_PsdBrkToEngeGear 0 "No_Warning" 1 "Warning" 2 "Reserved" 3 "NotAvailable" ;
VAL_ 1412 Awd_WhlDrvModeWarn 0 "No_Warning" 1 "Warning" 2 "Reserved" 3 "NotAvailable" ;
VAL_ 1412 Drvmc_DrvModeChngRestrWarn 0 "No_Warning" 1 "Warning" 2 "Reserved" 3 "NotAvailable" ;
VAL_ 1412 Eshift_HvDcnctNoGearChngWarn 0 "No_Warning" 1 "Warning" 2 "Reserved" 3 "NotAvailable" ;
VAL_ 1412 Eshift_GearChng_EPBEngeWarn 0 "No_Warning" 1 "Warning" 2 "Reserved" 3 "NotAvailable" ;
VAL_ 1412 Thmgt_CooltLvlLoWarn 0 "No_Warning" 1 "Warning" 2 "Reserved" 3 "NotAvailable" ;
VAL_ 1412 Eshift_StopVehToMoveFowdDir 0 "No_Warning" 1 "Warning" 2 "Reserved" 3 "NotAvailable" ;
VAL_ 1412 Hvsft_HvsftSts 0 "No_Warning" 1 "Warning" 2 "Reserved" 3 "NotAvailable" ;
VAL_ 1412 VCU_LimphmWarn 0 "No_Warning" 1 "Warning" 2 "Reserved" 3 "NotAvailable" ;
VAL_ 1412 Eshift_EppFaiWarn 0 "No_Warning" 1 "Warning" 2 "Reserved" 3 "NotAvailable" ;
VAL_ 1412 Thmgt_Therm_FltWarn 0 "No_Warning" 1 "Warning" 2 "Reserved" 3 "NotAvailable" ;
VAL_ 1412 Acchr_ChgAuthWarn 0 "No_Warning" 1 "Warning" 2 "Reserved" 3 "NotAvailable" ;
VAL_ 1412 Eshift_ACT_GearWarn 0 "No_Warning" 1 "Warning" 2 "Reserved" 3 "NotAvailable" ;
VAL_ 1412 Eshift_TagtGearVldtnWarn 0 "No_Warning" 1 "Warning" 2 "Reserved" 3 "NotAvailable" ;
VAL_ 1412 Hvsft_HvilErrWarn 0 "No_Warning" 1 "Warning" 2 "Reserved" 3 "NotAvailable" ;
VAL_ 1412 Eshift_StopVehToMoveRvsDir 0 "No_Warning" 1 "Warning" 2 "Reserved" 3 "NotAvailable" ;
VAL_ 1412 VCU_HV_Sys_FltLvl1Warn 0 "No_Warning" 1 "Warning" 2 "Reserved" 3 "NotAvailable" ;
VAL_ 1412 VCU_HV_Sys_FltLvl2Warn 0 "No_Warning" 1 "Warning" 2 "Reserved" 3 "NotAvailable" ;
VAL_ 1412 VCU_HV_Sys_FltLvl3Warn 0 "No_Warning" 1 "Warning" 2 "Reserved" 3 "NotAvailable" ;
VAL_ 1412 Cregb_CoastRgnWarn 0 "No_Warning" 1 "Warning" 2 "Reserved" 3 "NotAvailable" ;
VAL_ 1413 CenLock_LockUnlckSts_Warn 0 "No_Warning" 1 "Warning" 2 "Reserved" 3 "NotAvailable" ;
VAL_ 1413 Wipr_FrntRiFaild_Warn 0 "No_Warning" 1 "Warning" 2 "Reserved" 3 "NotAvailable" ;
VAL_ 1413 SwtCtl_PassSeatHeatingSwFlt_Warn 0 "No_Warning" 1 "Warning" 2 "Reserved" 3 "NotAvailable" ;
VAL_ 1413 SwtCtl_VolSwtFlt_Warn 0 "No_Warning" 1 "Warning" 2 "Reserved" 3 "NotAvailable" ;
VAL_ 1413 Wipr_FrntLeFaild_Warn 0 "No_Warning" 1 "Warning" 2 "Reserved" 3 "NotAvailable" ;
VAL_ 1413 SwttCtl_DrvrStHeatngSwtFlt_Wrn 0 "No_Warning" 1 "Warning" 2 "Reserved" 3 "NotAvailable" ;
VAL_ 1413 Relamp_RevLmpWarn 0 "No_Warning" 1 "Warning" 2 "Reserved" 3 "NotAvailable" ;
VAL_ 1413 RLML_FogLmp_Warn 0 "No_Warning" 1 "Warning" 2 "Reserved" 3 "NotAvailable" ;
VAL_ 1413 SwtCtl_ChdLockSwtFault_Warn 0 "No_Warning" 1 "Warning" 2 "Reserved" 3 "NotAvailable" ;
VAL_ 1413 SwttCtl_ReclrnModOnOffSwtFlt_Wrn 0 "No_Warning" 1 "Warning" 2 "Reserved" 3 "NotAvailable" ;
VAL_ 1413 RLMR_FogLmp_Warn 0 "No_Warning" 1 "Warning" 2 "Reserved" 3 "NotAvailable" ;
VAL_ 1413 Relamp_Chmsl_Warn 0 "No_Warning" 1 "Warning" 2 "Reserved" 3 "NotAvailable" ;
VAL_ 1413 SwtCtl_HzrdSwtFlt_Warn 0 "No_Warning" 1 "Warning" 2 "Reserved" 3 "NotAvailable" ;
VAL_ 1413 Ssadl_DoorAct_Warn 0 "No_Warning" 1 "Warning" 2 "Reserved" 3 "NotAvailable" ;
VAL_ 1413 Ssadl_DoorAjar_Warn 0 "No_Warning" 1 "Warning" 2 "Reserved" 3 "NotAvailable" ;
VAL_ 1413 Ccs_SrvWarn 0 "Normal" 1 "Faulty" 2 "Reserved" 3 "NotAvailable" ;
VAL_ 1424 AlvCtr_ACM_Warning 15 "Invalid Value" ;
VAL_ 1424 SbltWarn_BlinkingRmnReq 0 "No Lit" 1 "Solid Lit" 2 "Blinking Level 1" 3 "Blinking Level 2" 4 "Reserve" 5 "Reserve" 6 "Error" 7 "Invalid" ;
VAL_ 1424 AirBg_WarnLamp 0 "Off" 1 "On" 2 "Flash" 3 "NotAvailable" ;
VAL_ 1424 AirBg_PassAirbgDeac_Warn 0 "No_Warning" 1 "Warning" 2 "Reserved" 3 "NotAvailable" ;
VAL_ 1424 SbltWarn_DrvrIndcrSts 0 "Grey" 1 "Red" 2 "Green" 3 "NotAvailable" ;
VAL_ 1424 SbltWarn_PassIndcrSts 0 "Grey" 1 "Red" 2 "Green" 3 "NotAvailable" ;
VAL_ 1424 SbltWarn_ReCentrIndcrSts 0 "Grey" 1 "Red" 2 "Green" 3 "NotAvailable" ;
VAL_ 1424 SbltWarn_ReRiIndcrSts 0 "Grey" 1 "Red" 2 "Green" 3 "NotAvailable" ;
VAL_ 1424 SbltWarn_ReLeIndcrSts 0 "Grey" 1 "Red" 2 "Green" 3 "NotAvailable" ;
VAL_ 1424 SbltWarn_DrvrBklSts 0 "Not_Belted" 1 "Belted" 2 "Error" 3 "NotAvailable" ;
VAL_ 1424 SbltWarn_PassBklSts 0 "Not_Belted" 1 "Belted" 2 "Error" 3 "NotAvailable" ;
VAL_ 1424 SbltWarn_ReCentrBklSts 0 "Not_Belted" 1 "Belted" 2 "Error" 3 "NotAvailable" ;
VAL_ 1424 SbltWarn_ReRiBklSts 0 "Not_Belted" 1 "Belted" 2 "Error" 3 "NotAvailable" ;
VAL_ 1424 SbltWarn_ReLeBklSts 0 "Not_Belted" 1 "Belted" 2 "Error" 3 "NotAvailable" ;
VAL_ 1424 SbltWarn_ChimeRmnReq 0 "NoChime" 1 "ChimeLevel1" 2 "ChimeLevel2" 3 "NotAvailable" ;
VAL_ 1425 AlvCtr_DCMRL_Warning 15 "Invalid Value" ;
VAL_ 1425 Pwind_ReLeWndw_Warn 0 "No_Warning" 1 "Warning" 2 "Reserved" 3 "NotAvailable" ;
VAL_ 1426 AlvCtr_DCMRR_Warning 15 "Invalid Value" ;
VAL_ 1426 CenLock_ReRiDoorAjar_Warn 0 "No_Warning" 1 "Warning" 2 "Reserved" 3 "NotAvailable" ;
VAL_ 1426 Pwind_ReRiWndw_Warn 0 "No_Warning" 1 "Warning" 2 "Reserved" 3 "NotAvailable" ;
VAL_ 1427 AirSuspUnit_Warn 0 "No_Warning" 1 "Warning" 2 "Reserved" 3 "NotAvailable" ;
VAL_ 1427 AirSuspUnit_SrvModeNotActvdWarn 0 "No_Warning" 1 "Warning" 2 "Reserved" 3 "NotAvailable" ;
VAL_ 1428 AlvCtr_DCMP_Warning 15 "Invalid Value" ;
VAL_ 1428 CenLock_PassDoorAjar_Warn 0 "No_Warning" 1 "Warning" 2 "Reserved" 3 "NotAvailable" ;
VAL_ 1428 Pwind_PassWndw_Warn 0 "No_Warning" 1 "Warning" 2 "Reserved" 3 "NotAvailable" ;
VAL_ 1429 Bms_CellUDifErrWarn 0 "No_Warning" 1 "Warning" 2 "Reserved" 3 "NotAvailable" ;
VAL_ 1429 Bms_CooltInletTSnsrFltWarn 0 "No_Warning" 1 "Warning" 2 "Reserved" 3 "NotAvailable" ;
VAL_ 1429 Bms_CooltOutlTSnsrFltWarn 0 "No_Warning" 1 "Warning" 2 "Reserved" 3 "NotAvailable" ;
VAL_ 1429 Bms_DCFCNegRlyErrWarn 0 "No_Warning" 1 "Warning" 2 "Reserved" 3 "NotAvailable" ;
VAL_ 1429 Bms_DCFCPosRlyErrWarn 0 "No_Warning" 1 "Warning" 2 "Reserved" 3 "NotAvailable" ;
VAL_ 1429 Bms_CtctrDcnctRsnWarn 0 "No_Warning" 1 "Warning" 2 "Reserved" 3 "NotAvailable" ;
VAL_ 1429 Bms_ErrLevWarn 0 "No_Warning" 1 "Warning" 2 "Reserved" 3 "NotAvailable" ;
VAL_ 1429 Bms_FuseStsErrWarn 0 "No_Warning" 1 "Warning" 2 "Reserved" 3 "NotAvailable" ;
VAL_ 1429 Bms_HvilErrWarn 0 "No_Warning" 1 "Warning" 2 "Reserved" 3 "NotAvailable" ;
VAL_ 1429 Bms_LoBatWarn 0 "No_Warning" 1 "Warning" 2 "Reserved" 3 "NotAvailable" ;
VAL_ 1429 Bms_MainPosRlyErrWarn 0 "No_Warning" 1 "Warning" 2 "Reserved" 3 "NotAvailable" ;
VAL_ 1429 Bms_PackHvErrWarn 0 "No_Warning" 1 "Warning" 2 "Reserved" 3 "NotAvailable" ;
VAL_ 1429 Bms_PackInsuErrWarn 0 "No_Warning" 1 "Warning" 2 "Reserved" 3 "NotAvailable" ;
VAL_ 1429 Bms_PackLvErrWarn 0 "No_Warning" 1 "Warning" 2 "Reserved" 3 "NotAvailable" ;
VAL_ 1429 Bms_PackOvcurErrWarn 0 "No_Warning" 1 "Warning" 2 "Reserved" 3 "NotAvailable" ;
VAL_ 1429 Bms_PackTStsWarn 0 "No_Warning" 1 "Warning" 2 "Reserved" 3 "NotAvailable" ;
VAL_ 1429 Bms_PreChRlyErrWarn 0 "No_Warning" 1 "Warning" 2 "Reserved" 3 "NotAvailable" ;
VAL_ 1429 Bms_CellOverTErrWarn 0 "No_Warning" 1 "Warning" 2 "Reserved" 3 "NotAvailable" ;
VAL_ 1429 Bms_CellUnderTErrWarn 0 "No_Warning" 1 "Warning" 2 "Reserved" 3 "NotAvailable" ;
VAL_ 1429 Bms_RvsIDetChgFltWarn 0 "No_Warning" 1 "Warning" 2 "Reserved" 3 "NotAvailable" ;
VAL_ 1429 Bms_ScIFltWarn 0 "No_Warning" 1 "Warning" 2 "Reserved" 3 "NotAvailable" ;
VAL_ 1429 Bms_SocChngFastFltWarn 0 "No_Warning" 1 "Warning" 2 "Reserved" 3 "NotAvailable" ;
VAL_ 1429 Bms_SrvDueDetnWarn 0 "No_Warning" 1 "Warning" 2 "Reserved" 3 "NotAvailable" ;
VAL_ 1429 Bms_ThermRunawayWarn 0 "No_Warning" 1 "Warning" 2 "Reserved" 3 "NotAvailable" ;
VAL_ 1429 Bms_TotNegRlyErrWarn 0 "No_Warning" 1 "Warning" 2 "Reserved" 3 "NotAvailable" ;
VAL_ 1429 Bms_BatBalErrWarn 0 "No_Warning" 1 "Warning" 2 "Reserved" 3 "NotAvailable" ;
VAL_ 1429 Bms_BatReplWarn 0 "No_Warning" 1 "Warning" 2 "Reserved" 3 "NotAvailable" ;
VAL_ 1429 Bms_CellHvErrWarn 0 "No_Warning" 1 "Warning" 2 "Reserved" 3 "NotAvailable" ;
VAL_ 1429 Bms_CellLvErrWarn 0 "No_Warning" 1 "Warning" 2 "Reserved" 3 "NotAvailable" ;
VAL_ 1430 AlvCtr_DCMD_Warning 15 "Invalid Value" ;
VAL_ 1430 Pwind_DrvWndw_Warn 0 "No_Warning" 1 "Warning" 2 "Reserved" 3 "NotAvailable" ;
VAL_ 1430 CenLock_DrvrDoorAjar_Warn 0 "No_Warning" 1 "Warning" 2 "Reserved" 3 "NotAvailable" ;
VAL_ 1430 Pwd_DrvrDoor_Warn 0 "No_Warning" 1 "Warning" 2 "Reserved" 3 "NotAvailable" ;
VAL_ 1432 Ecpbk_SwtFlt 0 "Normal" 1 "Faulty" 2 "Reserved" 3 "NotAvailable" ;
VAL_ 1432 Ecpbk_InclndVehParkWarn 0 "No_Warning" 1 "Warning" 2 "Reserved" 3 "NotAvailable" ;
VAL_ 1432 Ecpbk_BrkFNotEnWarn 0 "No_Warning" 1 "Warning" 2 "Reserved" 3 "NotAvailable" ;
VAL_ 1432 Brb_RgnWarn 0 "No_Warning" 1 "Warning" 2 "Reserved" 3 "NotAvailable" ;
VAL_ 1432 Ecpbk_NotAppldDoorOpenWarn 0 "No_Warning" 1 "Warning" 2 "Reserved" 3 "NotAvailable" ;
VAL_ 1432 Ecpbk_RollrBenchModeWarn 0 "No_Warning" 1 "Warning" 2 "Reserved" 3 "NotAvailable" ;
VAL_ 1432 Ecpbk_AutoRelsWarn 0 "No_Warning" 1 "Warning" 2 "Reserved" 3 "NotAvailable" ;
VAL_ 1432 Ecpbk_RlsdMntnModeWarn 0 "No_Warning" 1 "Warning" 2 "Reserved" 3 "NotAvailable" ;
VAL_ 1432 Ecpbk_RlsdTwModeWarn 0 "No_Warning" 1 "Warning" 2 "Reserved" 3 "NotAvailable" ;
VAL_ 1432 Ecpbk_AutoAppldWarn 0 "No_Warning" 1 "Warning" 2 "Reserved" 3 "NotAvailable" ;
VAL_ 1432 Drvac_HillStrtAssiFltWarn 0 "No_Warning" 1 "Warning" 2 "Reserved" 3 "NotAvailable" ;
VAL_ 1432 Ebd_SysWarn 0 "No_Warning" 1 "Warning" 2 "Reserved" 3 "NotAvailable" ;
VAL_ 1432 Drvac_CorneringBrkCtlFltWarn 0 "No_Warning" 1 "Warning" 2 "Reserved" 3 "NotAvailable" ;
VAL_ 1432 Drvac_HdcWarn 0 "No_Warning" 1 "Warning" 2 "Reserved" 3 "NotAvailable" ;
VAL_ 1432 Drvac_FldLvlIndcrBrkFldWarn 0 "No_Warning" 1 "Warning" 2 "Reserved" 3 "NotAvailable" ;
VAL_ 1432 Drvac_TcsWarn 0 "No_Warning" 1 "Warning" 2 "Reserved" 3 "NotAvailable" ;
VAL_ 1432 Ecpbk_PsdBrkPedlToRelsEpbWarn 0 "No_Warning" 1 "Warning" 2 "Reserved" 3 "NotAvailable" ;
VAL_ 1432 Ecpbk_WarnLampSt 0 "No_Warning" 1 "Warning" 2 "Reserved" 3 "NotAvailable" ;
VAL_ 1432 Ecpbk_ParkBrkFltWarn 0 "No_Warning" 1 "Warning" 2 "Reserved" 3 "NotAvailable" ;
VAL_ 1432 Ecpbk_DegradedModeToBeRlsdWarn 0 "No_Warning" 1 "Warning" 2 "Reserved" 3 "NotAvailable" ;
VAL_ 1432 Ecpbk_DegradedModeRlsdWarn 0 "No_Warning" 1 "Warning" 2 "Reserved" 3 "NotAvailable" ;
VAL_ 1432 Abs_FltWarn 0 "No_Warning" 1 "Warning" 2 "Reserved" 3 "NotAvailable" ;
VAL_ 1434 Acchg_ObcErrWarn 0 "No_Warning" 1 "Warning" 2 "Reserved" 3 "NotAvailable" ;
VAL_ 1436 Stbwr_RdndtModeWarn 0 "No_Warning" 1 "Warning" 2 "Reserved" 3 "NotAvailable" ;
VAL_ 1437 Stbwr_HptcWarnSts 0 "Inactive" 1 "Active" 2 "Error" 3 "NotAvailable" ;
VAL_ 1437 Stbwr_SfaCluWarnLamp 0 "WL Off" 1 "WL Yellow" 2 "WL Red" 3 "NotAvailable" ;
VAL_ 1437 Stbwr_SteerAlgnmtWarn 0 "No_Warning" 1 "Warning" 2 "Reserved" 3 "NotAvailable" ;
VAL_ 1438 Stbwr_RdndtModeWarn_R 0 "No_Warning" 1 "Warning" 2 "Reserved" 3 "NotAvailable" ;
VAL_ 1439 Stbwr_HptcWarnSts_R 0 "Inactive" 1 "Active" 2 "Error" 3 "NotAvailable" ;
VAL_ 1439 Stbwr_SfaCluWarnLamp_R 0 "WL Off" 1 "WL Yellow" 2 "WL Red" 3 "NotAvailable" ;
VAL_ 1439 Stbwr_SteerAlgnmtWarn_R 0 "No_Warning" 1 "Warning" 2 "Reserved" 3 "NotAvailable" ;
VAL_ 1445 Hdlamp_LeLoBeamLampWarn 0 "No_Warning" 1 "Warning" 2 "Reserved" 3 "NotAvailable" ;
VAL_ 1445 Hdlamp_LeHiBeamLampWarn 0 "No_Warning" 1 "Warning" 2 "Reserved" 3 "NotAvailable" ;
VAL_ 1446 Hdlamp_RiLoBeamLampWarn 0 "No_Warning" 1 "Warning" 2 "Reserved" 3 "NotAvailable" ;
VAL_ 1446 Hdlamp_RiHiBeamLamp_Warn 0 "No_Warning" 1 "Warning" 2 "Reserved" 3 "NotAvailable" ;
VAL_ 1447 Sbm_CriticalSoCAlert_Warn 0 "No_Warning" 1 "Warning" 2 "Reserved" 3 "NotAvailable" ;
VAL_ 1447 Sbm_HealthStWarn 0 "No_Warning" 1 "Warning" 2 "Reserved" 3 "NotAvailable" ;
VAL_ 1447 Sbm_LvBatTSnsrFltSts_Warn 0 "No_Warning" 1 "Warning" 2 "Reserved" 3 "NotAvailable" ;
VAL_ 1448 AlvCtr_CCU_Warning 15 "Invalid Value" ;
VAL_ 1448 Ccsf_IoniserFlt_Warn 0 "No_Warning" 1 "Warning" 2 "Reserved" 3 "NotAvailable" ;
VAL_ 1448 Ccsf_FrntLeDuctFlapFlt_Warn 0 "No_Warning" 1 "Warning" 2 "Reserved" 3 "NotAvailable" ;
VAL_ 1448 Ccsf_ReRiTempMixFlapFlt_Warn 0 "No_Warning" 1 "Warning" 2 "Reserved" 3 "NotAvailable" ;
VAL_ 1448 Ccsf_ReLeTempMixFlapFlt_Warn 0 "No_Warning" 1 "Warning" 2 "Reserved" 3 "NotAvailable" ;
VAL_ 1448 Ccsf_FrntLeTempMixFlapFlt_Warn 0 "No_Warning" 1 "Warning" 2 "Reserved" 3 "NotAvailable" ;
VAL_ 1448 Ccsf_ReLeVentDuctFlapFlt_Warn 0 "No_Warning" 1 "Warning" 2 "Reserved" 3 "NotAvailable" ;
VAL_ 1448 Ccsf_FrntRiDuctFlapFlt_Warn 0 "No_Warning" 1 "Warning" 2 "Reserved" 3 "NotAvailable" ;
VAL_ 1448 Ccsf_ReLeFootDuctFlapFlt_Warn 0 "No_Warning" 1 "Warning" 2 "Reserved" 3 "NotAvailable" ;
VAL_ 1448 Ccsf_FrntLeVenDirSts 0 "NormallyOutwards" 1 "HarmonicsUpDown" 2 "HarmonicsSideBySide" 3 "NotAvailable" ;
VAL_ 1448 Ccsf_FrntRiTempMixFlapFltW_Warn 0 "No_Warning" 1 "Warning" 2 "Reserved" 3 "NotAvailable" ;
VAL_ 1452 Eds_FrntDeratWarn 0 "No_Warning" 1 "Warning" 2 "Reserved" 3 "NotAvailable" ;
VAL_ 1452 Eds_FrntErWarn 0 "No_Warning" 1 "Warning" 2 "Reserved" 3 "NotAvailable" ;
VAL_ 1452 Eds_FrntParkLockErrWarn 0 "No_Warning" 1 "Warning" 2 "Reserved" 3 "NotAvailable" ;
VAL_ 1453 Eds_ReParkLockErrWarn 0 "No_Warning" 1 "Warning" 2 "Reserved" 3 "NotAvailable" ;
VAL_ 1453 Eds_ReErrWarn 0 "No_Warning" 1 "Warning" 2 "Reserved" 3 "NotAvailable" ;
VAL_ 1453 Eds_ReDeratWarn 0 "No_Warning" 1 "Warning" 2 "Reserved" 3 "NotAvailable" ;
VAL_ 1454 AlvCtr_MFS_Warning 15 "Invalid Value" ;
VAL_ 1454 Mfsw_DrvModSwt_Warn 0 "No_Warning" 1 "Warning" 2 "Reserved" 3 "NotAvailable" ;
VAL_ 1454 MFS_ADAS_Swt_Warn 0 "No_Warning" 1 "Warning" 2 "Reserved" 3 "NotAvailable" ;
VAL_ 1454 MFS_Favorite_Swt_Warn 0 "No_Warning" 1 "Warning" 2 "Reserved" 3 "NotAvailable" ;
VAL_ 1454 MFS_Rim_Swt_Hi_Beam_Warn 0 "No_Warning" 1 "Warning" 2 "Reserved" 3 "NotAvailable" ;
VAL_ 1454 MFS_Rim_Swt_Wiper_Warn 0 "No_Warning" 1 "Warning" 2 "Reserved" 3 "NotAvailable" ;
VAL_ 1457 Hvsco_DcdcOperWarn 0 "No_Warning" 1 "Warning" 2 "Reserved" 3 "NotAvailable" ;
VAL_ 1459 AlvCtr_PSMD_Warning 15 "Invalid Value" ;
VAL_ 1459 SeatAdjmt_DrvFrntBackMotWarn 0 "No_Warning" 1 "Warning" 2 "Reserved" 3 "NotAvailable" ;
VAL_ 1459 SeatCfmt_DrvHeatgBackPadFailWarn 0 "No_Warning" 1 "Warning" 2 "Reserved" 3 "NotAvailable" ;
VAL_ 1459 SeatCfmt_DrvVentnSqubFanFailWarn 0 "No_Warning" 1 "Warning" 2 "Reserved" 3 "NotAvailable" ;
VAL_ 1459 SeatAdjmt_DrvHeiUpDwnMotWarn 0 "No_Warning" 1 "Warning" 2 "Reserved" 3 "NotAvailable" ;
VAL_ 1459 SeatAdjmt_DrvTiltUpDwnMotWarn 0 "No_Warning" 1 "Warning" 2 "Reserved" 3 "NotAvailable" ;
VAL_ 1459 SeatCfmt_DrvVentnCshnFanFailWarn 0 "No_Warning" 1 "Warning" 2 "Reserved" 3 "NotAvailable" ;
VAL_ 1459 SeatAdjmt_DrvAdjmtWarn 0 "No_Warning" 1 "Warning" 2 "Reserved" 3 "NotAvailable" ;
VAL_ 1459 SeatAdjmt_DrvReclUpDwnMotWarn 0 "No_Warning" 1 "Warning" 2 "Reserved" 3 "NotAvailable" ;
VAL_ 1459 SeatCfmt_DrvMassgFailWarn 0 "No_Warning" 1 "Warning" 2 "Reserved" 3 "NotAvailable" ;
VAL_ 1460 AlvCtr_PSMP_Warning 15 "Invalid Value" ;
VAL_ 1460 SeatAdjmt_PassTiltUpDwnMotWarn 0 "No_Warning" 1 "Warning" 2 "Reserved" 3 "NotAvailable" ;
VAL_ 1460 SeatAdjmt_PassAdjmtWarn 0 "No_Warning" 1 "Warning" 2 "Reserved" 3 "NotAvailable" ;
VAL_ 1460 SeatCfmt_PassVentnCshnFanFailWrn 0 "No_Warning" 1 "Warning" 2 "Reserved" 3 "NotAvailable" ;
VAL_ 1460 SeatAdjmt_PassReclUpDwnMotWarn 0 "No_Warning" 1 "Warning" 2 "Reserved" 3 "NotAvailable" ;
VAL_ 1460 SeatAdjmt_PassHeiUpDwnMotWarn 0 "No_Warning" 1 "Warning" 2 "Reserved" 3 "NotAvailable" ;
VAL_ 1460 SeatCfmt_PassVentnSqubFanFailWrn 0 "No_Warning" 1 "Warning" 2 "Reserved" 3 "NotAvailable" ;
VAL_ 1460 SeatCfmt_PassMassgFailWarn 0 "No_Warning" 1 "Warning" 2 "Reserved" 3 "NotAvailable" ;
VAL_ 1460 SeatAdjmt_PassFowdBawdMotWarn 0 "No_Warning" 1 "Warning" 2 "Reserved" 3 "NotAvailable" ;
VAL_ 1463 ReWhlSteer_WarnLamp 0 "Off" 1 "Yellow" 2 "YellowFlashing" 3 "Red" 4 "RedYellow" 5 "RedYellowFlashing" 6 "Error" 7 "NotAvailable" ;
VAL_ 1464 SeatCfmt_ReLeVentnCshnFanFailWrn 0 "No_Warning" 1 "Warning" 2 "Reserved" 3 "NotAvailable" ;
VAL_ 1464 SeatCfmt_ReLeVentnSqubFanFailWrn 0 "No_Warning" 1 "Warning" 2 "Reserved" 3 "NotAvailable" ;
VAL_ 1464 SeatCfmt_ReRiVentnCshnFanFailWrn 0 "No_Warning" 1 "Warning" 2 "Reserved" 3 "NotAvailable" ;
VAL_ 1464 SeatCfmt_ReRiVentnSqubFanFailWrn 0 "No_Warning" 1 "Warning" 2 "Reserved" 3 "NotAvailable" ;
VAL_ 1464 Acttg_TailGate_Warn 0 "No_Warning" 1 "Warning" 2 "Reserved" 3 "NotAvailable" ;
VAL_ 1464 ChrgrPort_IlmnLampW_Warn 0 "No_Warning" 1 "Warning" 2 "Reserved" 3 "NotAvailable" ;
VAL_ 1472 Relamp_ReLeTLGTurnIndcr_Warn 0 "No_Warning" 1 "Warning" 2 "Reserved" 3 "NotAvailable" ;
VAL_ 1472 Relamp_ReLeTLGPosnLamp_Warn 0 "No_Warning" 1 "Warning" 2 "Reserved" 3 "NotAvailable" ;
VAL_ 1472 Relamp_LeTLGBrkLamp_Warn 0 "No_Warning" 1 "Warning" 2 "Reserved" 3 "NotAvailable" ;
VAL_ 1473 Relamp_RiTLGBrkLamp_Warn 0 "No_Warning" 1 "Warning" 2 "Reserved" 3 "NotAvailable" ;
VAL_ 1473 Relamp_ReRiTLGTurnIndcr_Warn 0 "No_Warning" 1 "Warning" 2 "Reserved" 3 "NotAvailable" ;
VAL_ 1473 Relamp_ReRiTLGPosnLamp_Warn 0 "No_Warning" 1 "Warning" 2 "Reserved" 3 "NotAvailable" ;
VAL_ 1474 Relamp_LeBodyBrkLamp_Warn 0 "No_Warning" 1 "Warning" 2 "Reserved" 3 "NotAvailable" ;
VAL_ 1474 Relamp_ReLeBodyTurnIndcr_Warn 0 "No_Warning" 1 "Warning" 2 "Reserved" 3 "NotAvailable" ;
VAL_ 1475 Relamp_ReRiBodyTurnIndcr_Warn 0 "No_Warning" 1 "Warning" 2 "Reserved" 3 "NotAvailable" ;
VAL_ 1475 Relamp_RiBodyBrkLamp_Warn 0 "No_Warning" 1 "Warning" 2 "Reserved" 3 "NotAvailable" ;
VAL_ 1481 Hdlamp_FrntCentr_LeSignLamp_Warn 0 "No_Warning" 1 "Warning" 2 "Reserved" 3 "NotAvailable" ;
VAL_ 1481 Hdlamp_FrntCentr_RiSignLamp_Warn 0 "No_Warning" 1 "Warning" 2 "Reserved" 3 "NotAvailable" ;
VAL_ 1482 Hdlamp_FrntLeBodyTurnIndcr_Warn 0 "No_Warning" 1 "Warning" 2 "Reserved" 3 "NotAvailable" ;
VAL_ 1482 Hdlamp_LeDRLLamp_Warn 0 "No_Warning" 1 "Warning" 2 "Reserved" 3 "NotAvailable" ;
VAL_ 1482 Hdlamp_LeFrntPosnLamp_Warn 0 "No_Warning" 1 "Warning" 2 "Reserved" 3 "NotAvailable" ;
VAL_ 1483 Hdlamp_FrntRiBodyTurnIndcr_Warn 0 "No_Warning" 1 "Warning" 2 "Reserved" 3 "NotAvailable" ;
VAL_ 1483 Hdlamp_RiDRLLamp_Warn 0 "No_Warning" 1 "Warning" 2 "Reserved" 3 "NotAvailable" ;
VAL_ 1483 Hdlamp_RiFrntPosnLamp_Warn 0 "No_Warning" 1 "Warning" 2 "Reserved" 3 "NotAvailable" ;
VAL_ 1484 Relamp_Centr_RiSignLampSts 0 "No_Warning" 1 "Warning" 2 "Reserved" 3 "NotAvailable" ;
VAL_ 1484 Relamp_Centr_LeSignLampSts 0 "No_Warning" 1 "Warning" 2 "Reserved" 3 "NotAvailable" ;
